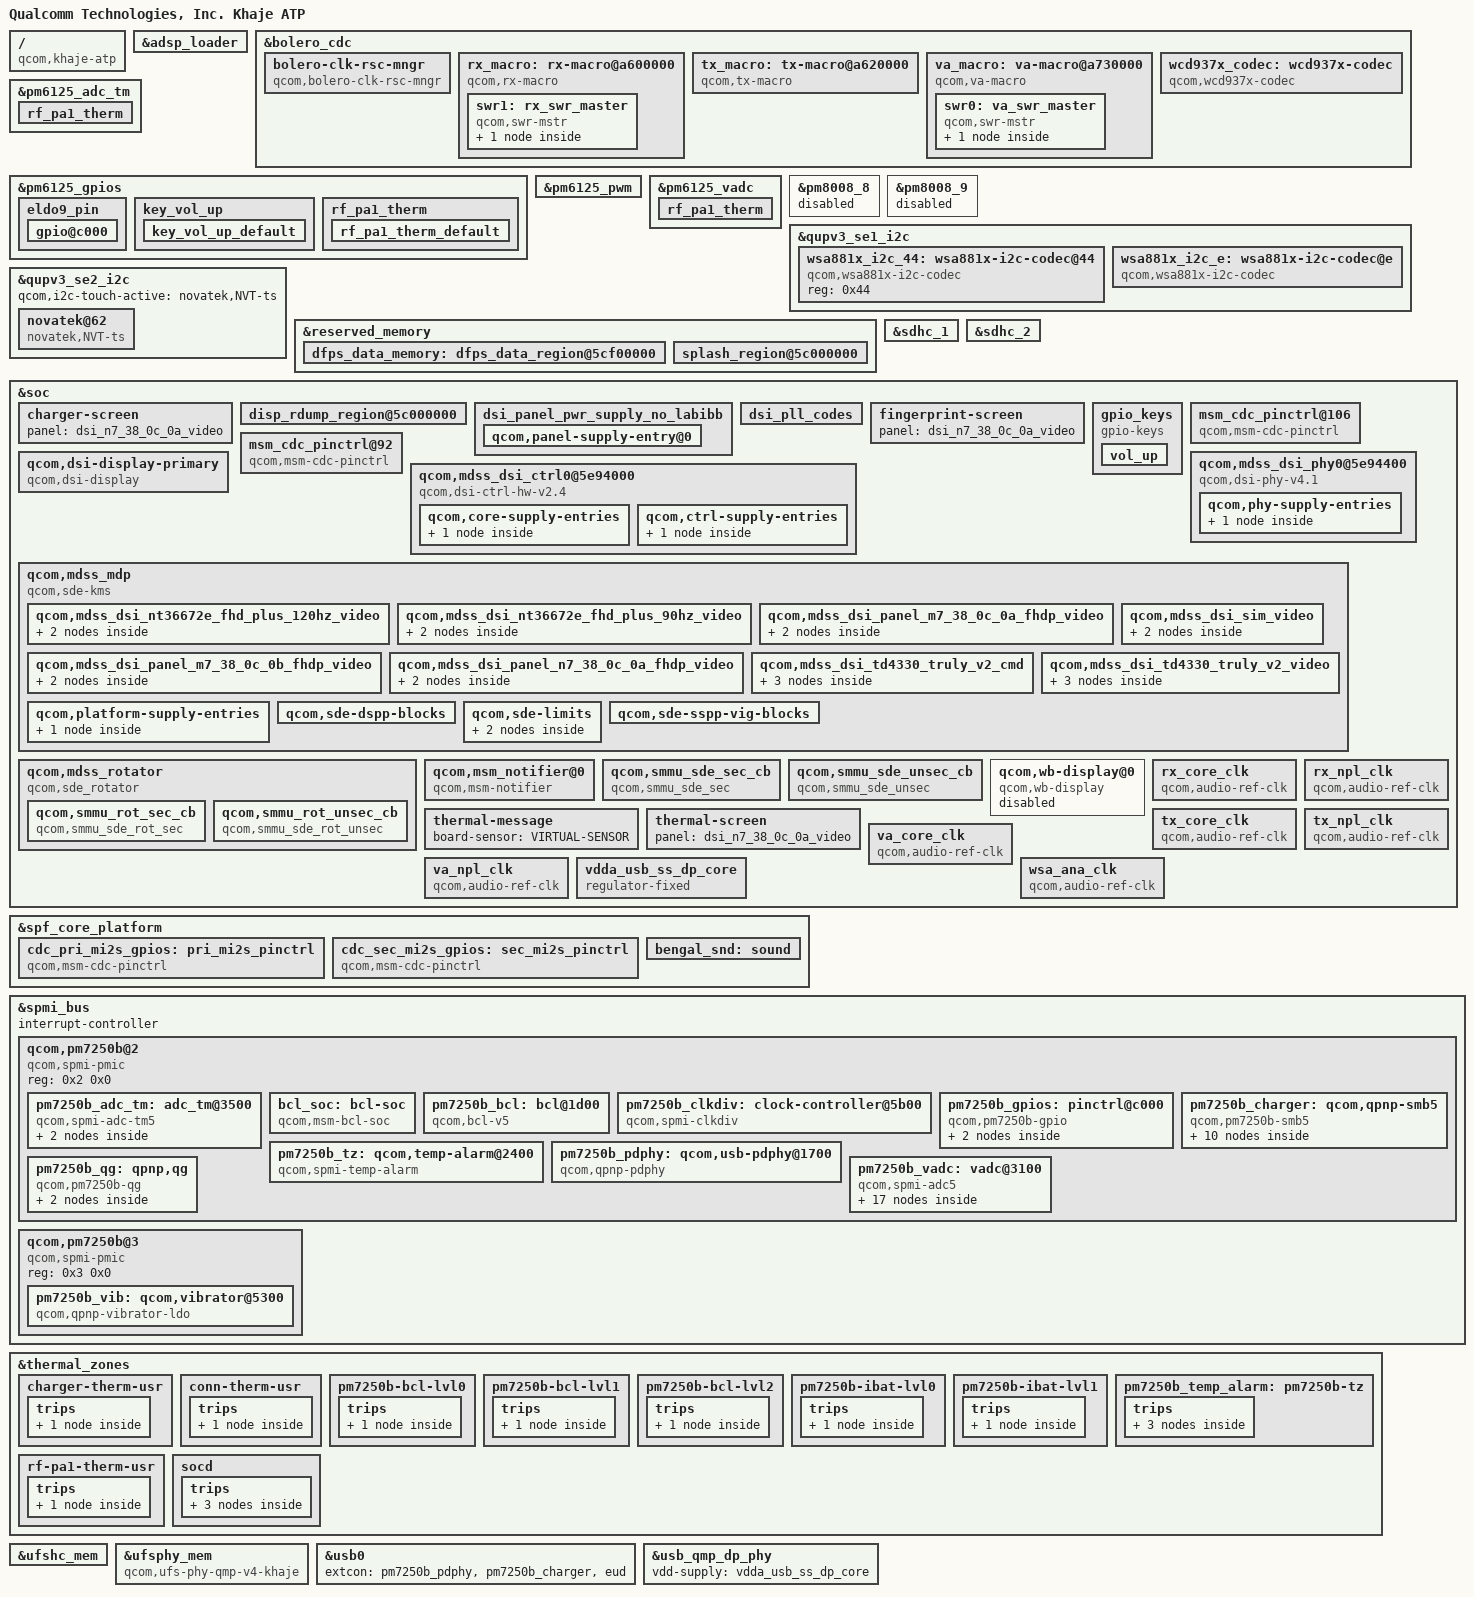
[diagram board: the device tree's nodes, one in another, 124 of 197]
/dts-v1/;

/ {
    compatible = "qcom,khaje-atp", "qcom,khaje", "qcom,atp";
    model = "Qualcomm Technologies, Inc. Khaje ATP";
    qcom,board-id = <0x21 0x0>;
    qcom,msm-id = <0x206 0x10000>;
    qcom,pmic-id = <0x2D 0x2E 0x0 0x0>;
};

&adsp_loader {
    adsp-fw-bit-values = <0x1>;
    adsp-fw-names = "adsp2";
    nvmem-cell-names = "adsp_variant";
    nvmem-cells = <&adsp_variant>;
};

&bolero_cdc {
    qcom,bolero-version = <0x5>;
    qcom,num-macros = <0x3>;
    bolero-clk-rsc-mngr {
        clock-names = "tx_core_clk", "tx_npl_clk", "rx_core_clk", "rx_npl_clk", "va_core_clk", "va_npl_clk";
        clocks = <&clock_audio_tx_1 0x0 &clock_audio_tx_2 0x0 &clock_audio_rx_1 0x0 &clock_audio_rx_2 0x0 &clock_audio_va_1 0x0 &clock_audio_va_2 0x0>;
        compatible = "qcom,bolero-clk-rsc-mngr";
        qcom,fs-gen-sequence = <0x3000 0x1 0x1 0x3004 0x3 0x3 0x3004 0x3 0x1 0x3080 0x2 0x2>;
        qcom,rx_mclk_mode_muxsel = <0xA5640D8>;
        qcom,va_mclk_mode_muxsel = "\nz";
    };
    rx_macro: rx-macro@a600000 {
        clock-names = "rx_core_clk", "rx_npl_clk";
        clocks = <&clock_audio_rx_1 0x0 &clock_audio_rx_2 0x0>;
        compatible = "qcom,rx-macro";
        qcom,default-clk-id = <0x0>;
        qcom,rx-bcl-pmic-params = [00 04 3E];
        qcom,rx-swr-gpios = <&rx_swr_gpios>;
        qcom,rx_mclk_mode_muxsel = <0xA5640D8>;
        reg = <0xA600000 0x0>;
        swr1: rx_swr_master {
            #address-cells = <0x2>;
            #size-cells = <0x0>;
            clock-names = "lpass_audio_hw_vote";
            clocks = <&lpass_audio_hw_vote 0x0>;
            compatible = "qcom,swr-mstr";
            interrupt-names = "swr_master_irq";
            interrupts = <0x0 0x129 0x4>;
            qcom,disable-div2-clk-switch = <0x1>;
            qcom,mipi-sdw-block-packing-mode = <0x1>;
            qcom,swr-clock-stop-mode0 = <0x1>;
            qcom,swr-master-version = <0x1060000>;
            qcom,swr-num-dev = <0x1>;
            qcom,swr-num-ports = <0x5>;
            qcom,swr-port-mapping = <0x1 0xE 0x1 0x1 0xF 0x2 0x2 0x12 0x1 0x3 0x10 0x1 0x3 0x11 0x2 0x4 0x13 0x1 0x5 0x14 0x1 0x5 0x15 0x2>;
            qcom,swr_master_id = <0x2>;
            qcom,swrm-hctl-reg = <0xA6A9098>;
            swrm-io-base = <0xA610000 0x0>;
            wcd937x_rx_slave: wcd937x-rx-slave {
                compatible = "qcom,wcd937x-slave";
                reg = <0xA 0x1170224>;
            };
        };
    };
    tx_macro: tx-macro@a620000 {
        clock-names = "tx_core_clk", "tx_npl_clk";
        clocks = <&clock_audio_tx_1 0x0 &clock_audio_tx_2 0x0>;
        compatible = "qcom,tx-macro";
        qcom,is-used-swr-gpio = <0x0>;
        qcom,tx-dmic-sample-rate = <0x249F00>;
        reg = <0xA620000 0x0>;
    };
    va_macro: va-macro@a730000 {
        clock-names = "lpass_audio_hw_vote";
        clocks = <&lpass_audio_hw_vote 0x0>;
        compatible = "qcom,va-macro";
        qcom,default-clk-id = <0x0>;
        qcom,is-used-swr-gpio = <0x1>;
        qcom,va-clk-mux-select = <0x1>;
        qcom,va-dmic-sample-rate = <0x927C0>;
        qcom,va-island-mode-muxsel = "\nz";
        qcom,va-swr-gpios = <&va_swr_gpios>;
        reg = <0xA730000 0x0>;
        swr0: va_swr_master {
            #address-cells = <0x2>;
            #size-cells = <0x0>;
            clock-names = "lpass_audio_hw_vote";
            clocks = <&lpass_audio_hw_vote 0x0>;
            compatible = "qcom,swr-mstr";
            interrupt-names = "swr_master_irq", "swr_wake_irq";
            interrupts = <0x0 0x128 0x4 0x0 0x4F 0x4>;
            qcom,is-always-on = <0x1>;
            qcom,mipi-sdw-block-packing-mode = <0x1>;
            qcom,swr-clock-stop-mode0 = <0x1>;
            qcom,swr-master-version = <0x1060000>;
            qcom,swr-mstr-irq-wakeup-capable = <0x1>;
            qcom,swr-num-dev = <0x1>;
            qcom,swr-num-ports = <0x3>;
            qcom,swr-port-mapping = <0x1 0x2E 0x1 0x1 0x2F 0x2 0x1 0x30 0x4 0x1 0x31 0x8 0x2 0x32 0x1 0x2 0x33 0x2 0x2 0x34 0x4 0x2 0x35 0x8 0x3 0x36 0x1 0x3 0x37 0x2 0x3 0x38 0x4 0x3 0x39 0x8>;
            qcom,swr-wakeup-required = <0x1>;
            qcom,swr_master_id = <0x3>;
            qcom,swrm-hctl-reg = <0xA7EC100>;
            swrm-io-base = <0xA740000 0x0>;
            wcd937x_tx_slave: wcd937x-tx-slave {
                compatible = "qcom,wcd937x-slave";
                reg = <0xA 0x1170223>;
            };
        };
    };
    wcd937x_codec: wcd937x-codec {
        cdc-vdd-buck-supply = <&L14A>;
        cdc-vdd-rxtx-supply = <&L9A>;
        cdc-vddpx-supply = <&L9A>;
        compatible = "qcom,wcd937x-codec";
        qcom,cdc-micbias1-mv = <0x708>;
        qcom,cdc-micbias2-mv = <0x708>;
        qcom,cdc-micbias3-mv = <0x708>;
        qcom,cdc-on-demand-supplies = "cdc-vdd-buck";
        qcom,cdc-static-supplies = "cdc-vdd-rxtx", "cdc-vddpx";
        qcom,cdc-vdd-buck-current = <0x9EB10>;
        qcom,cdc-vdd-buck-voltage = <0x1B7740 0x1B7740>;
        qcom,cdc-vdd-rxtx-current = <0x2710>;
        qcom,cdc-vdd-rxtx-voltage = <0x1B7740 0x1B7740>;
        qcom,cdc-vddpx-current = <0x4E20>;
        qcom,cdc-vddpx-voltage = <0x1B7740 0x1B7740>;
        qcom,rx-slave = <&wcd937x_rx_slave>;
        qcom,rx_swr_ch_map = <0x0 0xE 0x1 0x0 0xE 0x0 0xF 0x2 0x0 0xF 0x1 0x12 0x1 0x0 0x12 0x2 0x10 0x1 0x0 0x10 0x2 0x11 0x2 0x0 0x11 0x3 0x13 0x1 0x0 0x13 0x4 0x14 0x1 0x0 0x14 0x4 0x15 0x2 0x0 0x15>;
        qcom,split-codec = <0x1>;
        qcom,swr-tx-port-params = <0x1 0x0 0x0 0x1 0x1 0x0 0x1 0x0 0x0 0x1 0x1 0x0 0x1 0x0 0x1 0x0 0x0 0x1 0x2 0x0 0x1 0x0 0x2 0x0 0x1 0x0 0x1 0x0 0x1 0x0 0x1 0x0>;
        qcom,tx-slave = <&wcd937x_tx_slave>;
        qcom,tx_swr_ch_map = <0x0 0x1E 0x1 0x493E00 0x2E 0x1 0x1F 0x1 0x493E00 0x32 0x1 0x20 0x2 0x493E00 0x33 0x2 0x22 0x1 0x0 0x31 0x2 0x23 0x2 0x0 0x32 0x2 0x1D 0x4 0x493E00 0x33 0x3 0x24 0x1 0x0 0x34 0x3 0x25 0x2 0x0 0x35 0x3 0x26 0x4 0x0 0x36 0x3 0x27 0x8 0x0 0x37>;
        qcom,wcd-rst-gpio-node = <&wcd937x_rst_gpio>;
    };
};

&pm6125_adc_tm {
    status = "ok";
    rf_pa1_therm {
        io-channels = <&pm6125_vadc 0x55>;
        qcom,hw-settle-time-us = <0xC8>;
        qcom,ratiometric;
        reg = <0x3>;
    };
};

&pm6125_gpios {
    eldo9_pin {
        gpio@c000 {
            bias-disable;
            function = "normal";
            output-high;
            pins = "gpio1";
            power-source = <0x0>;
            qcom,drive-strength = <0x2>;
        };
    };
    key_vol_up {
        key_vol_up_default: key_vol_up_default {
            bias-pull-up;
            function = "normal";
            input-enable;
            pins = "gpio5";
            power-source = <0x0>;
        };
    };
    rf_pa1_therm {
        rf_pa1_therm_default: rf_pa1_therm_default {
            bias-high-impedance;
            pins = "gpio7";
        };
    };
};

&pm6125_pwm {
    status = "okay";
};

&pm6125_vadc {
    pinctrl-0 = <&camera_therm_default &emmc_therm_default &rf_pa1_therm_default>;
    rf_pa1_therm {
        label = "rf_pa1_therm";
        qcom,hw-settle-time = <0xC8>;
        qcom,pre-scaling = <0x1 0x1>;
        qcom,ratiometric;
        reg = <0x55>;
    };
};

&pm8008_8 {
    status = "disabled";
};

&pm8008_9 {
    status = "disabled";
};

&qupv3_se1_i2c {
    wsa881x_i2c_44: wsa881x-i2c-codec@44 {
        compatible = "qcom,wsa881x-i2c-codec";
        reg = <0x44>;
    };
    wsa881x_i2c_e: wsa881x-i2c-codec@e {
        clock-names = "wsa_mclk";
        clocks = <&wsa881x_analog_clk 0x0>;
        compatible = "qcom,wsa881x-i2c-codec";
        qcom,wsa-analog-clk-gpio = <&wsa881x_analog_clk_gpio>;
        qcom,wsa-analog-reset-gpio = <&wsa881x_analog_reset_gpio>;
        qcom,wsa-prefix = "SpkrMono";
        reg = <0xE>;
    };
};

&qupv3_se2_i2c {
    qcom,i2c-touch-active = "novatek,NVT-ts";
    status = "okay";
    novatek@62 {
        interrupt-parent = <&tlmm>;
        interrupts = <0x50 0x2008>;
        novatek,irq-gpio = <&tlmm 0x50 0x2008>;
        novatek,reset-gpio = <&tlmm 0x56 0x0>;
        pinctrl-0 = <&ts_int_active &ts_reset_active>;
        pinctrl-1 = <&ts_int_suspend &ts_reset_suspend>;
        pinctrl-2 = <&ts_release>;
        pinctrl-names = "pmx_ts_active", "pmx_ts_suspend", "pmx_ts_release";
        reg = <0x62>;
        status = "ok";
        compatible = "novatek,NVT-ts";
        panel = <&dsi_nt36672e_fhd_plus_90hz_video>;
    };
};

&reserved_memory {
    dfps_data_memory: dfps_data_region@5cf00000 {
        label = "dfps_data_region";
        reg = <0x0 0x5CF00000 0x0 0x100000>;
    };
    splash_region@5c000000 {
        label = "cont_splash_region";
        reg = <0x0 0x5C000000 0x0 0xF00000>;
    };
};

&sdhc_1 {
    pinctrl-0 = <&sdc1_on>;
    pinctrl-1 = <&sdc1_off>;
    pinctrl-names = "active", "sleep";
    qcom,vdd-current-level = <0x0 0x8B290>;
    qcom,vdd-io-always-on;
    qcom,vdd-io-current-level = <0x0 0x4F588>;
    qcom,vdd-io-lpm-sup;
    qcom,vdd-io-voltage-level = <0x1B7740 0x1B7740>;
    qcom,vdd-voltage-level = <0x2D2A80 0x2D2A80>;
    status = "ok";
    vdd-io-supply = <&L11A>;
    vdd-supply = <&L24A>;
};

&sdhc_2 {
    cd-gpios = <&tlmm 0x58 0x1>;
    pinctrl-0 = <&sdc2_on>;
    pinctrl-1 = <&sdc2_off>;
    pinctrl-names = "active", "sleep";
    qcom,vdd-current-level = <0x0 0xC3500>;
    qcom,vdd-io-bias-current-level = <0x0 0x1770>;
    qcom,vdd-io-bias-voltage-level = <0x132A40 0x132A40>;
    qcom,vdd-io-current-level = <0x0 0x55F0>;
    qcom,vdd-io-voltage-level = <0x1B7740 0x2D2A80>;
    qcom,vdd-voltage-level = <0x2D2A80 0x2D2A80>;
    status = "ok";
    vdd-io-bias-supply = <&L7A>;
    vdd-io-supply = <&L5A>;
    vdd-supply = <&L22A>;
};

&soc {
    charger-screen {
        panel = <&dsi_n7_38_0c_0a_video>;
    };
    disp_rdump_region@5c000000 {
        label = "disp_rdump_region";
        reg = <0x0 0x5C000000 0x0 0xF00000>;
    };
    dsi_panel_pwr_supply_no_labibb {
        #address-cells = <0x1>;
        #size-cells = <0x0>;
        qcom,panel-supply-entry@0 {
            qcom,supply-disable-load = <0x50>;
            qcom,supply-enable-load = <0xF230>;
            qcom,supply-max-voltage = <0x1B7740>;
            qcom,supply-min-voltage = <0x1B7740>;
            qcom,supply-name = "vddio";
            qcom,supply-post-on-sleep = <0x14>;
            reg = <0x0>;
        };
    };
    dsi_pll_codes {
        label = "dsi_pll_codes";
        reg = <0x0 0x0 0x0 0x0 0x0 0x0 0x0 0x0 0x0 0x0 0x0 0x0 0x0 0x0 0x0 0x0 0x0 0x0 0x0 0x0 0x0 0x0 0x0 0x0 0x0 0x0 0x0 0x0 0x0 0x0 0x0 0x0 0x0 0x0 0x0 0x0 0x0 0x0 0x0 0x0 0x0 0x0 0x0 0x0 0x0 0x0 0x0 0x0 0x0 0x0 0x0 0x0 0x0 0x0 0x0 0x0 0x0 0x0 0x0 0x0 0x0 0x0 0x0 0x0 0x0 0x0 0x0 0x0 0x0 0x0 0x0 0x0 0x0 0x0 0x0 0x0 0x0 0x0 0x0 0x0 0x0 0x0 0x0 0x0 0x0 0x0 0x0 0x0 0x0 0x0 0x0 0x0 0x0 0x0 0x0 0x0 0x0 0x0 0x0 0x0 0x0 0x0 0x0 0x0 0x0 0x0 0x0 0x0 0x0 0x0 0x0 0x0 0x0 0x0 0x0 0x0 0x0 0x0 0x0 0x0 0x0 0x0 0x0 0x0 0x0 0x0 0x0 0x0>;
    };
    fingerprint-screen {
        panel = <&dsi_n7_38_0c_0a_video>;
    };
    gpio_keys {
        compatible = "gpio-keys";
        label = "gpio-keys";
        pinctrl-0 = <&key_vol_up_default>;
        pinctrl-names = "default";
        vol_up {
            debounce-interval = <0xF>;
            gpio-key,wakeup;
            gpios = <&pm6125_gpios 0x5 0x1>;
            label = "volume_up";
            linux,can-disable;
            linux,code = <0x73>;
            linux,input-type = <0x1>;
        };
    };
    msm_cdc_pinctrl@106 {
        #gpio-cells = <0x0>;
        compatible = "qcom,msm-cdc-pinctrl";
        pinctrl-0 = <&spkr_1_sd_n_active>;
        pinctrl-1 = <&spkr_1_sd_n_sleep>;
        pinctrl-names = "aud_active", "aud_sleep";
    };
    msm_cdc_pinctrl@92 {
        #gpio-cells = <0x0>;
        compatible = "qcom,msm-cdc-pinctrl";
        pinctrl-0 = <&wcd937x_reset_active>;
        pinctrl-1 = <&wcd937x_reset_sleep>;
        pinctrl-names = "aud_active", "aud_sleep";
    };
    qcom,dsi-display-primary {
        clock-names = "pll_byte_clk0", "pll_dsi_clk0", "mdp_core_clk";
        clocks = <&mdss_dsi_phy0 0x0 &mdss_dsi_phy0 0x1 &dispcc 0x8>;
        compatible = "qcom,dsi-display";
        label = "primary";
        pinctrl-0 = <&sde_dsi_active &sde_te_active &disp_lcd_bias_en_default>;
        pinctrl-1 = <&sde_dsi_suspend &sde_te_suspend>;
        pinctrl-names = "panel_active", "panel_suspend";
        qcom,dsi-ctrl = <&mdss_dsi0>;
        qcom,dsi-default-panel = <&dsi_nt36672e_fhd_plus_90hz_video>;
        qcom,dsi-phy = <&mdss_dsi_phy0>;
        qcom,mdp = <&mdss_mdp>;
        qcom,panel-te-source = <0x0>;
        qcom,platform-te-gpio = <&tlmm 0x51 0x0>;
        vddio-supply = <&L9A>;
    };
    qcom,mdss_dsi_ctrl0@5e94000 {
        cell-index = <0x0>;
        clock-names = "byte_clk", "byte_clk_rcg", "byte_intf_clk", "pixel_clk", "pixel_clk_rcg", "esc_clk";
        clocks = <&dispcc 0x2 &dispcc 0x3 &dispcc 0x5 &dispcc 0xC &dispcc 0xD &dispcc 0x6>;
        compatible = "qcom,dsi-ctrl-hw-v2.4";
        frame-threshold-time-us = <0x3E8>;
        interrupt-parent = <&mdss_mdp>;
        interrupts = <0x4 0x0>;
        label = "dsi-ctrl-0";
        refgen-supply = <&refgen>;
        reg = <0x5E94000 0x400 0x5F08000 0x4 0x5E6B800 0x300>;
        reg-names = "dsi_ctrl", "disp_cc_base", "mdp_intf_base";
        vdda-1p2-supply = <&L18A>;
        qcom,core-supply-entries {
            #address-cells = <0x1>;
            #size-cells = <0x0>;
            qcom,core-supply-entry@0 {
                qcom,supply-disable-load = <0x0>;
                qcom,supply-enable-load = <0x0>;
                qcom,supply-max-voltage = <0x0>;
                qcom,supply-min-voltage = <0x0>;
                qcom,supply-name = "refgen";
                reg = <0x0>;
            };
        };
        qcom,ctrl-supply-entries {
            #address-cells = <0x1>;
            #size-cells = <0x0>;
            qcom,ctrl-supply-entry@0 {
                qcom,supply-disable-load = <0x0>;
                qcom,supply-enable-load = <0x5528>;
                qcom,supply-max-voltage = <0x124F80>;
                qcom,supply-min-voltage = <0x124F80>;
                qcom,supply-name = "vdda-1p2";
                reg = <0x0>;
            };
        };
    };
    qcom,mdss_dsi_phy0@5e94400 {
        #clock-cells = <0x1>;
        cell-index = <0x0>;
        compatible = "qcom,dsi-phy-v4.1";
        label = "dsi-phy-0";
        memory-region = <&dfps_data_memory>;
        pll-label = "dsi_pll_5nm";
        pll_codes_region = <&dsi_pll_codes_data>;
        qcom,dsi-pll-ssc-en;
        qcom,dsi-pll-ssc-mode = "down-spread";
        qcom,platform-lane-config = <0xA0A 0xA0A 0xA0A 0xA0A 0x8A8A>;
        qcom,platform-regulator-settings = [1D 1D 1D 1D 1D];
        qcom,platform-strength-ctrl = [55 03 55 03 55 03 55 03 55 00];
        reg = <0x5E94400 0x800 0x5E94900 0x264 0x5E94200 0x100>;
        reg-names = "dsi_phy", "pll_base", "dyn_refresh_base";
        vdda-0p9-supply = <&L4A>;
        qcom,phy-supply-entries {
            #address-cells = <0x1>;
            #size-cells = <0x0>;
            qcom,phy-supply-entry@0 {
                qcom,supply-disable-load = <0x0>;
                qcom,supply-enable-load = <0x8CA0>;
                qcom,supply-max-voltage = <0xD6D80>;
                qcom,supply-min-voltage = <0xD6D80>;
                qcom,supply-name = "vdda-0p9";
                reg = <0x0>;
            };
        };
    };
    qcom,mdss_mdp {
        #cooling-cells = <0x2>;
        #interrupt-cells = <0x1>;
        #list-cells = <0x1>;
        #power-domain-cells = <0x0>;
        clock-max-rate = <0x0 0x0 0x0 0x0 0x2160EC00 0x124F800 0x2160EC00>;
        clock-names = "gcc_bus", "throttle_clk", "div_clk", "iface_clk", "core_clk", "vsync_clk", "lut_clk";
        clock-rate = <0x0 0x0 0x0 0x0 0x16D41DC0 0x124F800 0x16D41DC0>;
        clocks = <&gcc 0x3E &gcc 0x40 &gcc 0x3D &dispcc 0x0 &dispcc 0x8 &dispcc 0x12 &dispcc 0xA>;
        compatible = "qcom,sde-kms";
        connectors = <&sde_dsi &smmu_sde_sec &smmu_sde_unsec>;
        interconnect-names = "qcom,sde-data-bus0", "qcom,sde-reg-bus";
        interconnects = <&mmrt_virt 0xE &bimc 0x200 &bimc 0x0 &config_noc 0x212>;
        interrupt-controller;
        interrupts = <0x0 0xBA 0x4>;
        qcom,sde-axi-bus-width = <0x10>;
        qcom,sde-cdp-setting = <0x1 0x1 0x1 0x0>;
        qcom,sde-csc-type = "csc-10bit";
        qcom,sde-ctl-display-pref = "primary";
        qcom,sde-ctl-off = <0x2000>;
        qcom,sde-ctl-size = <0x1DC>;
        qcom,sde-danger-lut = <0xFF 0xFFFF 0x0 0x0 0xFFFF>;
        qcom,sde-dither-off = <0x30E0>;
        qcom,sde-dither-size = <0x20>;
        qcom,sde-dither-version = <0x10000>;
        qcom,sde-dram-channels = <0x1>;
        qcom,sde-dsc-off = <0x81000>;
        qcom,sde-dsc-size = <0x140>;
        qcom,sde-dspp-off = <0x55000>;
        qcom,sde-dspp-rc-mem-size = <0xAA0>;
        qcom,sde-dspp-rc-off = <0x15800>;
        qcom,sde-dspp-rc-size = <0x100>;
        qcom,sde-dspp-rc-version = <0x10000>;
        qcom,sde-dspp-size = <0x1800>;
        qcom,sde-dspp-top-off = <0x1300>;
        qcom,sde-dspp-top-size = <0x80>;
        qcom,sde-has-cdp;
        qcom,sde-has-dim-layer;
        qcom,sde-has-idle-pc;
        qcom,sde-highest-bank-bit = <0x1>;
        qcom,sde-ib-bw-vote = <0x249F00 0x0 0x186A00>;
        qcom,sde-intf-off = <0x0 0x6B800>;
        qcom,sde-intf-size = <0x2C0>;
        qcom,sde-intf-tear-irq-off = <0x0 0x6E800>;
        qcom,sde-intf-type = "none", "dsi";
        qcom,sde-len = <0x494>;
        qcom,sde-max-bw-high-kbps = <0x419CE0>;
        qcom,sde-max-bw-low-kbps = <0x30D400>;
        qcom,sde-max-per-pipe-bw-high-kbps = <0x30D400 0x30D400>;
        qcom,sde-max-per-pipe-bw-kbps = <0x30D400 0x30D400>;
        qcom,sde-min-core-ib-kbps = <0x249F00>;
        qcom,sde-min-dram-ib-kbps = <0x186A00>;
        qcom,sde-min-llcc-ib-kbps = <0x0>;
        qcom,sde-mixer-blend-op-off = <0x20 0x38 0x50 0x68 0x80 0x98 0xB0 0xC8 0xE0 0xF8 0x110>;
        qcom,sde-mixer-blendstages = <0x4>;
        qcom,sde-mixer-display-pref = "primary";
        qcom,sde-mixer-linewidth = <0x800>;
        qcom,sde-mixer-off = <0x45000>;
        qcom,sde-mixer-pair-mask = <0x0>;
        qcom,sde-mixer-size = <0x320>;
        qcom,sde-mixer-stage-base-layer;
        qcom,sde-num-mnoc-ports = <0x1>;
        qcom,sde-num-nrt-paths = <0x0>;
        qcom,sde-off = <0x1000>;
        qcom,sde-panic-per-pipe;
        qcom,sde-pp-off = <0x71000>;
        qcom,sde-pp-size = <0xD4>;
        qcom,sde-qos-cpu-dma-latency = <0x12C>;
        qcom,sde-qos-cpu-irq-latency = <0x12C>;
        qcom,sde-qos-cpu-mask = <0x3>;
        qcom,sde-qos-lut-linear = <0x0 0x112222 0x22335777>;
        qcom,sde-qos-lut-macrotile = <0x0 0x112233 0x44556677>;
        qcom,sde-qos-lut-macrotile-qseed = <0x0 0x112233 0x66777777>;
        qcom,sde-qos-lut-nrt = <0x0 0x0 0x0>;
        qcom,sde-qseed-scalar-version = <0x3000>;
        qcom,sde-qseed-sw-lib-rev = "qseedv3lite";
        qcom,sde-reg-bus,vectors-KBps = <0x0 0x0 0x0 0x12C00 0x0 0x249F0 0x0 0x493E0>;
        qcom,sde-safe-lut-linear = <0x0 0xFFF0>;
        qcom,sde-safe-lut-macrotile = <0x0 0xFF00>;
        qcom,sde-safe-lut-macrotile-qseed = <0x0 0xFF00>;
        qcom,sde-safe-lut-nrt = <0x0 0xFFFF>;
        qcom,sde-secure-sid-mask = <0x421>;
        qcom,sde-smart-dma-rev = "smart_dma_v2p5";
        qcom,sde-sspp-clk-ctrl = <0x2AC 0x0 0x2AC 0x8>;
        qcom,sde-sspp-csc-off = <0x1A00>;
        qcom,sde-sspp-excl-rect = <0x1 0x1>;
        qcom,sde-sspp-linewidth = <0x870>;
        qcom,sde-sspp-off = <0x5000 0x25000>;
        qcom,sde-sspp-qseed-off = <0xA00>;
        qcom,sde-sspp-smart-dma-priority = <0x2 0x1>;
        qcom,sde-sspp-src-size = <0x1F8>;
        qcom,sde-sspp-type = "vig", "dma";
        qcom,sde-sspp-xin-id = <0x0 0x1>;
        qcom,sde-ubwc-static = <0x11F>;
        qcom,sde-ubwc-swizzle = <0x7>;
        qcom,sde-ubwc-version = <0x10000000>;
        qcom,sde-vbif-id = <0x0>;
        qcom,sde-vbif-memtype-0 = <0x3 0x3 0x3 0x3 0x3 0x3 0x3 0x3>;
        qcom,sde-vbif-memtype-1 = <0x3 0x3 0x3 0x3 0x3 0x3>;
        qcom,sde-vbif-off = <0x0>;
        qcom,sde-vbif-qos-nrt-remap = <0x3 0x3 0x3 0x3 0x3 0x3 0x3 0x3 0x3 0x3 0x3 0x3 0x3 0x3 0x3 0x3>;
        qcom,sde-vbif-qos-rt-remap = <0x3 0x3 0x4 0x4 0x5 0x5 0x6 0x6 0x3 0x3 0x4 0x4 0x5 0x5 0x6 0x6>;
        qcom,sde-vbif-size = <0x2008>;
        reg = <0x5E00000 0x8F030 0x5EB0000 0x2008 0x5E8F000 0x30>;
        reg-names = "mdp_phys", "vbif_phys", "sid_phys";
        sde-vdd-supply = <&mdss_core_gdsc>;
        qcom,mdss_dsi_nt36672e_fhd_plus_120hz_video {
            qcom,adjust-timer-wakeup-ms = <0x1>;
            qcom,dsi-ctrl-num = <0x0>;
            qcom,dsi-phy-num = <0x0>;
            qcom,dsi-select-clocks = "pll_byte_clk0", "pll_dsi_clk0";
            qcom,esd-check-enabled;
            qcom,mdss-dsi-bllp-eof-power-mode;
            qcom,mdss-dsi-bllp-power-mode;
            qcom,mdss-dsi-border-color = <0x0>;
            qcom,mdss-dsi-bpp = <0x18>;
            qcom,mdss-dsi-dma-trigger = "trigger_sw";
            qcom,mdss-dsi-lane-0-state;
            qcom,mdss-dsi-lane-1-state;
            qcom,mdss-dsi-lane-2-state;
            qcom,mdss-dsi-lane-3-state;
            qcom,mdss-dsi-mdp-trigger = "none";
            qcom,mdss-dsi-panel-blackness-level = <0x1361>;
            qcom,mdss-dsi-panel-hdr-color-primaries = <0x3A98 0x3E80 0x83D6 0x3DB8 0x33C2 0x8692 0x1D4C 0xBB8>;
            qcom,mdss-dsi-panel-hdr-enabled;
            qcom,mdss-dsi-panel-name = "nt36672e fhd plus 120Hz Video panel";
            qcom,mdss-dsi-panel-peak-brightness = <0x626B50>;
            qcom,mdss-dsi-panel-status-check-mode = "reg_read";
            qcom,mdss-dsi-panel-status-command = <0x6010001 0x10A>;
            qcom,mdss-dsi-panel-status-command-state = "dsi_lp_mode";
            qcom,mdss-dsi-panel-status-read-length = <0x1>;
            qcom,mdss-dsi-panel-status-value = <0x9C>;
            qcom,mdss-dsi-panel-type = "dsi_video_mode";
            qcom,mdss-dsi-reset-sequence = <0x1 0xA 0x0 0xA 0x1 0xA>;
            qcom,mdss-dsi-stream = <0x0>;
            qcom,mdss-dsi-traffic-mode = "burst_mode";
            qcom,mdss-dsi-tx-eot-append;
            qcom,mdss-dsi-virtual-channel-id = <0x0>;
            qcom,mdss-dsi-display-timings {
                timing@0 {
                    qcom,compression-mode = "dsc";
                    qcom,default-topology-index = <0x0>;
                    qcom,display-topology = <0x1 0x1 0x1>;
                    qcom,mdss-dsc-bit-per-component = <0x8>;
                    qcom,mdss-dsc-bit-per-pixel = <0x8>;
                    qcom,mdss-dsc-block-prediction-enable;
                    qcom,mdss-dsc-slice-height = <0x8>;
                    qcom,mdss-dsc-slice-per-pkt = <0x1>;
                    qcom,mdss-dsc-slice-width = <0x21C>;
                    qcom,mdss-dsi-h-back-porch = <0x3C>;
                    qcom,mdss-dsi-h-front-porch = <0x4C>;
                    qcom,mdss-dsi-h-pulse-width = <0xA>;
                    qcom,mdss-dsi-h-sync-skew = <0x0>;
                    qcom,mdss-dsi-off-command = <0x5010000 0x10000128 0x5010000 0x32000110>;
                    qcom,mdss-dsi-off-command-state = "dsi_lp_mode";
                    qcom,mdss-dsi-on-command = [15 01 00 00 00 00 02 FB 01 15 01 00 00 00 00 02 B0 00 15 01 00 00 00 00 02 C0 03 39 01 00 00 00 00 11 C1 89 28 00 08 00 AA 02 0E 00 2B 00 07 0D B7 0C B7 39 01 00 00 00 00 03 C2 1B A0 15 01 00 00 00 00 02 FF 20 15 01 00 00 00 00 02 FB 01 15 01 00 00 00 00 02 01 66 15 01 00 00 00 00 02 06 40 15 01 00 00 00 00 02 07 38 15 01 00 00 00 00 02 2F 83 15 01 00 00 00 00 02 69 91 15 01 00 00 00 00 02 95 D1 15 01 00 00 00 00 02 96 D1 15 01 00 00 00 00 02 F2 64 15 01 00 00 00 00 02 F4 64 15 01 00 00 00 00 02 F6 64 15 01 00 00 00 00 02 F8 64 15 01 00 00 00 00 02 89 1C 15 01 00 00 00 00 02 8A 1C 15 01 00 00 00 00 02 8B 1C 15 01 00 00 00 00 02 8C 1C 15 01 00 00 00 00 02 FF 24 15 01 00 00 00 00 02 FB 01 15 01 00 00 00 00 02 01 0F 15 01 00 00 00 00 02 03 0C 15 01 00 00 00 00 02 05 1D 15 01 00 00 00 00 02 08 2F 15 01 00 00 00 00 02 09 2E 15 01 00 00 00 00 02 0A 2D 15 01 00 00 00 00 02 0B 2C 15 01 00 00 00 00 02 11 17 15 01 00 00 00 00 02 12 13 15 01 00 00 00 00 02 13 15 15 01 00 00 00 00 02 15 14 15 01 00 00 00 00 02 16 16 15 01 00 00 00 00 02 17 18 15 01 00 00 00 00 02 1B 01 15 01 00 00 00 00 02 1D 1D 15 01 00 00 00 00 02 20 2F 15 01 00 00 00 00 02 21 2E 15 01 00 00 00 00 02 22 2D 15 01 00 00 00 00 02 23 2C 15 01 00 00 00 00 02 29 17 15 01 00 00 00 00 02 2A 13 15 01 00 00 00 00 02 2B 15 15 01 00 00 00 00 02 2F 14 15 01 00 00 00 00 02 30 16 15 01 00 00 00 00 02 31 18 15 01 00 00 00 00 02 32 04 15 01 00 00 00 00 02 34 10 15 01 00 00 00 00 02 35 1F 15 01 00 00 00 00 02 36 1F 15 01 00 00 00 00 02 4D 14 15 01 00 00 00 00 02 4E 36 15 01 00 00 00 00 02 4F 36 15 01 00 00 00 00 02 53 36 15 01 00 00 00 00 02 71 30 15 01 00 00 00 00 02 79 11 15 01 00 00 00 00 02 7A 82 15 01 00 00 00 00 02 7B 8F 15 01 00 00 00 00 02 7D 04 15 01 00 00 00 00 02 80 04 15 01 00 00 00 00 02 81 04 15 01 00 00 00 00 02 82 13 15 01 00 00 00 00 02 84 31 15 01 00 00 00 00 02 85 00 15 01 00 00 00 00 02 86 00 15 01 00 00 00 00 02 87 00 15 01 00 00 00 00 02 90 13 15 01 00 00 00 00 02 92 31 15 01 00 00 00 00 02 93 00 15 01 00 00 00 00 02 94 00 15 01 00 00 00 00 02 95 00 15 01 00 00 00 00 02 9C F4 15 01 00 00 00 00 02 9D 01 15 01 00 00 00 00 02 A0 0F 15 01 00 00 00 00 02 A2 0F 15 01 00 00 00 00 02 A3 02 15 01 00 00 00 00 02 A4 04 15 01 00 00 00 00 02 A5 04 15 01 00 00 00 00 02 C4 40 15 01 00 00 00 00 02 C6 C0 15 01 00 00 00 00 02 C9 00 15 01 00 00 00 00 02 D9 80 15 01 00 00 00 00 02 E9 02 15 01 00 00 00 00 02 FF 25 15 01 00 00 00 00 02 FB 01 15 01 00 00 00 00 02 19 E4 15 01 00 00 00 00 02 21 40 15 01 00 00 00 00 02 66 D8 15 01 00 00 00 00 02 68 50 15 01 00 00 00 00 02 69 10 15 01 00 00 00 00 02 6B 00 15 01 00 00 00 00 02 6D 0D 15 01 00 00 00 00 02 6E 48 15 01 00 00 00 00 02 72 41 15 01 00 00 00 00 02 73 4A 15 01 00 00 00 00 02 74 D0 15 01 00 00 00 00 02 77 62 15 01 00 00 00 00 02 79 81 15 01 00 00 00 00 02 7D 03 15 01 00 00 00 00 02 7E 15 15 01 00 00 00 00 02 7F 00 15 01 00 00 00 00 02 84 4D 15 01 00 00 00 00 02 CF 80 15 01 00 00 00 00 02 D6 80 15 01 00 00 00 00 02 D7 80 15 01 00 00 00 00 02 EF 20 15 01 00 00 00 00 02 F0 84 15 01 00 00 00 00 02 FF 26 15 01 00 00 00 00 02 FB 01 15 01 00 00 00 00 02 80 05 15 01 00 00 00 00 02 81 0F 15 01 00 00 00 00 02 83 01 15 01 00 00 00 00 02 84 03 15 01 00 00 00 00 02 85 01 15 01 00 00 00 00 02 86 03 15 01 00 00 00 00 02 87 01 15 01 00 00 00 00 02 88 05 15 01 00 00 00 00 02 8A 1A 15 01 00 00 00 00 02 8B 11 15 01 00 00 00 00 02 8C 24 15 01 00 00 00 00 02 8E 42 15 01 00 00 00 00 02 8F 11 15 01 00 00 00 00 02 90 11 15 01 00 00 00 00 02 91 11 15 01 00 00 00 00 02 9A 80 15 01 00 00 00 00 02 9B 04 15 01 00 00 00 00 02 9C 00 15 01 00 00 00 00 02 9D 00 15 01 00 00 00 00 02 9E 00 15 01 00 00 00 00 02 FF 27 15 01 00 00 00 00 02 FB 01 15 01 00 00 00 00 02 01 68 15 01 00 00 00 00 02 20 81 15 01 00 00 00 00 02 21 6A 15 01 00 00 00 00 02 25 81 15 01 00 00 00 00 02 26 94 15 01 00 00 00 00 02 6E 00 15 01 00 00 00 00 02 6F 00 15 01 00 00 00 00 02 70 00 15 01 00 00 00 00 02 71 00 15 01 00 00 00 00 02 72 00 15 01 00 00 00 00 02 75 00 15 01 00 00 00 00 02 76 00 15 01 00 00 00 00 02 77 00 15 01 00 00 00 00 02 7D 09 15 01 00 00 00 00 02 7E 67 15 01 00 00 00 00 02 80 23 15 01 00 00 00 00 02 82 09 15 01 00 00 00 00 02 83 67 15 01 00 00 00 00 02 88 01 15 01 00 00 00 00 02 89 10 15 01 00 00 00 00 02 A5 10 15 01 00 00 00 00 02 A6 23 15 01 00 00 00 00 02 A7 01 15 01 00 00 00 00 02 B6 40 15 01 00 00 00 00 02 FF 2A 15 01 00 00 00 00 02 FB 01 15 01 00 00 00 00 02 00 91 15 01 00 00 00 00 02 03 20 15 01 00 00 00 00 02 07 50 15 01 00 00 00 00 02 0A 70 15 01 00 00 00 00 02 0C 04 15 01 00 00 00 00 02 0D 40 15 01 00 00 00 00 02 0F 01 15 01 00 00 00 00 02 11 E0 15 01 00 00 00 00 02 15 0F 15 01 00 00 00 00 02 16 A4 15 01 00 00 00 00 02 19 0F 15 01 00 00 00 00 02 1A 78 15 01 00 00 00 00 02 1B 23 15 01 00 00 00 00 02 1D 36 15 01 00 00 00 00 02 1E 3E 15 01 00 00 00 00 02 1F 3E 15 01 00 00 00 00 02 20 3E 15 01 00 00 00 00 02 28 FD 15 01 00 00 00 00 02 29 12 15 01 00 00 00 00 02 2A E1 15 01 00 00 00 00 02 2D 0A 15 01 00 00 00 00 02 30 49 15 01 00 00 00 00 02 33 96 15 01 00 00 00 00 02 34 FF 15 01 00 00 00 00 02 35 40 15 01 00 00 00 00 02 36 DE 15 01 00 00 00 00 02 37 F9 15 01 00 00 00 00 02 38 45 15 01 00 00 00 00 02 39 D9 15 01 00 00 00 00 02 3A 49 15 01 00 00 00 00 02 4A F0 15 01 00 00 00 00 02 FF 20 15 01 00 00 00 00 02 FB 01 39 01 00 00 00 00 11 B0 00 00 00 17 00 46 00 63 00 81 00 96 00 AB 00 BD 39 01 00 00 00 00 11 B1 00 CF 01 03 01 2F 01 6E 01 9D 01 E7 02 22 02 24 39 01 00 00 00 00 11 B2 02 5D 02 9B 02 C4 02 F9 03 1B 03 48 03 56 03 65 39 01 00 00 00 00 0F B3 03 75 03 87 03 9B 03 B1 03 CA 03 D7 00 00 39 01 00 00 00 00 11 B4 00 00 00 19 00 4B 00 69 00 87 00 9C 00 B2 00 C3 39 01 00 00 00 00 11 B5 00 D5 01 0B 01 35 01 73 01 A3 01 EC 02 27 02 29 39 01 00 00 00 00 11 B6 02 60 02 9F 02 C7 02 FB 03 1D 03 4C 03 5A 03 69 39 01 00 00 00 00 0F B7 03 7A 03 8C 03 A0 03 B5 03 CB 03 D7 00 00 39 01 00 00 00 00 11 B8 00 00 00 19 00 4D 00 6A 00 87 00 9C 00 B1 00 C2 39 01 00 00 00 00 11 B9 00 D3 01 08 01 32 01 70 01 9F 01 E8 02 23 02 25 39 01 00 00 00 00 11 BA 02 5C 02 9B 02 C3 02 F8 03 1A 03 4C 03 5B 03 6B 39 01 00 00 00 00 0F BB 03 7D 03 92 03 A7 03 BB 03 CE 03 D7 00 00 15 01 00 00 00 00 02 FF 21 15 01 00 00 00 00 02 FB 01 39 01 00 00 00 00 11 B0 00 00 00 17 00 46 00 63 00 81 00 96 00 AB 00 BD 39 01 00 00 00 00 11 B1 00 CF 01 03 01 2F 01 6E 01 9D 01 E7 02 22 02 24 39 01 00 00 00 00 11 B2 02 5D 02 9B 02 C4 02 F9 03 1B 03 48 03 56 03 65 39 01 00 00 00 00 0F B3 03 75 03 87 03 9B 03 B1 03 CA 03 D7 00 00 39 01 00 00 00 00 11 B4 00 00 00 19 00 4B 00 69 00 87 00 9C 00 B2 00 C3 39 01 00 00 00 00 11 B5 00 D5 01 0B 01 35 01 73 01 A3 01 EC 02 27 02 29 39 01 00 00 00 00 11 B6 02 60 02 9F 02 C7 02 FB 03 1D 03 4C 03 5A 03 69 39 01 00 00 00 00 0F B7 03 7A 03 8C 03 A0 03 B5 03 CB 03 D7 00 00 39 01 00 00 00 00 11 B8 00 00 00 19 00 4D 00 6A 00 87 00 9C 00 B1 00 C2 39 01 00 00 00 00 11 B9 00 D3 01 08 01 32 01 70 01 9F 01 E8 02 23 02 25 39 01 00 00 00 00 11 BA 02 5C 02 9B 02 C3 02 F8 03 1A 03 4C 03 5B 03 6B 39 01 00 00 00 00 0F BB 03 7D 03 92 03 A7 03 BB 03 CE 03 D7 00 00 15 01 00 00 00 00 02 FF 10 15 01 00 00 00 00 02 FF F0 15 01 00 00 00 00 02 FB 01 15 01 00 00 00 00 02 5A 00 15 01 00 00 00 00 02 FF 10 15 01 00 00 00 00 02 FF 10 15 01 00 00 00 00 02 FB 01 15 01 00 00 00 00 02 51 FF 15 01 00 00 00 00 02 53 2C 15 01 00 00 00 00 02 55 01 05 01 00 00 C8 00 01 11 05 01 00 00 96 00 01 29];
                    qcom,mdss-dsi-on-command-state = "dsi_lp_mode";
                    qcom,mdss-dsi-panel-framerate = <0x78>;
                    qcom,mdss-dsi-panel-height = <0x968>;
                    qcom,mdss-dsi-panel-phy-timings = [00 1E 08 08 24 22 08 08 08 02 04 00 1B 18];
                    qcom,mdss-dsi-panel-width = <0x438>;
                    qcom,mdss-dsi-v-back-porch = <0xA>;
                    qcom,mdss-dsi-v-front-porch = <0x2E>;
                    qcom,mdss-dsi-v-pulse-width = <0xA>;
                };
            };
        };
        qcom,mdss_dsi_nt36672e_fhd_plus_90hz_video {
            pwms = <&pm6125_pwm 0x0 0x0>;
            qcom,adjust-timer-wakeup-ms = <0x1>;
            qcom,bl-pmic-pwm-period-usecs = <0x64>;
            qcom,dsi-ctrl-num = <0x0>;
            qcom,dsi-phy-num = <0x0>;
            qcom,dsi-select-clocks = "pll_byte_clk0", "pll_dsi_clk0";
            qcom,mdss-dsi-bl-max-level = <0xFFF>;
            qcom,mdss-dsi-bl-min-level = <0x1>;
            qcom,mdss-dsi-bl-pmic-control-type = "bl_ctrl_pwm";
            qcom,mdss-dsi-bllp-eof-power-mode;
            qcom,mdss-dsi-bllp-power-mode;
            qcom,mdss-dsi-border-color = <0x0>;
            qcom,mdss-dsi-bpp = <0x18>;
            qcom,mdss-dsi-dma-trigger = "trigger_sw";
            qcom,mdss-dsi-lane-0-state;
            qcom,mdss-dsi-lane-1-state;
            qcom,mdss-dsi-lane-2-state;
            qcom,mdss-dsi-lane-3-state;
            qcom,mdss-dsi-mdp-trigger = "none";
            qcom,mdss-dsi-panel-blackness-level = <0x1361>;
            qcom,mdss-dsi-panel-hdr-color-primaries = <0x9858 0x3E80 0x83D6 0x9B78 0x33C2 0x8692 0x1D4C 0xBB8>;
            qcom,mdss-dsi-panel-hdr-enabled;
            qcom,mdss-dsi-panel-name = "nt36672e 90Hz fhd plus video mode panel with DSC";
            qcom,mdss-dsi-panel-peak-brightness = <0x626B50>;
            qcom,mdss-dsi-panel-status-check-mode = "reg_read";
            qcom,mdss-dsi-panel-status-command = <0x6010001 0x10A>;
            qcom,mdss-dsi-panel-status-command-state = "dsi_lp_mode";
            qcom,mdss-dsi-panel-status-read-length = <0x1>;
            qcom,mdss-dsi-panel-status-value = <0x9C>;
            qcom,mdss-dsi-panel-type = "dsi_video_mode";
            qcom,mdss-dsi-reset-sequence = <0x1 0xA 0x0 0xA 0x1 0xA>;
            qcom,mdss-dsi-stream = <0x0>;
            qcom,mdss-dsi-traffic-mode = "burst_mode";
            qcom,mdss-dsi-tx-eot-append;
            qcom,mdss-dsi-virtual-channel-id = <0x0>;
            qcom,panel-supply-entries = <&dsi_panel_pwr_supply_no_labibb>;
            qcom,platform-bklight-en-gpio = <&pm7250b_gpios 0x1 0x0>;
            qcom,platform-en-gpio = <&pm7250b_gpios 0x5 0x0>;
            qcom,platform-reset-gpio = <&tlmm 0x52 0x0>;
            qcom,mdss-dsi-display-timings {
                timing@0 {
                    cell-index = <0x0>;
                    qcom,compression-mode = "dsc";
                    qcom,default-topology-index = <0x0>;
                    qcom,display-topology = <0x1 0x1 0x1>;
                    qcom,mdss-dsc-bit-per-component = <0x8>;
                    qcom,mdss-dsc-bit-per-pixel = <0x8>;
                    qcom,mdss-dsc-block-prediction-enable;
                    qcom,mdss-dsc-slice-height = <0x8>;
                    qcom,mdss-dsc-slice-per-pkt = <0x1>;
                    qcom,mdss-dsc-slice-width = <0x21C>;
                    qcom,mdss-dsi-h-back-porch = <0x44>;
                    qcom,mdss-dsi-h-front-porch = <0x4C>;
                    qcom,mdss-dsi-h-pulse-width = <0xA>;
                    qcom,mdss-dsi-h-sync-skew = <0x0>;
                    qcom,mdss-dsi-off-command = <0x5010000 0x10000128 0x5010000 0x32000110>;
                    qcom,mdss-dsi-off-command-state = "dsi_lp_mode";
                    qcom,mdss-dsi-on-command = [39 01 00 00 00 00 02 FF 10 39 01 00 00 00 00 02 FB 01 39 01 00 00 00 00 02 B0 00 39 01 00 00 00 00 02 C0 03 39 01 00 00 00 00 11 C1 89 28 00 08 00 AA 02 0E 00 2B 00 07 0D B7 0C B7 39 01 00 00 00 00 03 C2 1B A0 39 01 00 00 00 00 02 FF 20 39 01 00 00 00 00 02 FB 01 39 01 00 00 00 00 02 01 66 39 01 00 00 00 00 02 06 40 39 01 00 00 00 00 02 07 38 39 01 00 00 00 00 02 18 66 39 01 00 00 00 00 02 1B 01 39 01 00 00 00 00 02 5C 90 39 01 00 00 00 00 02 5E AA 39 01 00 00 00 00 02 69 91 39 01 00 00 00 00 02 89 0D 39 01 00 00 00 00 02 8A 0D 39 01 00 00 00 00 02 8D 0D 39 01 00 00 00 00 02 8E 0D 39 01 00 00 00 00 02 8F 0D 39 01 00 00 00 00 02 91 0D 39 01 00 00 00 00 02 95 D1 39 01 00 00 00 00 02 96 D1 39 01 00 00 00 00 02 F2 65 39 01 00 00 00 00 02 F3 64 39 01 00 00 00 00 02 F4 65 39 01 00 00 00 00 02 F5 64 39 01 00 00 00 00 02 F6 65 39 01 00 00 00 00 02 F7 64 39 01 00 00 00 00 02 F8 65 39 01 00 00 00 00 02 F9 64 39 01 00 00 00 00 02 FF 24 39 01 00 00 00 00 02 FB 01 39 01 00 00 00 00 02 01 0F 39 01 00 00 00 00 02 03 0C 39 01 00 00 00 00 02 05 1D 39 01 00 00 00 00 02 08 2F 39 01 00 00 00 00 02 09 2E 39 01 00 00 00 00 02 0A 2D 39 01 00 00 00 00 02 0B 2C 39 01 00 00 00 00 02 11 17 39 01 00 00 00 00 02 12 13 39 01 00 00 00 00 02 13 15 39 01 00 00 00 00 02 15 14 39 01 00 00 00 00 02 16 16 39 01 00 00 00 00 02 17 18 39 01 00 00 00 00 02 1B 01 39 01 00 00 00 00 02 1D 1D 39 01 00 00 00 00 02 20 2F 39 01 00 00 00 00 02 21 2E 39 01 00 00 00 00 02 22 2D 39 01 00 00 00 00 02 23 2C 39 01 00 00 00 00 02 29 17 39 01 00 00 00 00 02 2A 13 39 01 00 00 00 00 02 2B 15 39 01 00 00 00 00 02 2F 14 39 01 00 00 00 00 02 30 16 39 01 00 00 00 00 02 31 18 39 01 00 00 00 00 02 32 04 39 01 00 00 00 00 02 34 10 39 01 00 00 00 00 02 35 1F 39 01 00 00 00 00 02 36 1F 39 01 00 00 00 00 02 4D 19 39 01 00 00 00 00 02 4E 45 39 01 00 00 00 00 02 4F 45 39 01 00 00 00 00 02 53 45 39 01 00 00 00 00 02 71 30 39 01 00 00 00 00 02 79 11 39 01 00 00 00 00 02 7A 82 39 01 00 00 00 00 02 7B 94 39 01 00 00 00 00 02 7D 04 39 01 00 00 00 00 02 80 04 39 01 00 00 00 00 02 81 04 39 01 00 00 00 00 02 82 13 39 01 00 00 00 00 02 84 31 39 01 00 00 00 00 02 85 00 39 01 00 00 00 00 02 86 00 39 01 00 00 00 00 02 87 00 39 01 00 00 00 00 02 90 13 39 01 00 00 00 00 02 92 31 39 01 00 00 00 00 02 93 00 39 01 00 00 00 00 02 94 00 39 01 00 00 00 00 02 95 00 39 01 00 00 00 00 02 9C F4 39 01 00 00 00 00 02 9D 01 39 01 00 00 00 00 02 A0 14 39 01 00 00 00 00 02 A2 14 39 01 00 00 00 00 02 A3 02 39 01 00 00 00 00 02 A4 04 39 01 00 00 00 00 02 A5 04 39 01 00 00 00 00 02 C4 40 39 01 00 00 00 00 02 C6 C0 39 01 00 00 00 00 02 C9 00 39 01 00 00 00 00 02 D9 80 39 01 00 00 00 00 02 E9 02 39 01 00 00 00 00 02 FF 25 39 01 00 00 00 00 02 FB 01 39 01 00 00 00 00 02 0F 1B 39 01 00 00 00 00 02 19 E4 39 01 00 00 00 00 02 21 40 39 01 00 00 00 00 02 66 D8 39 01 00 00 00 00 02 68 50 39 01 00 00 00 00 02 69 10 39 01 00 00 00 00 02 6B 00 39 01 00 00 00 00 02 6D 0D 39 01 00 00 00 00 02 6E 48 39 01 00 00 00 00 02 72 41 39 01 00 00 00 00 02 73 4A 39 01 00 00 00 00 02 74 D0 39 01 00 00 00 00 02 77 62 39 01 00 00 00 00 02 79 7F 39 01 00 00 00 00 02 7D 40 39 01 00 00 00 00 02 7F 00 39 01 00 00 00 00 02 80 04 39 01 00 00 00 00 02 84 0D 39 01 00 00 00 00 02 CF 80 39 01 00 00 00 00 02 D6 80 39 01 00 00 00 00 02 D7 80 39 01 00 00 00 00 02 EF 20 39 01 00 00 00 00 02 F0 84 39 01 00 00 00 00 02 FF 26 39 01 00 00 00 00 02 FB 01 39 01 00 00 00 00 02 15 04 39 01 00 00 00 00 02 81 14 39 01 00 00 00 00 02 83 02 39 01 00 00 00 00 02 84 03 39 01 00 00 00 00 02 85 01 39 01 00 00 00 00 02 86 03 39 01 00 00 00 00 02 87 01 39 01 00 00 00 00 02 88 06 39 01 00 00 00 00 02 8A 1A 39 01 00 00 00 00 02 8B 11 39 01 00 00 00 00 02 8C 24 39 01 00 00 00 00 02 8E 42 39 01 00 00 00 00 02 8F 11 39 01 00 00 00 00 02 90 11 39 01 00 00 00 00 02 91 11 39 01 00 00 00 00 02 9A 81 39 01 00 00 00 00 02 9B 03 39 01 00 00 00 00 02 9C 00 39 01 00 00 00 00 02 9D 00 39 01 00 00 00 00 02 9E 00 39 01 00 00 00 00 02 FF 27 39 01 00 00 00 00 02 FB 01 39 01 00 00 00 00 02 01 68 39 01 00 00 00 00 02 20 81 39 01 00 00 00 00 02 21 EA 39 01 00 00 00 00 02 25 82 39 01 00 00 00 00 02 26 1F 39 01 00 00 00 00 02 6E 00 39 01 00 00 00 00 02 6F 00 39 01 00 00 00 00 02 70 00 39 01 00 00 00 00 02 71 00 39 01 00 00 00 00 02 72 00 39 01 00 00 00 00 02 75 00 39 01 00 00 00 00 02 76 00 39 01 00 00 00 00 02 77 00 39 01 00 00 00 00 02 7D 09 39 01 00 00 00 00 02 7E 67 39 01 00 00 00 00 02 80 23 39 01 00 00 00 00 02 82 09 39 01 00 00 00 00 02 83 67 39 01 00 00 00 00 02 88 01 39 01 00 00 00 00 02 89 10 39 01 00 00 00 00 02 A5 10 39 01 00 00 00 00 02 A6 23 39 01 00 00 00 00 02 A7 01 39 01 00 00 00 00 02 B6 40 39 01 00 00 00 00 02 E3 02 39 01 00 00 00 00 02 E4 E0 39 01 00 00 00 00 02 E5 01 39 01 00 00 00 00 02 E6 70 39 01 00 00 00 00 02 E9 03 39 01 00 00 00 00 02 EA 2F 39 01 00 00 00 00 02 EB 01 39 01 00 00 00 00 02 EC 98 39 01 00 00 00 00 02 FF 2A 39 01 00 00 00 00 02 FB 01 39 01 00 00 00 00 02 00 91 39 01 00 00 00 00 02 03 20 39 01 00 00 00 00 02 07 5A 39 01 00 00 00 00 02 0A 70 39 01 00 00 00 00 02 0D 40 39 01 00 00 00 00 02 0E 02 39 01 00 00 00 00 02 11 F0 39 01 00 00 00 00 02 15 0F 39 01 00 00 00 00 02 16 65 39 01 00 00 00 00 02 19 0F 39 01 00 00 00 00 02 1A 39 39 01 00 00 00 00 02 1B 14 39 01 00 00 00 00 02 1D 36 39 01 00 00 00 00 02 1E 4F 39 01 00 00 00 00 02 1F 4F 39 01 00 00 00 00 02 20 4F 39 01 00 00 00 00 02 28 E4 39 01 00 00 00 00 02 29 17 39 01 00 00 00 00 02 2A F5 39 01 00 00 00 00 02 2D 06 39 01 00 00 00 00 02 2F 04 39 01 00 00 00 00 02 30 54 39 01 00 00 00 00 02 33 04 39 01 00 00 00 00 02 34 E6 39 01 00 00 00 00 02 35 32 39 01 00 00 00 00 02 36 02 39 01 00 00 00 00 02 37 E1 39 01 00 00 00 00 02 38 36 39 01 00 00 00 00 02 39 FE 39 01 00 00 00 00 02 3A 14 39 01 00 00 00 00 02 46 40 39 01 00 00 00 00 02 47 02 39 01 00 00 00 00 02 4A F0 39 01 00 00 00 00 02 4E 0F 39 01 00 00 00 00 02 4F 65 39 01 00 00 00 00 02 52 0F 39 01 00 00 00 00 02 53 39 39 01 00 00 00 00 02 54 14 39 01 00 00 00 00 02 56 36 39 01 00 00 00 00 02 57 7E 39 01 00 00 00 00 02 58 7E 39 01 00 00 00 00 02 59 7E 39 01 00 00 00 00 02 60 80 39 01 00 00 00 00 02 61 C9 39 01 00 00 00 00 02 62 03 39 01 00 00 00 00 02 63 FB 39 01 00 00 00 00 02 64 03 39 01 00 00 00 00 02 65 05 39 01 00 00 00 00 02 66 01 39 01 00 00 00 00 02 67 04 39 01 00 00 00 00 02 68 91 39 01 00 00 00 00 02 6A 19 39 01 00 00 00 00 02 6B CB 39 01 00 00 00 00 02 6C 20 39 01 00 00 00 00 02 6D E5 39 01 00 00 00 00 02 6E C8 39 01 00 00 00 00 02 6F 22 39 01 00 00 00 00 02 70 E3 39 01 00 00 00 00 02 71 04 39 01 00 00 00 00 02 7A 07 39 01 00 00 00 00 02 7B 40 39 01 00 00 00 00 02 7D 01 39 01 00 00 00 00 02 7F 2C 39 01 00 00 00 00 02 83 0F 39 01 00 00 00 00 02 84 65 39 01 00 00 00 00 02 87 0F 39 01 00 00 00 00 02 88 39 39 01 00 00 00 00 02 89 14 39 01 00 00 00 00 02 8B 36 39 01 00 00 00 00 02 8C 39 39 01 00 00 00 00 02 8D 39 39 01 00 00 00 00 02 8E 39 39 01 00 00 00 00 02 95 80 39 01 00 00 00 00 02 96 FD 39 01 00 00 00 00 02 97 14 39 01 00 00 00 00 02 98 B3 39 01 00 00 00 00 02 99 01 39 01 00 00 00 00 02 9A 08 39 01 00 00 00 00 02 9B 02 39 01 00 00 00 00 02 9C 4C 39 01 00 00 00 00 02 9D BC 39 01 00 00 00 00 02 9F AC 39 01 00 00 00 00 02 A0 FF 39 01 00 00 00 00 02 A2 44 39 01 00 00 00 00 02 A3 78 39 01 00 00 00 00 02 A4 F8 39 01 00 00 00 00 02 A5 4A 39 01 00 00 00 00 02 A6 72 39 01 00 00 00 00 02 A7 4C 39 01 00 00 00 00 02 FF 2C 39 01 00 00 00 00 02 FB 01 39 01 00 00 00 00 02 00 02 39 01 00 00 00 00 02 01 02 39 01 00 00 00 00 02 02 02 39 01 00 00 00 00 02 03 16 39 01 00 00 00 00 02 04 16 39 01 00 00 00 00 02 05 16 39 01 00 00 00 00 02 0D 1F 39 01 00 00 00 00 02 0E 1F 39 01 00 00 00 00 02 16 1B 39 01 00 00 00 00 02 17 4B 39 01 00 00 00 00 02 18 4B 39 01 00 00 00 00 02 19 4B 39 01 00 00 00 00 02 2A 03 39 01 00 00 00 00 02 4D 16 39 01 00 00 00 00 02 4E 02 39 01 00 00 00 00 02 4F 2F 39 01 00 00 00 00 02 53 02 39 01 00 00 00 00 02 54 02 39 01 00 00 00 00 02 55 02 39 01 00 00 00 00 02 56 0E 39 01 00 00 00 00 02 58 0E 39 01 00 00 00 00 02 59 0E 39 01 00 00 00 00 02 61 1F 39 01 00 00 00 00 02 62 1F 39 01 00 00 00 00 02 6A 14 39 01 00 00 00 00 02 6B 34 39 01 00 00 00 00 02 6C 34 39 01 00 00 00 00 02 6D 34 39 01 00 00 00 00 02 7E 03 39 01 00 00 00 00 02 9D 0E 39 01 00 00 00 00 02 9E 02 39 01 00 00 00 00 02 9F 02 39 01 00 00 00 00 02 FF 20 39 01 00 00 00 00 02 FB 01 39 01 00 00 00 00 11 B0 00 00 00 15 00 3F 00 5F 00 7E 00 97 00 AF 00 C3 39 01 00 00 00 00 11 B1 00 D7 01 0A 01 32 01 6F 01 9E 01 E5 02 1D 02 1E 39 01 00 00 00 00 11 B2 02 56 02 94 02 BC 02 F1 03 13 03 41 03 4F 03 5F 39 01 00 00 00 00 0F B3 03 71 03 84 03 99 03 B0 03 CA 03 D7 00 00 39 01 00 00 00 00 11 B4 00 00 00 17 00 46 00 69 00 8C 00 A5 00 BE 00 D1 39 01 00 00 00 00 11 B5 00 E4 01 18 01 40 01 7C 01 AA 01 F0 02 27 02 28 39 01 00 00 00 00 11 B6 02 5E 02 9B 02 C3 02 F6 03 18 03 45 03 54 03 63 39 01 00 00 00 00 0F B7 03 75 03 87 03 9C 03 B2 03 CA 03 D7 00 00 39 01 00 00 00 00 11 B8 00 00 00 18 00 49 00 6B 00 8E 00 A8 00 C1 00 D3 39 01 00 00 00 00 11 B9 00 E5 01 18 01 3F 01 7B 01 A8 01 EC 02 24 02 26 39 01 00 00 00 00 11 BA 02 5A 02 97 02 C0 02 F4 03 15 03 43 03 51 03 61 39 01 00 00 00 00 0F BB 03 72 03 85 03 9A 03 B1 03 CA 03 D7 00 00 39 01 00 00 00 00 02 C6 00 39 01 00 00 00 00 02 C7 00 39 01 00 00 00 00 02 C8 00 39 01 00 00 00 00 02 C9 00 39 01 00 00 00 00 02 CA 00 39 01 00 00 00 00 02 CB 00 39 01 00 00 00 00 02 CC 00 39 01 00 00 00 00 02 CD 00 39 01 00 00 00 00 02 CE 00 39 01 00 00 00 00 02 CF 00 39 01 00 00 00 00 02 D0 00 39 01 00 00 00 00 02 D1 00 39 01 00 00 00 00 02 D2 00 39 01 00 00 00 00 02 D3 00 39 01 00 00 00 00 02 D4 00 39 01 00 00 00 00 02 D5 00 39 01 00 00 00 00 02 D6 00 39 01 00 00 00 00 02 D7 00 39 01 00 00 00 00 02 D8 00 39 01 00 00 00 00 02 D9 00 39 01 00 00 00 00 02 DA 00 39 01 00 00 00 00 02 DB 00 39 01 00 00 00 00 02 DC 00 39 01 00 00 00 00 02 DD 00 39 01 00 00 00 00 02 DE 00 39 01 00 00 00 00 02 DF 00 39 01 00 00 00 00 02 E0 00 39 01 00 00 00 00 02 E1 00 39 01 00 00 00 00 02 E2 00 39 01 00 00 00 00 02 E3 00 39 01 00 00 00 00 02 E4 00 39 01 00 00 00 00 02 E5 00 39 01 00 00 00 00 02 E6 00 39 01 00 00 00 00 02 E7 00 39 01 00 00 00 00 02 E8 00 39 01 00 00 00 00 02 E9 00 39 01 00 00 00 00 02 FF 21 39 01 00 00 00 00 02 FB 01 39 01 00 00 00 00 11 B0 00 00 00 15 00 3F 00 5F 00 7E 00 97 00 AF 00 C3 39 01 00 00 00 00 11 B1 00 D7 01 0A 01 32 01 6F 01 9E 01 E5 02 1D 02 1E 39 01 00 00 00 00 11 B2 02 56 02 94 02 BC 02 F1 03 13 03 41 03 4F 03 5F 39 01 00 00 00 00 0F B3 03 71 03 84 03 99 03 B0 03 CA 03 D7 00 00 39 01 00 00 00 00 11 B4 00 00 00 17 00 46 00 69 00 8C 00 A5 00 BE 00 D1 39 01 00 00 00 00 11 B5 00 E4 01 18 01 40 01 7C 01 AA 01 F0 02 27 02 28 39 01 00 00 00 00 11 B6 02 5E 02 9B 02 C3 02 F6 03 18 03 45 03 54 03 63 39 01 00 00 00 00 0F B7 03 75 03 87 03 9C 03 B2 03 CA 03 D7 00 00 39 01 00 00 00 00 11 B8 00 00 00 18 00 49 00 6B 00 8E 00 A8 00 C1 00 D3 39 01 00 00 00 00 11 B9 00 E5 01 18 01 3F 01 7B 01 A8 01 EC 02 24 02 26 39 01 00 00 00 00 11 BA 02 5A 02 97 02 C0 02 F4 03 15 03 43 03 51 03 61 39 01 00 00 00 00 0F BB 03 72 03 85 03 9A 03 B1 03 CA 03 D7 00 00 39 01 00 00 00 00 02 FF E0 39 01 00 00 00 00 02 FB 01 39 01 00 00 00 00 02 35 82 39 01 00 00 00 00 02 85 32 39 01 00 00 00 00 02 FF F0 39 01 00 00 00 00 02 FB 01 39 01 00 00 00 00 02 1C 01 39 01 00 00 00 00 02 33 01 39 01 00 00 00 00 02 5A 00 39 01 00 00 00 00 02 FF D0 39 01 00 00 00 00 02 FB 01 39 01 00 00 00 00 02 53 22 39 01 00 00 00 00 02 54 02 39 01 00 00 00 00 02 FF C0 39 01 00 00 00 00 02 FB 01 39 01 00 00 00 00 02 9C 11 39 01 00 00 00 00 02 9D 11 39 01 00 00 00 00 02 FF 2B 39 01 00 00 00 00 02 FB 01 39 01 00 00 00 00 02 B7 0A 39 01 00 00 00 00 02 B8 1C 39 01 00 00 00 00 02 C0 01 39 01 00 00 00 00 02 FF 10 39 01 00 00 00 00 02 35 01 39 01 00 00 00 00 02 51 FF 39 01 00 00 00 00 02 53 0C 39 01 00 00 00 00 02 55 00 05 01 00 00 78 00 01 11 05 01 00 00 28 00 01 29];
                    qcom,mdss-dsi-on-command-state = "dsi_lp_mode";
                    qcom,mdss-dsi-panel-framerate = <0x5A>;
                    qcom,mdss-dsi-panel-height = <0x968>;
                    qcom,mdss-dsi-panel-phy-timings = [00 18 06 06 21 20 06 06 07 02 04 00 16 16];
                    qcom,mdss-dsi-panel-width = <0x438>;
                    qcom,mdss-dsi-v-back-porch = <0xA>;
                    qcom,mdss-dsi-v-front-porch = <0x2E>;
                    qcom,mdss-dsi-v-pulse-width = <0xA>;
                };
            };
        };
        qcom,mdss_dsi_panel_m7_38_0c_0a_fhdp_video {
            qcom,bl-update-flag = "delay_until_first_frame";
            qcom,dsi-ctrl-num = <0x0>;
            qcom,dsi-phy-num = <0x0>;
            qcom,dsi-select-clocks = "pll_byte_clk0", "pll_dsi_clk0";
            qcom,dsi-supported-dfps-list = <0x78 0x5A 0x3C>;
            qcom,esd-err-irq-gpio = <&tlmm 0x21 0x2002>;
            qcom,mdss-brightness-init-level = <0x133>;
            qcom,mdss-dsi-bl-dcs-type-ss-ea;
            qcom,mdss-dsi-bl-inverted-dbv;
            qcom,mdss-dsi-bllp-eof-power-mode;
            qcom,mdss-dsi-bllp-power-mode;
            qcom,mdss-dsi-border-color = <0x0>;
            qcom,mdss-dsi-bpp = <0x18>;
            qcom,mdss-dsi-color-order = "rgb_swap_rgb";
            qcom,mdss-dsi-dma-trigger = "trigger_sw";
            qcom,mdss-dsi-lane-0-state;
            qcom,mdss-dsi-lane-1-state;
            qcom,mdss-dsi-lane-2-state;
            qcom,mdss-dsi-lane-3-state;
            qcom,mdss-dsi-lp11-init;
            qcom,mdss-dsi-mdp-trigger = "none";
            qcom,mdss-dsi-oled-panel-video-mode;
            qcom,mdss-dsi-pan-enable-dynamic-fps;
            qcom,mdss-dsi-pan-fps-update = "dfps_immediate_porch_mode_vfp";
            qcom,mdss-dsi-panel-id = <0x0>;
            qcom,mdss-dsi-panel-name = "m7 38 0c 0a video mode fhdp dsi panel";
            qcom,mdss-dsi-panel-type = "dsi_video_mode";
            qcom,mdss-dsi-reset-sequence = <0x0 0xA 0x1 0xA>;
            qcom,mdss-dsi-stream = <0x0>;
            qcom,mdss-dsi-traffic-mode = "burst_mode";
            qcom,mdss-dsi-tx-eot-append;
            qcom,mdss-dsi-underflow-color = <0xFF>;
            qcom,mdss-dsi-virtual-channel-id = <0x0>;
            qcom,mdss-pan-physical-height-dimension = <0x60A>;
            qcom,mdss-pan-physical-width-dimension = <0x2B7>;
            qcom,platform-en-gpio = <&pm6125_gpios 0x9 0x0>;
            qcom,mdss-dsi-display-timings {
                timing@0 {
                    mi,mdss-dsi-dispparam-dimming-hbmoff-command = [39 01 00 00 00 00 03 F0 5A 5A 39 01 00 00 00 00 04 B0 00 0D B2 39 01 00 00 00 00 02 B2 05 39 01 00 00 00 00 04 B0 00 0C B2 39 01 00 00 00 00 02 B2 30 39 01 00 00 00 00 02 F7 0B 39 01 00 00 00 00 03 F0 A5 A5];
                    mi,mdss-dsi-dispparam-dimming-hbmoff-command-state = "dsi_hs_mode";
                    mi,mdss-dsi-dispparam-dimming-hbmon-command = [39 01 00 00 00 00 03 F0 5A 5A 39 01 00 00 00 00 04 B0 00 0D B2 39 01 00 00 00 00 02 B2 30 39 01 00 00 00 00 04 B0 00 0C B2 39 01 00 00 00 00 02 B2 30 39 01 00 00 00 00 02 F7 0B 39 01 00 00 00 00 03 F0 A5 A5];
                    mi,mdss-dsi-dispparam-dimming-hbmon-command-state = "dsi_hs_mode";
                    mi,mdss-dsi-doze-hbm-command = [39 01 00 00 00 00 03 51 01 1B];
                    mi,mdss-dsi-doze-hbm-command-state = "dsi_hs_mode";
                    mi,mdss-dsi-doze-lbm-command = [39 01 00 00 00 00 03 51 00 18];
                    mi,mdss-dsi-doze-lbm-command-state = "dsi_hs_mode";
                    mi,mdss-dsi-flat-mode-off-command = <0x39010040 0x3F0 0x5A5A3901 0x400000 0x4B00089 0xB1390100 0x40000002 0xB10D3901 0x400000 0x4B00003 0xB8390100 0x40000005 0xB8FF8F01 0xFF390100 0x40000004 0xB000F8B5 0x39010040 0xFB5 0x82171717 0x86FB0A80 0x0 0xFF903901 0x0 0x3F0A5A5>;
                    mi,mdss-dsi-flat-mode-off-command-state = "dsi_hs_mode";
                    mi,mdss-dsi-flat-mode-on-command = <0x39010040 0x3F0 0x5A5A3901 0x400000 0x4B00089 0xB1390100 0x40000002 0xB12D3901 0x400000 0x4B00003 0xB8390100 0x40000005 0xB8FF8F01 0xFF390100 0x40000004 0xB000F8B5 0x39010040 0xFB5 0x82171717 0x86FB0A80 0x0 0xFF903901 0x0 0x3F0A5A5>;
                    mi,mdss-dsi-flat-mode-on-command-state = "dsi_hs_mode";
                    mi,mdss-dsi-hbm-off-command = [39 00 00 40 00 00 02 53 28 39 00 00 00 00 00 03 51 07 FF];
                    mi,mdss-dsi-hbm-off-command-state = "dsi_lp_mode";
                    mi,mdss-dsi-hbm-on-command = <0x39000040 0x253 0xE8390000 0x40000003 0x5107FF39 0x0 0x2F70B>;
                    mi,mdss-dsi-hbm-on-command-state = "dsi_lp_mode";
                    qcom,compression-mode = "dsc";
                    qcom,default-topology-index = <0x0>;
                    qcom,display-topology = <0x1 0x1 0x1>;
                    qcom,mdss-dsc-bit-per-component = <0x8>;
                    qcom,mdss-dsc-bit-per-pixel = <0x8>;
                    qcom,mdss-dsc-block-prediction-enable;
                    qcom,mdss-dsc-scr-version = <0x0>;
                    qcom,mdss-dsc-slice-height = <0x14>;
                    qcom,mdss-dsc-slice-per-pkt = <0x2>;
                    qcom,mdss-dsc-slice-width = <0x21C>;
                    qcom,mdss-dsc-version = <0x11>;
                    qcom,mdss-dsi-dispparam-fps-120hz-command = <0x39000040 0x3F0 0x5A5A3900 0x400000 0x2600139 0x0 0x2F70B>;
                    qcom,mdss-dsi-dispparam-fps-120hz-command-state = "dsi_hs_mode";
                    qcom,mdss-dsi-dispparam-fps-60hz-command = <0x39000040 0x3F0 0x5A5A3900 0x400000 0x2602139 0x0 0x2F70B>;
                    qcom,mdss-dsi-dispparam-fps-60hz-command-state = "dsi_hs_mode";
                    qcom,mdss-dsi-dispparam-fps-90hz-command = <0x39000040 0x3F0 0x5A5A3900 0x400000 0x2600139 0x0 0x2F70B>;
                    qcom,mdss-dsi-dispparam-fps-90hz-command-state = "dsi_hs_mode";
                    qcom,mdss-dsi-h-back-porch = <0x78>;
                    qcom,mdss-dsi-h-front-porch = <0x78>;
                    qcom,mdss-dsi-h-pulse-width = <0x1C>;
                    qcom,mdss-dsi-h-sync-skew = <0x0>;
                    qcom,mdss-dsi-on-command = [39 01 00 00 00 00 03 F0 5A 5A 39 01 00 00 00 00 03 F1 5A 5A 39 01 00 00 00 00 02 D0 08 39 01 00 00 00 00 04 B0 00 25 F2 39 01 00 00 00 00 02 F2 50 39 01 00 00 00 00 04 B0 00 2F F2 39 01 00 00 00 00 02 F2 27 39 01 00 00 00 00 03 F0 A5 A5 39 01 00 00 00 00 03 F1 A5 A5 05 01 00 00 20 00 02 11 00 39 01 00 00 00 00 03 F0 5A 5A 39 01 00 00 00 00 03 B2 01 31 39 01 00 00 00 00 08 DF 09 30 95 43 A9 43 A9 39 01 00 00 00 00 03 F0 A5 A5 39 01 00 00 00 00 02 9D 01 39 01 00 00 00 00 5A 9E 11 00 00 89 30 80 09 60 04 38 00 28 02 1C 02 1C 02 00 02 0E 00 20 03 DD 00 07 00 0C 02 77 02 8B 18 00 10 F0 03 0C 20 00 06 0B 0B 33 0E 1C 2A 38 46 54 62 69 70 77 79 7B 7D 7E 01 02 01 00 09 40 09 BE 19 FC 19 FA 19 F8 1A 38 1A 78 1A B6 2A F6 2B 34 2B 74 3B 74 6B F4 00 39 01 00 00 00 00 03 F0 5A 5A 39 01 00 00 00 00 02 60 01 39 01 00 00 00 00 02 F7 0B 39 01 00 00 00 00 03 F0 A5 A5 39 01 00 00 00 00 03 F0 5A 5A 39 01 00 00 00 00 04 B0 00 40 F2 39 01 00 00 00 00 02 F2 03 39 01 00 00 00 00 03 F0 A5 A5 39 01 00 00 00 00 03 FC 5A 5A 39 00 00 00 00 00 04 B0 00 11 FE 39 00 00 00 00 00 02 FE 00 39 01 00 00 00 00 03 FC A5 A5 39 01 00 00 00 00 04 B0 00 0D B2 39 01 00 00 00 00 02 B2 05 39 01 00 00 00 00 04 B0 00 0C B2 39 01 00 00 00 00 02 B2 30 39 01 00 00 00 00 02 F7 0B 39 01 00 00 00 00 03 F0 A5 A5 39 01 00 00 00 00 03 F0 5A 5A 39 01 00 00 00 00 03 FC 5A 5A 39 01 00 00 00 00 04 ED 01 CD 00 39 01 00 00 00 00 02 E1 93 39 01 00 00 00 00 04 B0 00 06 F4 39 01 00 00 00 00 02 F4 1F 39 01 00 00 00 00 03 F0 A5 A5 39 01 00 00 00 00 03 FC A5 A5 39 01 00 00 00 00 02 53 28 39 01 00 00 64 00 03 51 00 00 05 01 00 00 00 00 02 29 00];
                    qcom,mdss-dsi-on-command-state = "dsi_lp_mode";
                    qcom,mdss-dsi-panel-framerate = <0x78>;
                    qcom,mdss-dsi-panel-height = <0x960>;
                    qcom,mdss-dsi-panel-phy-timings = [00 24 0A 0A 1A 19 09 0A 09 02 04 00 1E 0F];
                    qcom,mdss-dsi-panel-width = <0x438>;
                    qcom,mdss-dsi-pre-off-command = [05 01 00 00 14 00 02 28 00 05 01 00 00 96 00 02 10 00];
                    qcom,mdss-dsi-pre-off-command-state = "dsi_hs_mode";
                    qcom,mdss-dsi-v-back-porch = <0xA>;
                    qcom,mdss-dsi-v-front-porch = <0x14>;
                    qcom,mdss-dsi-v-pulse-width = <0x2>;
                    qcom,mdss-dsi-video-mode;
                };
            };
        };
        qcom,mdss_dsi_panel_m7_38_0c_0b_fhdp_video {
            qcom,bl-update-flag = "delay_until_first_frame";
            qcom,dsi-ctrl-num = <0x0>;
            qcom,dsi-phy-num = <0x0>;
            qcom,dsi-select-clocks = "pll_byte_clk0", "pll_dsi_clk0";
            qcom,dsi-supported-dfps-list = <0x78 0x5A 0x3C>;
            qcom,esd-err-irq-gpio = <&tlmm 0x21 0x2002>;
            qcom,mdss-brightness-init-level = <0x133>;
            qcom,mdss-dsi-bl-dcs-type-ss-ea;
            qcom,mdss-dsi-bl-inverted-dbv;
            qcom,mdss-dsi-bllp-eof-power-mode;
            qcom,mdss-dsi-bllp-power-mode;
            qcom,mdss-dsi-border-color = <0x0>;
            qcom,mdss-dsi-bpp = <0x18>;
            qcom,mdss-dsi-color-order = "rgb_swap_rgb";
            qcom,mdss-dsi-dma-trigger = "trigger_sw";
            qcom,mdss-dsi-lane-0-state;
            qcom,mdss-dsi-lane-1-state;
            qcom,mdss-dsi-lane-2-state;
            qcom,mdss-dsi-lane-3-state;
            qcom,mdss-dsi-lp11-init;
            qcom,mdss-dsi-mdp-trigger = "none";
            qcom,mdss-dsi-oled-panel-video-mode;
            qcom,mdss-dsi-pan-enable-dynamic-fps;
            qcom,mdss-dsi-pan-fps-update = "dfps_immediate_porch_mode_vfp";
            qcom,mdss-dsi-panel-id = <0x0>;
            qcom,mdss-dsi-panel-name = "m7 38 0c 0b video mode fhdp dsi panel";
            qcom,mdss-dsi-panel-type = "dsi_video_mode";
            qcom,mdss-dsi-reset-sequence = <0x0 0xA 0x1 0xA>;
            qcom,mdss-dsi-stream = <0x0>;
            qcom,mdss-dsi-traffic-mode = "burst_mode";
            qcom,mdss-dsi-tx-eot-append;
            qcom,mdss-dsi-underflow-color = <0xFF>;
            qcom,mdss-dsi-virtual-channel-id = <0x0>;
            qcom,mdss-pan-physical-height-dimension = <0x60A>;
            qcom,mdss-pan-physical-width-dimension = <0x2B7>;
            qcom,platform-en-gpio = <&pm6125_gpios 0x9 0x0>;
            qcom,mdss-dsi-display-timings {
                timing@0 {
                    mi,mdss-dsi-doze-hbm-command = [39 01 00 00 00 00 03 51 01 1B];
                    mi,mdss-dsi-doze-hbm-command-state = "dsi_hs_mode";
                    mi,mdss-dsi-doze-lbm-command = [39 01 00 00 00 00 03 51 00 18];
                    mi,mdss-dsi-doze-lbm-command-state = "dsi_hs_mode";
                    mi,mdss-dsi-flat-mode-off-command = <0x39010040 0x3F1 0x5A5A3901 0x400000 0x5B00088 0xB1013901 0x400000 0x29B1270D 0xFE0F9980 0x1FF128F 0xFF12FF38 0x395B0B0B 0xB2E2E2E 0x3E3E3E4A 0x4A4A4E4E 0x4E1B2FDA 0x18748000 0x223901 0x0 0x3F1A5A5>;
                    mi,mdss-dsi-flat-mode-off-command-state = "dsi_hs_mode";
                    mi,mdss-dsi-flat-mode-on-command = [39 01 00 40 00 00 03 F1 5A 5A 39 01 00 40 00 00 05 B0 00 88 B1 01 39 01 00 40 00 00 29 B1 27 2D C5 0F 61 80 01 FF 12 26 FF 12 FF 42 44 6E 0B 0B 0B 2D 2D 2D 3C 3C 3C 47 47 47 4B 4B 4B 1B 2F DA 18 64 80 00 00 22 39 01 00 40 00 00 05 B0 00 03 B8 01 39 01 00 40 00 00 05 B8 FF 8F 01 FF 39 01 00 40 00 00 05 B0 00 F8 B5 01 39 01 00 40 00 00 0F B5 E2 0E 0E 0E 82 1E 95 80 00 00 00 00 FF 90 39 01 00 00 00 00 03 F1 A5 A5];
                    mi,mdss-dsi-flat-mode-on-command-state = "dsi_hs_mode";
                    mi,mdss-dsi-hbm-off-command = [39 00 00 40 00 00 02 53 30 39 00 00 00 00 00 02 F7 07];
                    mi,mdss-dsi-hbm-off-command-state = "dsi_lp_mode";
                    mi,mdss-dsi-hbm-on-command = <0x39000040 0x253 0xF0390000 0x40000003 0x5107FF39 0x0 0x2F707>;
                    mi,mdss-dsi-hbm-on-command-state = "dsi_lp_mode";
                    qcom,compression-mode = "dsc";
                    qcom,default-topology-index = <0x0>;
                    qcom,display-topology = <0x1 0x1 0x1>;
                    qcom,mdss-dsc-bit-per-component = <0x8>;
                    qcom,mdss-dsc-bit-per-pixel = <0x8>;
                    qcom,mdss-dsc-block-prediction-enable;
                    qcom,mdss-dsc-scr-version = <0x0>;
                    qcom,mdss-dsc-slice-height = <0x14>;
                    qcom,mdss-dsc-slice-per-pkt = <0x2>;
                    qcom,mdss-dsc-slice-width = <0x21C>;
                    qcom,mdss-dsc-version = <0x11>;
                    qcom,mdss-dsi-dispparam-fps-120hz-command = <0x39000040 0x3F1 0x5A5A3900 0x400000 0x2600139 0x0 0x2F707>;
                    qcom,mdss-dsi-dispparam-fps-120hz-command-state = "dsi_hs_mode";
                    qcom,mdss-dsi-dispparam-fps-60hz-command = <0x39000040 0x3F1 0x5A5A3900 0x400000 0x2602139 0x0 0x2F707>;
                    qcom,mdss-dsi-dispparam-fps-60hz-command-state = "dsi_hs_mode";
                    qcom,mdss-dsi-dispparam-fps-90hz-command = <0x39000040 0x3F1 0x5A5A3900 0x400000 0x2600139 0x0 0x2F707>;
                    qcom,mdss-dsi-dispparam-fps-90hz-command-state = "dsi_hs_mode";
                    qcom,mdss-dsi-h-back-porch = <0x78>;
                    qcom,mdss-dsi-h-front-porch = <0x78>;
                    qcom,mdss-dsi-h-pulse-width = <0x1C>;
                    qcom,mdss-dsi-h-sync-skew = <0x0>;
                    qcom,mdss-dsi-off-command = <0x5010000 0xB000128 0x5010000 0x97000110>;
                    qcom,mdss-dsi-off-command-state = "dsi_hs_mode";
                    qcom,mdss-dsi-on-command = <0x39010000 0xB00039F 0x5A5A0501 0x1400 0x2110039 0x1000000 0x3F15A 0x5A390100 0x3 0xB2013039 0x1000000 0x3F1A5 0xA5390100 0x2 0x9D013901 0x0 0x5A9E1100 0x893080 0x9600438 0x28021C 0x21C0200 0x20E0020 0x3DD0007 0xC0277 0x28B1800 0x10F0030C 0x2000060B 0xB330E1C 0x2A384654 0x62697077 0x797B7D7E 0x1020100 0x94009BE 0x19FC19FA 0x19F81A38 0x1A781AB6 0x2AF62B34 0x2B743B74 0x6BF40039 0x1000000 0x5F15A 0x5A5A5A39 0x1000000 0x5B000 0x9DE00139 0x1000000 0x2E000 0x39010000 0x5F1 0xA5A5A5A5 0x39010000 0x3F1 0x5A5A3901 0x0 0x2600139 0x1000000 0x2F707 0x39010000 0x3F1 0xA5A53901 0x0 0x5F15A5A 0x5A5A3901 0x0 0x5B00032 0xF6013901 0x0 0x6F62400 0x19000039 0x1000000 0x5F1A5 0xA5A5A539 0x1000000 0x3F15A 0x5A390100 0x5 0xB0000DB2 0x1390100 0x2 0xB2203901 0x0 0x5B0000C 0xB2013901 0x0 0x2B23039 0x1000000 0x3F1A5 0xA5390100 0x5 0xF15A5A5A 0x5A390100 0x5 0xB0000BCE 0x1390100 0x2 0xCE113901 0x0 0x5B00008 0xEA013901 0x0 0x3EAF689 0x39010000 0x5B0 0xAEA01 0x39010000 0x4EA 0x55010439 0x1000000 0x5B000 0xDEA0139 0x1000000 0x3EAFF 0xFF390100 0x5 0xB00074E1 0x1390100 0x2 0xE13F3901 0x0 0x5B00010 0xEA013901 0x0 0x2EA0139 0x1000000 0x5F1A5 0xA5A5A539 0x1000000 0x25330 0x39010000 0x351 0x3901 0x6500 0x2F70705 0x1000000 0x22900>;
                    qcom,mdss-dsi-on-command-state = "dsi_lp_mode";
                    qcom,mdss-dsi-panel-framerate = <0x78>;
                    qcom,mdss-dsi-panel-height = <0x960>;
                    qcom,mdss-dsi-panel-phy-timings = [00 24 0A 0A 1A 19 09 0A 09 02 04 00 1E 0F];
                    qcom,mdss-dsi-panel-width = <0x438>;
                    qcom,mdss-dsi-v-back-porch = <0xA>;
                    qcom,mdss-dsi-v-front-porch = <0x14>;
                    qcom,mdss-dsi-v-pulse-width = <0x2>;
                    qcom,mdss-dsi-video-mode;
                };
            };
        };
        qcom,mdss_dsi_panel_n7_38_0c_0a_fhdp_video {
            mi,doze-hbm-dbv-level = <0xFC>;
            mi,doze-lbm-dbv-level = <0x14>;
            mi,flatmode-default-on-enabled;
            mi,flatmode-status-check-enabled;
            mi,local-hbm-enabled;
            mi,local-hbm-ui-ready-delay-num-frame = <0x3>;
            mi,mdss-dsi-panel-flatmode-on-status-value = <0x0>;
            mi,mdss-dsi-panel-flatmode-status-read-length = <0x1>;
            mi,need-fod-animal-in-normal-enabled;
            qcom,bl-update-flag = "delay_until_first_frame";
            qcom,dsi-ctrl-num = <0x0>;
            qcom,dsi-phy-num = <0x0>;
            qcom,dsi-select-clocks = "pll_byte_clk0", "pll_dsi_clk0";
            qcom,dsi-supported-dfps-list = <0x78 0x5A 0x3C>;
            qcom,esd-err-irq-gpio = <&tlmm 0x21 0x2002>;
            qcom,mdss-brightness-init-level = <0x133>;
            qcom,mdss-dsi-bl-dcs-type-ss-ea;
            qcom,mdss-dsi-bl-inverted-dbv;
            qcom,mdss-dsi-bllp-eof-power-mode;
            qcom,mdss-dsi-bllp-power-mode;
            qcom,mdss-dsi-border-color = <0x0>;
            qcom,mdss-dsi-bpp = <0x18>;
            qcom,mdss-dsi-color-order = "rgb_swap_rgb";
            qcom,mdss-dsi-dma-trigger = "trigger_sw";
            qcom,mdss-dsi-lane-0-state;
            qcom,mdss-dsi-lane-1-state;
            qcom,mdss-dsi-lane-2-state;
            qcom,mdss-dsi-lane-3-state;
            qcom,mdss-dsi-lp11-init;
            qcom,mdss-dsi-mdp-trigger = "none";
            qcom,mdss-dsi-oled-panel-video-mode;
            qcom,mdss-dsi-pan-enable-dynamic-fps;
            qcom,mdss-dsi-pan-fps-update = "dfps_immediate_porch_mode_vfp";
            qcom,mdss-dsi-panel-id = <0x0>;
            qcom,mdss-dsi-panel-name = "n7 38 0c 0a video mode fhdp dsi panel";
            qcom,mdss-dsi-panel-type = "dsi_video_mode";
            qcom,mdss-dsi-reset-sequence = <0x0 0xA 0x1 0xA>;
            qcom,mdss-dsi-stream = <0x0>;
            qcom,mdss-dsi-traffic-mode = "burst_mode";
            qcom,mdss-dsi-tx-eot-append;
            qcom,mdss-dsi-underflow-color = <0xFF>;
            qcom,mdss-dsi-virtual-channel-id = <0x0>;
            qcom,mdss-pan-physical-height-dimension = <0x60A>;
            qcom,mdss-pan-physical-width-dimension = <0x2B7>;
            qcom,platform-en-gpio = <&pm6125_gpios 0x9 0x0>;
            qcom,mdss-dsi-display-timings {
                timing@0 {
                    mi,mdss-dsi-dispparam-dimming-hbmoff-command = [39 01 00 00 00 00 03 F0 5A 5A 39 01 00 00 00 00 04 B0 00 0D B2 39 01 00 00 00 00 02 B2 05 39 01 00 00 00 00 04 B0 00 0C B2 39 01 00 00 00 00 02 B2 30 39 01 00 00 00 00 02 F7 0B 39 01 00 00 00 00 03 F0 A5 A5];
                    mi,mdss-dsi-dispparam-dimming-hbmoff-command-state = "dsi_hs_mode";
                    mi,mdss-dsi-dispparam-dimming-hbmon-command = [39 01 00 00 00 00 03 F0 5A 5A 39 01 00 00 00 00 04 B0 00 0D B2 39 01 00 00 00 00 02 B2 30 39 01 00 00 00 00 04 B0 00 0C B2 39 01 00 00 00 00 02 B2 30 39 01 00 00 00 00 02 F7 0B 39 01 00 00 00 00 03 F0 A5 A5];
                    mi,mdss-dsi-dispparam-dimming-hbmon-command-state = "dsi_hs_mode";
                    mi,mdss-dsi-doze-hbm-command = [39 01 00 00 00 00 03 51 01 1B];
                    mi,mdss-dsi-doze-hbm-command-state = "dsi_hs_mode";
                    mi,mdss-dsi-doze-lbm-command = [39 01 00 00 00 00 03 51 00 18];
                    mi,mdss-dsi-doze-lbm-command-state = "dsi_hs_mode";
                    mi,mdss-dsi-flat-mode-off-command = <0x39010040 0x3F0 0x5A5A3901 0x400000 0x4B00089 0xB1390100 0x40000002 0xB10D3901 0x400000 0x4B0008E 0xB1390100 0x40000002 0xB10F3901 0x0 0x3F0A5A5>;
                    mi,mdss-dsi-flat-mode-off-command-state = "dsi_hs_mode";
                    mi,mdss-dsi-flat-mode-on-command = <0x39010040 0x3F0 0x5A5A3901 0x400000 0x4B00089 0xB1390100 0x40000002 0xB12D3901 0x400000 0x4B0008E 0xB1390100 0x40000002 0xB10F3901 0x0 0x3F0A5A5>;
                    mi,mdss-dsi-flat-mode-on-command-state = "dsi_hs_mode";
                    mi,mdss-dsi-hbm-off-command = [39 00 00 40 00 00 02 53 28 39 00 00 00 00 00 03 51 07 FF];
                    mi,mdss-dsi-hbm-off-command-state = "dsi_lp_mode";
                    mi,mdss-dsi-hbm-on-command = <0x39000040 0x253 0xE8390000 0x40000003 0x5107FF39 0x0 0x2F70B>;
                    mi,mdss-dsi-hbm-on-command-state = "dsi_lp_mode";
                    mi,mdss-dsi-local-hbm-110nit-off-to-normal-command = [39 00 00 40 00 00 03 F0 5A 5A 39 00 00 40 00 00 02 53 28 39 00 00 40 00 00 04 B0 01 17 B2 39 00 00 40 00 00 02 B2 00 39 00 00 40 00 00 04 B0 00 19 F4 39 00 00 40 00 00 02 F4 0A 39 00 00 40 00 00 04 B0 01 53 B2 39 00 00 40 00 00 0F B2 01 C2 00 40 14 02 80 52 0A 41 48 7F FF FF 39 00 00 40 00 00 04 B0 00 B5 B4 39 00 00 40 00 00 04 B4 00 00 14 39 00 00 40 00 00 04 B0 00 69 B2 39 00 00 40 00 00 08 B2 03 03 03 03 02 01 00 39 00 00 40 00 00 04 B0 00 19 B2 39 00 00 40 00 00 0C B2 0A 41 48 1C 24 28 56 F6 B7 7F F8 39 00 00 00 00 00 02 F7 0B];
                    mi,mdss-dsi-local-hbm-110nit-off-to-normal-command-state = "dsi_hs_mode";
                    mi,mdss-dsi-local-hbm-hlpm-white-1000nit-command = [39 00 00 40 00 00 03 F0 5A 5A 39 00 00 40 00 00 02 60 01 39 00 00 40 00 00 02 53 24 39 00 00 40 00 00 04 B0 01 53 B2 39 00 00 40 00 00 0F B2 00 04 7F F7 FF 7F F7 FF 7F F7 FF 7F FF FF 39 00 00 40 00 00 04 B0 00 B5 B4 39 00 00 40 00 00 04 B4 01 00 14 39 00 00 40 00 00 04 B0 01 08 B5 39 00 00 40 00 00 10 B5 02 00 00 00 00 1B 87 D9 28 08 A1 21 C8 3D 5D 39 00 00 40 00 00 04 B0 01 4E B2 39 00 00 40 00 00 06 B2 03 33 AF 3F FF 39 00 00 40 00 00 04 B0 00 19 F4 39 00 00 40 00 00 02 F4 1C 39 00 00 40 00 00 04 B0 01 17 B2 39 00 00 40 00 00 02 B2 01 39 00 00 40 00 00 04 B0 00 BD B4 39 00 00 40 00 00 03 B4 03 FF 39 00 00 40 00 00 04 B0 00 36 B4 39 00 00 40 00 00 0D B4 00 40 14 02 80 52 0A 41 48 7F FF FF 39 00 00 00 00 00 02 F7 0B];
                    mi,mdss-dsi-local-hbm-hlpm-white-1000nit-command-state = "dsi_hs_mode";
                    mi,mdss-dsi-local-hbm-hlpm-white-110nit-command = [39 00 00 40 00 00 03 F0 5A 5A 39 00 00 40 00 00 02 60 01 39 00 00 40 00 00 02 53 24 39 00 00 40 00 00 04 B0 01 53 B2 39 00 00 40 00 00 0F B2 00 04 7F F7 FF 7F F7 FF 7F F7 FF 7F FF FF 39 00 00 40 00 00 04 B0 00 B5 B4 39 00 00 40 00 00 04 B4 01 00 14 39 00 00 40 00 00 04 B0 01 08 B5 39 00 00 40 00 00 10 B5 02 00 00 00 00 1B 87 D9 28 08 A1 21 C8 3D 5D 39 00 00 40 00 00 04 B0 00 19 F4 39 00 00 40 00 00 02 F4 1F 39 00 00 40 00 00 04 B0 01 17 B2 39 00 00 40 00 00 33 B2 01 00 00 00 00 00 01 F0 F0 39 00 00 00 00 15 1D 12 61 15 38 24 7D 15 82 5E C8 16 B9 8C 00 16 F1 C0 3E 2A 52 16 A3 2B D1 87 2C 3B 27 D4 8D 3F 7A 1D E9 39 00 00 40 00 00 04 B0 00 69 B2 39 00 00 40 00 00 08 B2 03 03 03 03 03 02 01 39 00 00 40 00 00 04 B0 00 19 B2 39 00 00 40 00 00 0C B2 0E 41 D4 28 34 92 5F 17 C4 7F F8 39 00 00 40 00 00 04 B0 00 BD B4 39 00 00 40 00 00 03 B4 03 FF 39 00 00 40 00 00 04 B0 01 4E B2 39 00 00 40 00 00 06 B2 03 33 5F 00 BF 39 00 00 40 00 00 04 B0 00 36 B4 39 00 00 40 00 00 0D B4 00 40 14 02 80 52 0A 41 48 7F FF FF 39 00 00 00 00 00 02 F7 0B];
                    mi,mdss-dsi-local-hbm-hlpm-white-110nit-command-state = "dsi_hs_mode";
                    mi,mdss-dsi-local-hbm-normal-green-500nit-command = [39 00 00 40 00 00 03 F0 5A 5A 39 00 00 40 00 00 02 60 01 39 00 00 40 00 00 02 53 24 39 00 00 40 00 00 04 B0 01 53 B2 39 00 00 40 00 00 0F B2 00 04 7F F7 FF 7F F7 FF 7F F7 FF 7F FF FF 39 00 00 40 00 00 04 B0 00 B5 B4 39 00 00 40 00 00 04 B4 01 00 14 39 00 00 40 00 00 04 B0 01 08 B5 39 00 00 40 00 00 10 B5 02 33 FF 00 FF 1B 87 D9 28 08 A1 21 C8 3D 5D 39 00 00 40 00 00 04 B0 01 4E B2 39 00 00 40 00 00 06 B2 03 33 00 01 00 39 00 00 40 00 00 04 B0 00 19 F4 39 00 00 40 00 00 02 F4 1C 39 00 00 40 00 00 04 B0 01 17 B2 39 00 00 40 00 00 02 B2 01 39 00 00 40 00 00 04 B0 00 BD B4 39 00 00 40 00 00 03 B4 03 FF 39 00 00 40 00 00 04 B0 00 36 B4 39 00 00 40 00 00 0D B4 00 40 14 02 80 52 0A 41 48 7F FF FF 39 00 00 00 00 00 02 F7 0B];
                    mi,mdss-dsi-local-hbm-normal-green-500nit-command-state = "dsi_hs_mode";
                    mi,mdss-dsi-local-hbm-normal-white-1000nit-command = [39 00 00 40 00 00 03 F0 5A 5A 39 00 00 40 00 00 02 60 01 39 00 00 40 00 00 02 53 24 39 00 00 40 00 00 04 B0 01 53 B2 39 00 00 40 00 00 0F B2 00 04 7F F7 FF 7F F7 FF 7F F7 FF 7F FF FF 39 00 00 40 00 00 04 B0 00 B5 B4 39 00 00 40 00 00 04 B4 01 00 14 39 00 00 40 00 00 04 B0 01 08 B5 39 00 00 40 00 00 10 B5 02 00 00 00 00 1B 87 D9 28 08 A1 21 C8 3D 5D 39 00 00 40 00 00 04 B0 01 4E B2 39 00 00 40 00 00 06 B2 03 33 AF 3F FF 39 00 00 40 00 00 04 B0 00 19 F4 39 00 00 40 00 00 02 F4 1C 39 00 00 40 00 00 04 B0 01 17 B2 39 00 00 40 00 00 02 B2 01 39 00 00 40 00 00 04 B0 00 BD B4 39 00 00 40 00 00 03 B4 03 FF 39 00 00 40 00 00 04 B0 00 36 B4 39 00 00 40 00 00 0D B4 00 40 14 02 80 52 0A 41 48 7F FF FF 39 00 00 00 00 00 02 F7 0B];
                    mi,mdss-dsi-local-hbm-normal-white-1000nit-command-state = "dsi_hs_mode";
                    mi,mdss-dsi-local-hbm-normal-white-110nit-command = [39 00 00 40 00 00 03 F0 5A 5A 39 00 00 40 00 00 02 60 01 39 00 00 40 00 00 02 53 24 39 00 00 40 00 00 04 B0 01 53 B2 39 00 00 40 00 00 0F B2 00 04 7F F7 FF 7F F7 FF 7F F7 FF 7F FF FF 39 00 00 40 00 00 04 B0 00 B5 B4 39 00 00 40 00 00 04 B4 01 00 14 39 00 00 40 00 00 04 B0 01 08 B5 39 00 00 40 00 00 10 B5 02 00 00 00 00 1B 87 D9 28 08 A1 21 C8 3D 5D 39 00 00 40 00 00 04 B0 00 19 F4 39 00 00 40 00 00 02 F4 1F 39 00 00 40 00 00 04 B0 01 17 B2 39 00 00 40 00 00 33 B2 01 00 00 00 00 00 01 F0 F0 39 00 00 00 00 15 1D 12 61 15 38 24 7D 15 82 5E C8 16 B9 8C 00 16 F1 C0 3E 2A 52 16 A3 2B D1 87 2C 3B 27 D4 8D 3F 7A 1D E9 39 00 00 40 00 00 04 B0 00 69 B2 39 00 00 40 00 00 08 B2 03 03 03 03 03 02 01 39 00 00 40 00 00 04 B0 00 19 B2 39 00 00 40 00 00 0C B2 0E 41 D4 28 34 92 5F 17 C4 7F F8 39 00 00 40 00 00 04 B0 00 BD B4 39 00 00 40 00 00 03 B4 03 FF 39 00 00 40 00 00 04 B0 01 4E B2 39 00 00 40 00 00 06 B2 03 33 5F 00 BF 39 00 00 40 00 00 04 B0 00 36 B4 39 00 00 40 00 00 0D B4 00 40 14 02 80 52 0A 41 48 7F FF FF 39 00 00 00 00 00 02 F7 0B];
                    mi,mdss-dsi-local-hbm-normal-white-110nit-command-state = "dsi_hs_mode";
                    mi,mdss-dsi-local-hbm-off-to-hbm-command = [39 00 00 40 00 00 03 F0 5A 5A 39 00 00 40 00 00 02 53 28 39 00 00 40 00 00 04 B0 01 17 B2 39 00 00 40 00 00 02 B2 00 39 00 00 40 00 00 04 B0 00 19 F4 39 00 00 40 00 00 02 F4 0A 39 00 00 40 00 00 04 B0 01 53 B2 39 00 00 40 00 00 0F B2 01 C2 00 40 14 02 80 52 0A 41 48 7F FF FF 39 00 00 40 00 00 04 B0 00 B5 B4 39 00 00 40 00 00 04 B4 00 00 14 39 00 00 00 00 00 02 F7 0B];
                    mi,mdss-dsi-local-hbm-off-to-hbm-command-state = "dsi_hs_mode";
                    mi,mdss-dsi-local-hbm-off-to-hlpm-command = [39 00 00 40 00 00 03 F0 5A 5A 39 00 00 40 00 00 02 53 28 39 00 00 40 00 00 04 B0 01 17 B2 39 00 00 40 00 00 02 B2 00 39 00 00 40 00 00 04 B0 00 19 F4 39 00 00 40 00 00 02 F4 0A 39 00 00 40 00 00 04 B0 01 53 B2 39 00 00 40 00 00 0F B2 01 C2 00 40 14 02 80 52 0A 41 48 7F FF FF 39 00 00 40 00 00 04 B0 00 B5 B4 39 00 00 40 00 00 04 B4 00 00 14 39 00 00 40 00 00 04 B0 00 69 B2 39 00 00 40 00 00 08 B2 03 03 03 03 02 01 00 39 00 00 40 00 00 04 B0 00 19 B2 39 00 00 40 00 00 0C B2 0A 41 48 1C 24 28 56 F6 B7 7F F8 39 00 00 00 00 00 02 F7 0B];
                    mi,mdss-dsi-local-hbm-off-to-hlpm-command-state = "dsi_hs_mode";
                    mi,mdss-dsi-local-hbm-off-to-llpm-command = [39 00 00 40 00 00 03 F0 5A 5A 39 00 00 40 00 00 02 53 28 39 00 00 40 00 00 04 B0 01 17 B2 39 00 00 40 00 00 02 B2 00 39 00 00 40 00 00 04 B0 00 19 F4 39 00 00 40 00 00 02 F4 0A 39 00 00 40 00 00 04 B0 01 53 B2 39 00 00 40 00 00 0F B2 01 C2 00 40 14 02 80 52 0A 41 48 7F FF FF 39 00 00 40 00 00 04 B0 00 B5 B4 39 00 00 40 00 00 04 B4 00 00 14 39 00 00 40 00 00 04 B0 00 69 B2 39 00 00 40 00 00 08 B2 03 03 03 03 02 01 00 39 00 00 40 00 00 04 B0 00 19 B2 39 00 00 40 00 00 0C B2 0A 41 48 1C 24 28 56 F6 B7 7F F8 39 00 00 00 00 00 02 F7 0B];
                    mi,mdss-dsi-local-hbm-off-to-llpm-command-state = "dsi_hs_mode";
                    mi,mdss-dsi-local-hbm-off-to-normal-command = [39 00 00 40 00 00 03 F0 5A 5A 39 00 00 40 00 00 02 53 28 39 00 00 40 00 00 04 B0 01 17 B2 39 00 00 40 00 00 02 B2 00 39 00 00 40 00 00 04 B0 00 19 F4 39 00 00 40 00 00 02 F4 0A 39 00 00 40 00 00 04 B0 01 53 B2 39 00 00 40 00 00 0F B2 01 C2 00 40 14 02 80 52 0A 41 48 7F FF FF 39 00 00 40 00 00 04 B0 00 B5 B4 39 00 00 40 00 00 04 B4 00 00 14 39 00 00 00 00 00 02 F7 0B];
                    mi,mdss-dsi-local-hbm-off-to-normal-command-state = "dsi_hs_mode";
                    qcom,compression-mode = "dsc";
                    qcom,default-topology-index = <0x0>;
                    qcom,display-topology = <0x1 0x1 0x1>;
                    qcom,mdss-dsc-bit-per-component = <0x8>;
                    qcom,mdss-dsc-bit-per-pixel = <0x8>;
                    qcom,mdss-dsc-block-prediction-enable;
                    qcom,mdss-dsc-scr-version = <0x0>;
                    qcom,mdss-dsc-slice-height = <0x14>;
                    qcom,mdss-dsc-slice-per-pkt = <0x2>;
                    qcom,mdss-dsc-slice-width = <0x21C>;
                    qcom,mdss-dsc-version = <0x11>;
                    qcom,mdss-dsi-dispparam-fps-120hz-command = <0x39000040 0x3F0 0x5A5A3900 0x400000 0x2600139 0x0 0x2F70B>;
                    qcom,mdss-dsi-dispparam-fps-120hz-command-state = "dsi_hs_mode";
                    qcom,mdss-dsi-dispparam-fps-60hz-command = <0x39000040 0x3F0 0x5A5A3900 0x400000 0x2602139 0x0 0x2F70B>;
                    qcom,mdss-dsi-dispparam-fps-60hz-command-state = "dsi_hs_mode";
                    qcom,mdss-dsi-dispparam-fps-90hz-command = [39 00 00 40 00 00 03 F0 5A 5A 39 00 00 40 00 00 03 F1 5A 5A 39 00 00 40 00 00 02 60 01 39 00 00 40 00 00 04 B0 00 0B F2 39 00 00 40 00 00 03 F2 03 44 39 00 00 40 00 00 04 B0 01 9E B2 39 00 00 40 00 00 0F B2 0C B0 0C 60 0C 20 0B 91 0B 02 0A 65 09 47 39 00 00 40 00 00 13 B3 08 1A 06 FC 05 CF 04 B1 03 84 01 D7 00 1C 00 1C 00 1C 39 00 00 40 00 00 02 F7 0B 39 00 00 40 00 00 03 F1 A5 A5 39 00 00 00 00 00 03 F0 A5 A5];
                    qcom,mdss-dsi-dispparam-fps-90hz-command-state = "dsi_hs_mode";
                    qcom,mdss-dsi-dispparam-hbm-on-l1-command = <0x39000040 0x253 0xE8390000 0x40000003 0x51012539 0x0 0x2F70B>;
                    qcom,mdss-dsi-dispparam-hbm-on-l1-command-state = "dsi_lp_mode";
                    qcom,mdss-dsi-dispparam-hbm-on-l2-command = <0x39000040 0x253 0xE8390000 0x40000003 0x51022639 0x0 0x2F70B>;
                    qcom,mdss-dsi-dispparam-hbm-on-l2-command-state = "dsi_lp_mode";
                    qcom,mdss-dsi-dispparam-hbm-on-l3-command = <0x39000040 0x253 0xE8390000 0x40000003 0x51036E39 0x0 0x2F70B>;
                    qcom,mdss-dsi-dispparam-hbm-on-l3-command-state = "dsi_lp_mode";
                    qcom,mdss-dsi-dispparam-hbm-on-l4-command = <0x39000040 0x253 0xE8390000 0x40000003 0x5105B639 0x0 0x2F70B>;
                    qcom,mdss-dsi-dispparam-hbm-on-l4-command-state = "dsi_lp_mode";
                    qcom,mdss-dsi-dispparam-hbm-on-l5-command = <0x39000040 0x253 0xE8390000 0x40000003 0x5107FF39 0x0 0x2F70B>;
                    qcom,mdss-dsi-dispparam-hbm-on-l5-command-state = "dsi_lp_mode";
                    qcom,mdss-dsi-h-back-porch = <0x18>;
                    qcom,mdss-dsi-h-front-porch = <0xB4>;
                    qcom,mdss-dsi-h-pulse-width = <0x10>;
                    qcom,mdss-dsi-h-sync-skew = <0x0>;
                    qcom,mdss-dsi-on-command = [05 01 00 00 20 00 02 11 00 39 01 00 00 00 00 03 F0 5A 5A 39 01 00 00 00 00 03 B2 01 31 39 01 00 00 00 00 08 DF 09 30 95 43 A9 43 A9 39 01 00 00 00 00 03 F0 A5 A5 39 01 00 00 00 00 02 9D 01 39 01 00 00 00 00 5A 9E 11 00 00 89 30 80 09 60 04 38 00 28 02 1C 02 1C 02 00 02 0E 00 20 03 DD 00 07 00 0C 02 77 02 8B 18 00 10 F0 03 0C 20 00 06 0B 0B 33 0E 1C 2A 38 46 54 62 69 70 77 79 7B 7D 7E 01 02 01 00 09 40 09 BE 19 FC 19 FA 19 F8 1A 38 1A 78 1A B6 2A F6 2B 34 2B 74 3B 74 6B F4 00 39 01 00 00 00 00 03 F0 5A 5A 39 01 00 00 00 00 02 60 01 39 01 00 00 00 00 02 F7 0B 39 01 00 00 00 00 03 F0 A5 A5 39 01 00 00 00 00 03 F0 5A 5A 39 01 00 00 00 00 04 B0 00 40 F2 39 01 00 00 00 00 02 F2 03 39 01 00 00 00 00 03 F0 A5 A5 39 01 00 00 00 00 03 FC 5A 5A 39 00 00 00 00 00 04 B0 00 11 FE 39 00 00 00 00 00 02 FE 00 39 01 00 00 00 00 03 FC A5 A5 39 01 00 00 00 00 04 B0 00 0D B2 39 01 00 00 00 00 02 B2 08 39 01 00 00 00 00 04 B0 00 0C B2 39 01 00 00 00 00 02 B2 20 39 01 00 00 00 00 02 F7 0B 39 01 00 00 00 00 03 F0 A5 A5 39 01 00 00 00 00 03 F0 5A 5A 39 01 00 00 00 00 03 FC 5A 5A 39 01 00 00 00 00 04 ED 01 CD 00 39 01 00 00 00 00 02 E1 93 39 01 00 00 00 00 04 B0 00 06 F4 39 01 00 00 00 00 02 F4 1F 39 01 00 00 00 00 03 F0 A5 A5 39 01 00 00 00 00 03 FC A5 A5 39 01 00 00 00 00 02 53 28 39 01 00 00 64 00 03 51 00 00 05 01 00 00 00 00 02 29 00];
                    qcom,mdss-dsi-on-command-state = "dsi_lp_mode";
                    qcom,mdss-dsi-panel-framerate = <0x78>;
                    qcom,mdss-dsi-panel-height = <0x960>;
                    qcom,mdss-dsi-panel-phy-timings = [00 22 09 09 19 17 09 09 09 02 04 00 1D 0E];
                    qcom,mdss-dsi-panel-width = <0x438>;
                    qcom,mdss-dsi-pre-off-command = [05 01 00 00 14 00 02 28 00 05 01 00 00 96 00 02 10 00];
                    qcom,mdss-dsi-pre-off-command-state = "dsi_hs_mode";
                    qcom,mdss-dsi-v-back-porch = <0xA>;
                    qcom,mdss-dsi-v-front-porch = <0x14>;
                    qcom,mdss-dsi-v-pulse-width = <0x2>;
                    qcom,mdss-dsi-video-mode;
                };
            };
        };
        qcom,mdss_dsi_sim_video {
            qcom,dsi-ctrl-num = <0x0>;
            qcom,dsi-phy-num = <0x0>;
            qcom,dsi-select-clocks = "pll_byte_clk0", "pll_dsi_clk0";
            qcom,mdss-dsi-bl-pmic-control-type = "bl_ctrl_dcs";
            qcom,mdss-dsi-bllp-eof-power-mode;
            qcom,mdss-dsi-bllp-power-mode;
            qcom,mdss-dsi-border-color = <0x0>;
            qcom,mdss-dsi-bpp = <0x18>;
            qcom,mdss-dsi-dma-trigger = "trigger_sw";
            qcom,mdss-dsi-lane-0-state;
            qcom,mdss-dsi-lane-1-state;
            qcom,mdss-dsi-lane-2-state;
            qcom,mdss-dsi-lane-3-state;
            qcom,mdss-dsi-mdp-trigger = "none";
            qcom,mdss-dsi-panel-blackness-level = <0xC9E>;
            qcom,mdss-dsi-panel-hdr-color-primaries = <0x38A4 0x3C8C 0x7D00 0x4268 0x3C8C 0x7530 0x1F40 0xBB8>;
            qcom,mdss-dsi-panel-hdr-enabled;
            qcom,mdss-dsi-panel-name = "Simulator video mode dsi panel";
            qcom,mdss-dsi-panel-peak-brightness = <0x401640>;
            qcom,mdss-dsi-panel-type = "dsi_video_mode";
            qcom,mdss-dsi-reset-sequence = <0x1 0x0 0x0 0x0 0x1 0x0>;
            qcom,mdss-dsi-stream = <0x0>;
            qcom,mdss-dsi-t-clk-post = <0x4>;
            qcom,mdss-dsi-t-clk-pre = <0x1B>;
            qcom,mdss-dsi-traffic-mode = "non_burst_sync_event";
            qcom,mdss-dsi-underflow-color = <0xFF>;
            qcom,mdss-dsi-virtual-channel-id = <0x0>;
            qcom,panel-ack-disabled;
            qcom,panel-supply-entries = <&dsi_panel_pwr_supply_no_labibb>;
            qcom,platform-reset-gpio = <&tlmm 0x52 0x0>;
            qcom,mdss-dsi-display-timings {
                timing@0 {
                    qcom,default-topology-index = <0x0>;
                    qcom,display-topology = <0x1 0x0 0x1>;
                    qcom,mdss-dsi-h-back-porch = <0x8>;
                    qcom,mdss-dsi-h-front-porch = <0x8>;
                    qcom,mdss-dsi-h-left-border = <0x0>;
                    qcom,mdss-dsi-h-pulse-width = <0x8>;
                    qcom,mdss-dsi-h-right-border = <0x0>;
                    qcom,mdss-dsi-h-sync-pulse = <0x0>;
                    qcom,mdss-dsi-h-sync-skew = <0x0>;
                    qcom,mdss-dsi-off-command = [22 01 00 00 00 00 02 00 00];
                    qcom,mdss-dsi-off-command-state = "dsi_lp_mode";
                    qcom,mdss-dsi-on-command = [32 01 00 00 00 00 02 00 00];
                    qcom,mdss-dsi-on-command-state = "dsi_lp_mode";
                    qcom,mdss-dsi-panel-framerate = <0x3C>;
                    qcom,mdss-dsi-panel-height = <0x1E0>;
                    qcom,mdss-dsi-panel-phy-timings = [01 09 01 01 1B 1B 01 01 02 02 04 00 0A 11];
                    qcom,mdss-dsi-panel-timings = <0x0 0x0 0x0>;
                    qcom,mdss-dsi-panel-width = <0x280>;
                    qcom,mdss-dsi-v-back-porch = <0x6>;
                    qcom,mdss-dsi-v-bottom-border = <0x0>;
                    qcom,mdss-dsi-v-front-porch = <0x6>;
                    qcom,mdss-dsi-v-pulse-width = <0x2>;
                    qcom,mdss-dsi-v-top-border = <0x0>;
                };
            };
        };
        qcom,mdss_dsi_td4330_truly_v2_cmd {
            qcom,dsi-ctrl-num = <0x0>;
            qcom,dsi-dyn-clk-enable;
            qcom,dsi-dyn-clk-list = <0x38491AB0 0x3758F3D0 0x3794FD88 0x37D10740 0x380D10F0>;
            qcom,dsi-phy-num = <0x0>;
            qcom,dsi-select-clocks = "pll_byte_clk0", "pll_dsi_clk0";
            qcom,esd-check-enabled;
            qcom,mdss-dsi-bl-max-level = <0xFFF>;
            qcom,mdss-dsi-bl-min-level = <0x1>;
            qcom,mdss-dsi-bl-pmic-control-type = "bl_ctrl_wled";
            qcom,mdss-dsi-bllp-eof-power-mode;
            qcom,mdss-dsi-bllp-power-mode;
            qcom,mdss-dsi-border-color = <0x0>;
            qcom,mdss-dsi-bpp = <0x18>;
            qcom,mdss-dsi-color-order = "rgb_swap_rgb";
            qcom,mdss-dsi-dma-trigger = "trigger_sw";
            qcom,mdss-dsi-h-sync-pulse = <0x0>;
            qcom,mdss-dsi-lane-0-state;
            qcom,mdss-dsi-lane-1-state;
            qcom,mdss-dsi-lane-2-state;
            qcom,mdss-dsi-lane-3-state;
            qcom,mdss-dsi-lane-map = "lane_map_0123";
            qcom,mdss-dsi-lp11-init;
            qcom,mdss-dsi-mdp-trigger = "none";
            qcom,mdss-dsi-panel-mode-switch;
            qcom,mdss-dsi-panel-name = "td4330 v2 cmd mode dsi truly panel";
            qcom,mdss-dsi-panel-on-check-value = <0x1C>;
            qcom,mdss-dsi-panel-status-check-mode = "reg_read";
            qcom,mdss-dsi-panel-status-command = <0x6010001 0x10A>;
            qcom,mdss-dsi-panel-status-command-state = "dsi_hs_mode";
            qcom,mdss-dsi-panel-status-read-length = <0x1>;
            qcom,mdss-dsi-panel-status-value = <0x1C>;
            qcom,mdss-dsi-panel-type = "dsi_cmd_mode";
            qcom,mdss-dsi-reset-sequence = <0x1 0xA 0x0 0xA 0x1 0xA>;
            qcom,mdss-dsi-stream = <0x0>;
            qcom,mdss-dsi-te-check-enable;
            qcom,mdss-dsi-te-dcs-command = <0x1>;
            qcom,mdss-dsi-te-pin-select = <0x1>;
            qcom,mdss-dsi-te-using-te-pin;
            qcom,mdss-dsi-traffic-mode = "non_burst_sync_event";
            qcom,mdss-dsi-tx-eot-append;
            qcom,mdss-dsi-underflow-color = <0xFF>;
            qcom,mdss-dsi-virtual-channel-id = <0x0>;
            qcom,mdss-dsi-wr-mem-continue = <0x3C>;
            qcom,mdss-dsi-wr-mem-start = <0x2C>;
            qcom,ulps-enabled;
            qcom,mdss-dsi-display-timings {
                timing@0 {
                    qcom,default-topology-index = <0x0>;
                    qcom,display-topology = <0x1 0x0 0x1>;
                    qcom,dsi-dyn-clk-list = <0x38491AB0 0x3758F3D0 0x3794FD88 0x37D10740 0x380D10F0>;
                    qcom,mdss-dsi-cmd-mode;
                    qcom,mdss-dsi-h-back-porch = <0x50>;
                    qcom,mdss-dsi-h-front-porch = <0x50>;
                    qcom,mdss-dsi-h-pulse-width = <0x14>;
                    qcom,mdss-dsi-h-sync-skew = <0x0>;
                    qcom,mdss-dsi-off-command = [05 01 00 00 32 00 02 28 00 05 01 00 00 96 00 02 10 00];
                    qcom,mdss-dsi-off-command-state = "dsi_hs_mode";
                    qcom,mdss-dsi-on-command = [29 01 00 00 00 00 02 B0 00 29 01 00 00 00 00 0D B6 30 6B 00 06 03 0A 13 1A 6C 18 19 02 29 01 00 00 00 00 05 B7 40 00 00 00 29 01 00 00 00 00 08 B8 57 3D 19 BE 1E 0A 0A 29 01 00 00 00 00 08 B9 6F 3D 28 BE 3C 14 0A 29 01 00 00 00 00 08 BA B5 33 41 BE 64 23 0A 29 01 00 00 00 00 0C BB 44 26 C3 1F 19 06 03 C0 00 00 10 29 01 00 00 00 00 0C BC 32 4C C3 52 32 1F 03 F2 00 00 13 29 01 00 00 00 00 0C BD 24 68 C3 AA 3F 32 03 FF 00 00 25 29 01 00 00 00 00 0D BE 00 00 00 00 00 00 00 00 00 00 00 00 29 01 00 00 00 00 0D C0 00 DC 00 DC 04 08 E8 00 04 00 03 78 29 01 00 00 00 00 24 C1 30 00 00 11 11 00 00 00 22 00 05 20 FA 00 08 00 00 00 00 00 00 00 00 00 00 00 00 00 00 00 00 00 00 00 00 29 01 00 00 00 00 79 C2 06 E0 6E 01 03 00 02 00 00 00 00 00 00 00 00 00 00 00 00 00 00 00 00 00 00 00 00 00 00 00 00 00 00 00 00 00 00 00 00 00 00 11 00 00 00 00 04 A0 C9 00 00 00 00 00 00 48 EB 00 00 01 00 00 00 11 00 00 00 00 00 00 00 00 00 00 00 00 00 00 00 00 00 00 00 00 11 00 00 00 00 00 00 DC 00 00 00 00 04 00 08 EF 00 00 00 00 00 11 00 00 00 00 00 00 00 00 00 00 00 00 00 00 29 01 00 00 00 00 6D C3 00 00 00 00 00 00 00 00 00 00 00 00 00 00 00 00 00 00 00 00 00 00 00 00 00 00 00 00 00 00 00 00 00 00 00 00 00 00 00 00 00 00 00 00 00 00 00 00 00 00 00 00 00 00 00 00 00 00 00 00 00 00 AA AA AA 00 00 00 00 00 00 00 00 00 00 00 00 00 00 00 00 00 00 00 00 00 00 00 00 00 00 00 00 00 00 00 00 00 00 00 00 00 00 00 00 00 00 00 29 01 00 00 00 00 62 C4 00 4C 00 3F 00 83 00 00 87 86 85 84 00 00 00 00 00 61 5D 5F 00 5E 60 62 00 00 00 02 00 83 00 00 87 86 85 84 00 00 00 00 00 61 5D 5F 00 5E 60 62 FF FF FF FF FF FF 00 0F 0E 00 0F 0E 00 00 00 00 00 00 00 0F EE 00 0F EE 00 00 E0 00 00 E0 0E 00 00 00 0E 00 00 00 00 00 FF 57 00 00 00 00 00 00 00 29 01 00 00 00 00 06 C5 08 00 00 00 00 29 01 00 00 00 00 3A C6 02 0A 08 FC FF FF FF 00 00 13 01 F0 0C 06 01 43 43 43 00 00 00 01 77 09 28 28 06 01 43 43 43 00 00 00 01 61 00 00 00 1C 01 00 00 00 00 00 00 00 00 00 00 00 00 20 20 00 00 29 01 00 00 00 00 4D C7 00 00 00 E0 01 E9 02 7E 02 05 02 90 02 F6 02 40 02 5C 02 77 02 C8 02 1B 02 5B 02 BD 02 27 02 C3 03 54 03 D8 03 FF 00 00 00 E0 01 E9 02 7E 02 05 02 90 02 F6 02 40 02 5C 02 77 02 C8 02 1B 02 5B 02 BD 02 27 02 C3 03 54 03 D8 03 FF 29 01 00 00 00 00 42 C8 41 00 FF FA 00 FF 00 00 FE F6 FE E9 00 00 FF F7 FB E1 00 00 00 00 00 FF 00 00 FF FA 00 FF 00 FE F6 FE E9 00 FF F7 FB E1 00 00 00 00 FF 00 FF FA 00 FF 00 FE F6 FE E9 00 FF F7 FB E1 00 00 00 00 FF 29 01 00 00 00 00 19 C9 00 FF FA 00 FF 00 00 FE F6 FE E9 00 00 FF F7 FB E1 00 00 00 00 00 FF 00 29 01 00 00 00 00 42 CA 1C FC FC FC 00 00 00 00 00 00 00 00 00 00 00 00 00 00 00 00 00 00 00 00 00 00 00 00 00 00 00 00 00 00 00 00 00 00 00 00 00 00 00 00 00 00 00 00 00 00 00 00 00 00 00 00 00 00 00 00 00 00 00 00 00 29 01 00 00 00 00 0B CC 00 00 4D 8B 55 4D 8B AA 4D 8B 29 01 00 00 00 00 02 CD 00 29 01 00 00 00 00 24 CE 5D 40 49 53 59 5E 63 68 6E 74 7E 8A 98 A8 BB D0 E7 FF 04 00 04 04 42 04 69 5A 40 11 F4 00 00 84 FA 00 00 29 01 00 00 00 00 07 CF 00 00 80 46 61 00 29 01 00 00 00 00 12 D0 F6 95 11 B1 55 CF 00 F6 D3 11 F0 01 12 CF 02 20 11 29 01 00 00 00 00 23 D1 D3 D3 33 33 07 03 3B 33 77 37 77 37 35 77 07 77 F7 33 73 07 33 33 03 33 1B 03 32 3D 0A 30 13 13 20 00 29 01 00 00 00 00 05 D2 00 00 07 00 29 01 00 00 00 00 9A D3 03 00 00 00 00 00 00 0F 00 57 00 00 32 00 00 1A 70 01 19 80 01 01 F0 02 00 E0 06 FF F7 FF FF F7 FF FF F7 FF FF F7 FF FF F7 FF FF F7 FF FF F7 FF FF F7 FF FF F7 FF FF F7 FF FF F7 FF FF F7 FF FF F7 FF FF F7 FF FF F7 FF FF F7 FF FF F7 FF FF F7 FF FF F7 FF FF F7 FF FF F7 FF FF F7 FF FF F7 FF FF F7 FF FF F7 FF FF F7 FF FF F7 FF FF F7 FF FF F7 FF FF F7 FF FF F7 FF FF F7 FF FF F7 FF FF F7 FF FF F7 FF FF F7 FF FF F7 FF FF F7 FF FF F7 FF FF F7 FF FF F7 FF FF F7 FF 29 01 00 00 00 00 05 E5 03 00 00 00 29 01 00 00 00 00 09 D5 02 42 02 42 02 DC 02 DC 29 01 00 00 00 00 02 D6 C0 29 01 00 00 00 00 32 D7 21 10 52 52 00 B6 04 FD 00 B6 04 FD 00 82 80 83 84 85 83 80 84 45 85 85 85 87 04 06 02 04 04 07 10 0C 0B 0A 0A 07 06 00 08 00 00 00 00 00 00 00 00 29 01 00 00 00 00 05 DD 30 06 23 65 29 01 00 00 00 00 0D DE 00 00 00 0F FF 00 00 00 00 00 00 10 29 01 00 00 00 00 02 E3 FF 29 01 00 00 00 00 07 E6 00 00 00 00 00 00 29 01 00 00 00 00 0B E7 50 04 00 00 00 00 00 00 00 00 29 01 00 00 00 00 05 E8 00 01 23 00 29 01 00 00 00 00 1E EA 01 02 47 80 47 00 00 00 05 00 13 60 02 47 80 47 00 00 00 00 13 60 00 11 00 30 10 21 02 29 01 00 00 00 00 08 EB 00 00 00 00 01 00 11 29 01 00 00 00 00 04 EC 00 00 00 29 01 00 00 00 00 21 ED 01 01 02 02 02 02 00 00 00 00 00 00 0A 00 00 00 00 10 00 18 00 18 00 B0 00 00 00 00 00 DA 10 00 29 01 00 00 00 00 61 EE 03 0F 00 00 00 00 40 1F 00 00 0F F2 3F 00 00 00 00 00 00 00 00 00 00 00 00 00 00 00 10 01 00 09 01 8C D8 EF 00 00 00 00 00 00 00 00 00 00 00 00 00 00 00 00 00 00 50 1F 00 00 00 00 00 00 00 00 00 00 00 00 00 00 00 00 00 00 00 00 00 00 00 00 00 00 00 00 00 00 00 00 00 00 00 00 00 00 00 00 29 01 00 00 00 00 8C EF 00 70 4A 08 D0 00 00 00 00 3C 3C 3C 00 00 00 00 00 00 00 00 00 00 00 00 00 00 00 00 70 4A 08 D0 00 00 00 00 3C 3C 3C 00 00 00 00 00 00 00 00 00 00 00 00 00 00 00 00 00 00 00 00 00 00 00 00 00 00 00 00 00 00 00 00 00 00 00 00 00 00 00 00 00 00 00 00 00 00 00 00 00 00 00 00 00 03 08 EC 50 10 00 10 00 0A 0A 00 00 00 00 10 0F 00 03 51 00 50 00 00 00 00 00 00 00 00 00 00 00 00 00 00 00 00 00 00 00 00 00 00 00 03 08 EC 29 01 00 00 00 00 02 B0 03 29 01 00 00 00 00 02 B0 04 29 01 00 00 00 00 02 D6 00 39 01 00 00 00 00 03 51 FF F0 39 01 00 00 00 00 02 53 0C 39 01 00 00 00 00 02 55 00 39 01 00 00 00 00 02 35 00 39 01 00 00 00 00 05 2A 00 00 04 37 39 01 00 00 00 00 05 2B 00 00 08 E7 05 01 00 00 FF 00 02 29 00 05 01 00 00 FF 00 02 11 00];
                    qcom,mdss-dsi-on-command-state = "dsi_lp_mode";
                    qcom,mdss-dsi-panel-framerate = <0x3C>;
                    qcom,mdss-dsi-panel-height = <0x8E8>;
                    qcom,mdss-dsi-panel-jitter = <0x4 0x1>;
                    qcom,mdss-dsi-panel-phy-timings = [00 23 09 09 26 24 09 09 09 02 04 00 1E 19];
                    qcom,mdss-dsi-panel-width = <0x438>;
                    qcom,mdss-dsi-v-back-porch = <0xD>;
                    qcom,mdss-dsi-v-front-porch = <0x10>;
                    qcom,mdss-dsi-v-pulse-width = <0x2>;
                    qcom,panel-roi-alignment = <0x28 0x28 0x28 0x28 0x28 0x28>;
                    qcom,partial-update-enabled = "single_roi";
                    qcom,video-to-cmd-mode-post-switch-commands = [15 01 00 00 00 00 02 B0 00 29 01 00 00 00 00 05 B7 40 00 00 00];
                    qcom,video-to-cmd-mode-post-switch-commands-state = "dsi_lp_mode";
                };
                timing@1 {
                    qcom,cmd-to-video-mode-post-switch-commands = [15 01 00 00 00 00 02 B0 00 29 01 00 00 00 00 05 B7 51 00 00 00];
                    qcom,cmd-to-video-mode-post-switch-commands-state = "dsi_lp_mode";
                    qcom,default-topology-index = <0x0>;
                    qcom,display-topology = <0x1 0x0 0x1>;
                    qcom,dsi-dyn-clk-list = <0x38491AB0 0x3758F3D0 0x3794FD88 0x37D10740 0x380D10F0>;
                    qcom,mdss-dsi-h-back-porch = <0x28>;
                    qcom,mdss-dsi-h-front-porch = <0x28>;
                    qcom,mdss-dsi-h-pulse-width = <0x14>;
                    qcom,mdss-dsi-h-sync-skew = <0x0>;
                    qcom,mdss-dsi-off-command = [05 01 00 00 32 00 02 28 00 05 01 00 00 96 00 02 10 00];
                    qcom,mdss-dsi-off-command-state = "dsi_hs_mode";
                    qcom,mdss-dsi-on-command = [29 01 00 00 00 00 02 B0 00 29 01 00 00 00 00 0D B6 30 6B 00 06 03 0A 13 1A 6C 18 19 02 29 01 00 00 00 00 05 B7 51 00 00 00 29 01 00 00 00 00 08 B8 57 3D 19 BE 1E 0A 0A 29 01 00 00 00 00 08 B9 6F 3D 28 BE 3C 14 0A 29 01 00 00 00 00 08 BA B5 33 41 BE 64 23 0A 29 01 00 00 00 00 0C BB 44 26 C3 1F 19 06 03 C0 00 00 10 29 01 00 00 00 00 0C BC 32 4C C3 52 32 1F 03 F2 00 00 13 29 01 00 00 00 00 0C BD 24 68 C3 AA 3F 32 03 FF 00 00 25 29 01 00 00 00 00 0D BE 00 00 00 00 00 00 00 00 00 00 00 00 29 01 00 00 00 00 0D C0 00 DC 00 DC 04 08 E8 00 04 00 03 78 29 01 00 00 00 00 24 C1 30 00 00 11 11 00 00 00 22 00 05 20 FA 00 08 00 00 00 00 00 00 00 00 00 00 00 00 00 00 00 00 00 00 00 00 29 01 00 00 00 00 79 C2 06 E0 6E 01 03 00 02 00 00 00 00 00 00 00 00 00 00 00 00 00 00 00 00 00 00 00 00 00 00 00 00 00 00 00 00 00 00 00 00 00 00 11 00 00 00 00 04 A0 C9 00 00 00 00 00 00 48 EB 00 00 01 00 00 00 11 00 00 00 00 00 00 00 00 00 00 00 00 00 00 00 00 00 00 00 00 11 00 00 00 00 00 00 DC 00 00 00 00 04 00 08 EF 00 00 00 00 00 11 00 00 00 00 00 00 00 00 00 00 00 00 00 00 29 01 00 00 00 00 6D C3 00 00 00 00 00 00 00 00 00 00 00 00 00 00 00 00 00 00 00 00 00 00 00 00 00 00 00 00 00 00 00 00 00 00 00 00 00 00 00 00 00 00 00 00 00 00 00 00 00 00 00 00 00 00 00 00 00 00 00 00 00 00 AA AA AA 00 00 00 00 00 00 00 00 00 00 00 00 00 00 00 00 00 00 00 00 00 00 00 00 00 00 00 00 00 00 00 00 00 00 00 00 00 00 00 00 00 00 00 29 01 00 00 00 00 62 C4 00 4C 00 3F 00 83 00 00 87 86 85 84 00 00 00 00 00 61 5D 5F 00 5E 60 62 00 00 00 02 00 83 00 00 87 86 85 84 00 00 00 00 00 61 5D 5F 00 5E 60 62 FF FF FF FF FF FF 00 0F 0E 00 0F 0E 00 00 00 00 00 00 00 0F EE 00 0F EE 00 00 E0 00 00 E0 0E 00 00 00 0E 00 00 00 00 00 FF 57 00 00 00 00 00 00 00 29 01 00 00 00 00 06 C5 08 00 00 00 00 29 01 00 00 00 00 3A C6 02 0A 08 FC FF FF FF 00 00 13 01 F0 0C 06 01 43 43 43 00 00 00 01 77 09 28 28 06 01 43 43 43 00 00 00 01 61 00 00 00 1C 01 00 00 00 00 00 00 00 00 00 00 00 00 20 20 00 00 29 01 00 00 00 00 4D C7 00 00 00 E0 01 E9 02 7E 02 05 02 90 02 F6 02 40 02 5C 02 77 02 C8 02 1B 02 5B 02 BD 02 27 02 C3 03 54 03 D8 03 FF 00 00 00 E0 01 E9 02 7E 02 05 02 90 02 F6 02 40 02 5C 02 77 02 C8 02 1B 02 5B 02 BD 02 27 02 C3 03 54 03 D8 03 FF 29 01 00 00 00 00 42 C8 41 00 FF FA 00 FF 00 00 FE F6 FE E9 00 00 FF F7 FB E1 00 00 00 00 00 FF 00 00 FF FA 00 FF 00 FE F6 FE E9 00 FF F7 FB E1 00 00 00 00 FF 00 FF FA 00 FF 00 FE F6 FE E9 00 FF F7 FB E1 00 00 00 00 FF 29 01 00 00 00 00 19 C9 00 FF FA 00 FF 00 00 FE F6 FE E9 00 00 FF F7 FB E1 00 00 00 00 00 FF 00 29 01 00 00 00 00 42 CA 1C FC FC FC 00 00 00 00 00 00 00 00 00 00 00 00 00 00 00 00 00 00 00 00 00 00 00 00 00 00 00 00 00 00 00 00 00 00 00 00 00 00 00 00 00 00 00 00 00 00 00 00 00 00 00 00 00 00 00 00 00 00 00 00 00 29 01 00 00 00 00 0B CC 00 00 4D 8B 55 4D 8B AA 4D 8B 29 01 00 00 00 00 02 CD 00 29 01 00 00 00 00 24 CE 5D 40 49 53 59 5E 63 68 6E 74 7E 8A 98 A8 BB D0 E7 FF 04 00 04 04 42 04 69 5A 40 11 F4 00 00 84 FA 00 00 29 01 00 00 00 00 07 CF 00 00 80 46 61 00 29 01 00 00 00 00 12 D0 F6 95 11 B1 55 CF 00 F6 D3 11 F0 01 12 CF 02 20 11 29 01 00 00 00 00 23 D1 D3 D3 33 33 07 03 3B 33 77 37 77 37 35 77 07 77 F7 33 73 07 33 33 03 33 1B 03 32 3D 0A 30 13 13 20 00 29 01 00 00 00 00 05 D2 00 00 07 00 29 01 00 00 00 00 9A D3 03 00 00 00 00 00 00 0F 00 57 00 00 32 00 00 1A 70 01 19 80 01 01 F0 02 00 E0 06 FF F7 FF FF F7 FF FF F7 FF FF F7 FF FF F7 FF FF F7 FF FF F7 FF FF F7 FF FF F7 FF FF F7 FF FF F7 FF FF F7 FF FF F7 FF FF F7 FF FF F7 FF FF F7 FF FF F7 FF FF F7 FF FF F7 FF FF F7 FF FF F7 FF FF F7 FF FF F7 FF FF F7 FF FF F7 FF FF F7 FF FF F7 FF FF F7 FF FF F7 FF FF F7 FF FF F7 FF FF F7 FF FF F7 FF FF F7 FF FF F7 FF FF F7 FF FF F7 FF FF F7 FF FF F7 FF FF F7 FF FF F7 FF FF F7 FF 29 01 00 00 00 00 05 E5 03 00 00 00 29 01 00 00 00 00 09 D5 02 42 02 42 02 DC 02 DC 29 01 00 00 00 00 02 D6 C0 29 01 00 00 00 00 32 D7 21 10 52 52 00 B6 04 FD 00 B6 04 FD 00 82 80 83 84 85 83 80 84 45 85 85 85 87 04 06 02 04 04 07 10 0C 0B 0A 0A 07 06 00 08 00 00 00 00 00 00 00 00 29 01 00 00 00 00 05 DD 30 06 23 65 29 01 00 00 00 00 0D DE 00 00 00 0F FF 00 00 00 00 00 00 10 29 01 00 00 00 00 02 E3 FF 29 01 00 00 00 00 07 E6 00 00 00 00 00 00 29 01 00 00 00 00 0B E7 50 04 00 00 00 00 00 00 00 00 29 01 00 00 00 00 05 E8 00 01 23 00 29 01 00 00 00 00 1E EA 01 02 47 80 47 00 00 00 05 00 12 60 02 47 80 47 00 00 00 00 13 60 00 11 00 30 10 21 02 29 01 00 00 00 00 08 EB 00 00 00 00 01 00 11 29 01 00 00 00 00 04 EC 00 00 00 29 01 00 00 00 00 21 ED 01 01 02 02 02 02 00 00 00 00 00 00 0A 00 00 00 00 10 00 18 00 18 00 B0 00 00 00 00 00 DA 10 00 29 01 00 00 00 00 61 EE 03 0F 00 00 00 00 40 1F 00 00 0F F2 3F 00 00 00 00 00 00 00 00 00 00 00 00 00 00 00 10 01 00 09 01 8C D8 EF 00 00 00 00 00 00 00 00 00 00 00 00 00 00 00 00 00 00 50 1F 00 00 00 00 00 00 00 00 00 00 00 00 00 00 00 00 00 00 00 00 00 00 00 00 00 00 00 00 00 00 00 00 00 00 00 00 00 00 00 00 29 01 00 00 00 00 8C EF 00 70 4A 08 D0 00 00 00 00 3C 3C 3C 00 00 00 00 00 00 00 00 00 00 00 00 00 00 00 00 70 4A 08 D0 00 00 00 00 3C 3C 3C 00 00 00 00 00 00 00 00 00 00 00 00 00 00 00 00 00 00 00 00 00 00 00 00 00 00 00 00 00 00 00 00 00 00 00 00 00 00 00 00 00 00 00 00 00 00 00 00 00 00 00 00 00 03 08 EC 50 10 00 10 00 0A 0A 00 00 00 00 10 0F 00 03 51 00 50 00 00 00 00 00 00 00 00 00 00 00 00 00 00 00 00 00 00 00 00 00 00 00 03 08 EC 29 01 00 00 00 00 02 B0 03 29 01 00 00 00 00 02 B0 04 29 01 00 00 00 00 02 D6 00 39 01 00 00 00 00 03 51 FF F0 39 01 00 00 00 00 02 53 0C 39 01 00 00 00 00 02 55 00 39 01 00 00 00 00 02 35 00 39 01 00 00 00 00 05 2A 00 00 04 37 39 01 00 00 00 00 05 2B 00 00 08 E7 05 01 00 00 FF 00 02 29 00 05 01 00 00 FF 00 02 11 00];
                    qcom,mdss-dsi-on-command-state = "dsi_lp_mode";
                    qcom,mdss-dsi-panel-framerate = <0x3C>;
                    qcom,mdss-dsi-panel-height = <0x8E8>;
                    qcom,mdss-dsi-panel-phy-timings = [00 21 08 08 25 22 09 08 09 02 04 00 1D 18];
                    qcom,mdss-dsi-panel-width = <0x438>;
                    qcom,mdss-dsi-v-back-porch = <0x6>;
                    qcom,mdss-dsi-v-front-porch = <0xA>;
                    qcom,mdss-dsi-v-pulse-width = <0x2>;
                    qcom,mdss-dsi-video-mode;
                };
            };
        };
        qcom,mdss_dsi_td4330_truly_v2_video {
            qcom,dsi-ctrl-num = <0x0>;
            qcom,dsi-dyn-clk-enable;
            qcom,dsi-dyn-clk-list = <0x3A2F7BC0 0x3AE9AD50 0x3AAB9CC8 0x3A6D8C48>;
            qcom,dsi-dyn-clk-type = "constant-fps-adjust-vfp";
            qcom,dsi-phy-num = <0x0>;
            qcom,dsi-select-clocks = "pll_byte_clk0", "pll_dsi_clk0";
            qcom,dsi-supported-dfps-list = <0x3C 0x37 0x30>;
            qcom,esd-check-enabled;
            qcom,mdss-dsi-bl-max-level = <0xFFF>;
            qcom,mdss-dsi-bl-min-level = <0x1>;
            qcom,mdss-dsi-bl-pmic-control-type = "bl_ctrl_wled";
            qcom,mdss-dsi-bllp-eof-power-mode;
            qcom,mdss-dsi-bllp-power-mode;
            qcom,mdss-dsi-border-color = <0x0>;
            qcom,mdss-dsi-bpp = <0x18>;
            qcom,mdss-dsi-color-order = "rgb_swap_rgb";
            qcom,mdss-dsi-dma-trigger = "trigger_sw";
            qcom,mdss-dsi-h-left-border = <0x0>;
            qcom,mdss-dsi-h-right-border = <0x0>;
            qcom,mdss-dsi-h-sync-pulse = <0x0>;
            qcom,mdss-dsi-lane-0-state;
            qcom,mdss-dsi-lane-1-state;
            qcom,mdss-dsi-lane-2-state;
            qcom,mdss-dsi-lane-3-state;
            qcom,mdss-dsi-lane-map = "lane_map_0123";
            qcom,mdss-dsi-lp11-init;
            qcom,mdss-dsi-mdp-trigger = "none";
            qcom,mdss-dsi-pan-enable-dynamic-fps;
            qcom,mdss-dsi-pan-fps-update = "dfps_immediate_porch_mode_vfp";
            qcom,mdss-dsi-panel-mode-switch;
            qcom,mdss-dsi-panel-name = "td4330 v2 video mode dsi truly panel";
            qcom,mdss-dsi-panel-on-check-value = <0x1C>;
            qcom,mdss-dsi-panel-status-check-mode = "reg_read";
            qcom,mdss-dsi-panel-status-command = <0x6010001 0x10A>;
            qcom,mdss-dsi-panel-status-command-state = "dsi_hs_mode";
            qcom,mdss-dsi-panel-status-read-length = <0x1>;
            qcom,mdss-dsi-panel-status-value = <0x1C>;
            qcom,mdss-dsi-panel-type = "dsi_video_mode";
            qcom,mdss-dsi-reset-sequence = <0x1 0xA 0x0 0xA 0x1 0xA>;
            qcom,mdss-dsi-stream = <0x0>;
            qcom,mdss-dsi-te-check-enable;
            qcom,mdss-dsi-te-dcs-command = <0x1>;
            qcom,mdss-dsi-te-pin-select = <0x1>;
            qcom,mdss-dsi-te-using-te-pin;
            qcom,mdss-dsi-traffic-mode = "non_burst_sync_event";
            qcom,mdss-dsi-tx-eot-append;
            qcom,mdss-dsi-underflow-color = <0xFF>;
            qcom,mdss-dsi-v-bottom-border = <0x0>;
            qcom,mdss-dsi-v-top-border = <0x0>;
            qcom,mdss-dsi-virtual-channel-id = <0x0>;
            qcom,mdss-dsi-wr-mem-continue = <0x3C>;
            qcom,mdss-dsi-wr-mem-start = <0x2C>;
            qcom,mdss-pan-physical-height-dimension = <0x81>;
            qcom,mdss-pan-physical-width-dimension = <0x41>;
            qcom,mdss-dsi-display-timings {
                timing@0 {
                    qcom,cmd-to-video-mode-post-switch-commands = [15 01 00 00 00 00 02 B0 00 29 01 00 00 00 00 05 B7 51 00 00 00];
                    qcom,cmd-to-video-mode-post-switch-commands-state = "dsi_lp_mode";
                    qcom,default-topology-index = <0x0>;
                    qcom,display-topology = <0x1 0x0 0x1>;
                    qcom,dsi-dyn-clk-list = <0x3A2F7BC0 0x3AE9AD50 0x3AAB9CC8 0x3A6D8C48>;
                    qcom,mdss-dsi-h-back-porch = <0x28>;
                    qcom,mdss-dsi-h-front-porch = <0x28>;
                    qcom,mdss-dsi-h-pulse-width = <0x14>;
                    qcom,mdss-dsi-h-sync-skew = <0x0>;
                    qcom,mdss-dsi-off-command = [05 01 00 00 32 00 02 28 00 05 01 00 00 96 00 02 10 00];
                    qcom,mdss-dsi-off-command-state = "dsi_hs_mode";
                    qcom,mdss-dsi-on-command = [29 01 00 00 00 00 02 B0 00 29 01 00 00 00 00 0D B6 30 6B 00 06 03 0A 13 1A 6C 18 19 02 29 01 00 00 00 00 05 B7 51 00 00 00 29 01 00 00 00 00 08 B8 57 3D 19 BE 1E 0A 0A 29 01 00 00 00 00 08 B9 6F 3D 28 BE 3C 14 0A 29 01 00 00 00 00 08 BA B5 33 41 BE 64 23 0A 29 01 00 00 00 00 0C BB 44 26 C3 1F 19 06 03 C0 00 00 10 29 01 00 00 00 00 0C BC 32 4C C3 52 32 1F 03 F2 00 00 13 29 01 00 00 00 00 0C BD 24 68 C3 AA 3F 32 03 FF 00 00 25 29 01 00 00 00 00 0D BE 00 00 00 00 00 00 00 00 00 00 00 00 29 01 00 00 00 00 0D C0 00 DC 00 DC 04 08 E8 00 04 00 03 78 29 01 00 00 00 00 24 C1 30 00 00 11 11 00 00 00 22 00 05 20 FA 00 08 00 00 00 00 00 00 00 00 00 00 00 00 00 00 00 00 00 00 00 00 29 01 00 00 00 00 79 C2 06 E0 6E 01 03 00 02 00 00 00 00 00 00 00 00 00 00 00 00 00 00 00 00 00 00 00 00 00 00 00 00 00 00 00 00 00 00 00 00 00 00 11 00 00 00 00 04 A0 C9 00 00 00 00 00 00 48 EB 00 00 01 00 00 00 11 00 00 00 00 00 00 00 00 00 00 00 00 00 00 00 00 00 00 00 00 11 00 00 00 00 00 00 DC 00 00 00 00 04 00 08 EF 00 00 00 00 00 11 00 00 00 00 00 00 00 00 00 00 00 00 00 00 29 01 00 00 00 00 6D C3 00 00 00 00 00 00 00 00 00 00 00 00 00 00 00 00 00 00 00 00 00 00 00 00 00 00 00 00 00 00 00 00 00 00 00 00 00 00 00 00 00 00 00 00 00 00 00 00 00 00 00 00 00 00 00 00 00 00 00 00 00 00 AA AA AA 00 00 00 00 00 00 00 00 00 00 00 00 00 00 00 00 00 00 00 00 00 00 00 00 00 00 00 00 00 00 00 00 00 00 00 00 00 00 00 00 00 00 00 29 01 00 00 00 00 62 C4 00 4C 00 3F 00 83 00 00 87 86 85 84 00 00 00 00 00 61 5D 5F 00 5E 60 62 00 00 00 02 00 83 00 00 87 86 85 84 00 00 00 00 00 61 5D 5F 00 5E 60 62 FF FF FF FF FF FF 00 0F 0E 00 0F 0E 00 00 00 00 00 00 00 0F EE 00 0F EE 00 00 E0 00 00 E0 0E 00 00 00 0E 00 00 00 00 00 FF 57 00 00 00 00 00 00 00 29 01 00 00 00 00 06 C5 08 00 00 00 00 29 01 00 00 00 00 3A C6 02 0A 08 FC FF FF FF 00 00 13 01 F0 0C 06 01 43 43 43 00 00 00 01 77 09 28 28 06 01 43 43 43 00 00 00 01 61 00 00 00 1C 01 00 00 00 00 00 00 00 00 00 00 00 00 20 20 00 00 29 01 00 00 00 00 4D C7 00 00 00 E0 01 E9 02 7E 02 05 02 90 02 F6 02 40 02 5C 02 77 02 C8 02 1B 02 5B 02 BD 02 27 02 C3 03 54 03 D8 03 FF 00 00 00 E0 01 E9 02 7E 02 05 02 90 02 F6 02 40 02 5C 02 77 02 C8 02 1B 02 5B 02 BD 02 27 02 C3 03 54 03 D8 03 FF 29 01 00 00 00 00 42 C8 41 00 FF FA 00 FF 00 00 FE F6 FE E9 00 00 FF F7 FB E1 00 00 00 00 00 FF 00 00 FF FA 00 FF 00 FE F6 FE E9 00 FF F7 FB E1 00 00 00 00 FF 00 FF FA 00 FF 00 FE F6 FE E9 00 FF F7 FB E1 00 00 00 00 FF 29 01 00 00 00 00 19 C9 00 FF FA 00 FF 00 00 FE F6 FE E9 00 00 FF F7 FB E1 00 00 00 00 00 FF 00 29 01 00 00 00 00 42 CA 1C FC FC FC 00 00 00 00 00 00 00 00 00 00 00 00 00 00 00 00 00 00 00 00 00 00 00 00 00 00 00 00 00 00 00 00 00 00 00 00 00 00 00 00 00 00 00 00 00 00 00 00 00 00 00 00 00 00 00 00 00 00 00 00 00 29 01 00 00 00 00 0B CC 00 00 4D 8B 55 4D 8B AA 4D 8B 29 01 00 00 00 00 02 CD 00 29 01 00 00 00 00 24 CE 5D 40 49 53 59 5E 63 68 6E 74 7E 8A 98 A8 BB D0 E7 FF 04 00 04 04 42 04 69 5A 40 11 F4 00 00 84 FA 00 00 29 01 00 00 00 00 07 CF 00 00 80 46 61 00 29 01 00 00 00 00 12 D0 F6 95 11 B1 55 CF 00 F6 D3 11 F0 01 12 CF 02 20 11 29 01 00 00 00 00 23 D1 D3 D3 33 33 07 03 3B 33 77 37 77 37 35 77 07 77 F7 33 73 07 33 33 03 33 1B 03 32 3D 0A 30 13 13 20 00 29 01 00 00 00 00 05 D2 00 00 07 00 29 01 00 00 00 00 9A D3 03 00 00 00 00 00 00 0F 00 57 00 00 32 00 00 1A 70 01 19 80 01 01 F0 02 00 E0 06 FF F7 FF FF F7 FF FF F7 FF FF F7 FF FF F7 FF FF F7 FF FF F7 FF FF F7 FF FF F7 FF FF F7 FF FF F7 FF FF F7 FF FF F7 FF FF F7 FF FF F7 FF FF F7 FF FF F7 FF FF F7 FF FF F7 FF FF F7 FF FF F7 FF FF F7 FF FF F7 FF FF F7 FF FF F7 FF FF F7 FF FF F7 FF FF F7 FF FF F7 FF FF F7 FF FF F7 FF FF F7 FF FF F7 FF FF F7 FF FF F7 FF FF F7 FF FF F7 FF FF F7 FF FF F7 FF FF F7 FF FF F7 FF FF F7 FF 29 01 00 00 00 00 05 E5 03 00 00 00 29 01 00 00 00 00 09 D5 02 42 02 42 02 DC 02 DC 29 01 00 00 00 00 02 D6 C0 29 01 00 00 00 00 32 D7 21 10 52 52 00 B6 04 FD 00 B6 04 FD 00 82 80 83 84 85 83 80 84 45 85 85 85 87 04 06 02 04 04 07 10 0C 0B 0A 0A 07 06 00 08 00 00 00 00 00 00 00 00 29 01 00 00 00 00 05 DD 30 06 23 65 29 01 00 00 00 00 0D DE 00 00 00 0F FF 00 00 00 00 00 00 10 29 01 00 00 00 00 02 E3 FF 29 01 00 00 00 00 07 E6 00 00 00 00 00 00 29 01 00 00 00 00 0B E7 50 04 00 00 00 00 00 00 00 00 29 01 00 00 00 00 05 E8 00 01 23 00 29 01 00 00 00 00 1E EA 01 02 47 80 47 00 00 00 05 00 12 60 02 47 80 47 00 00 00 00 13 60 00 11 00 30 10 21 02 29 01 00 00 00 00 08 EB 00 00 00 00 01 00 11 29 01 00 00 00 00 04 EC 00 00 00 29 01 00 00 00 00 21 ED 01 01 02 02 02 02 00 00 00 00 00 00 0A 00 00 00 00 10 00 18 00 18 00 B0 00 00 00 00 00 DA 10 00 29 01 00 00 00 00 61 EE 03 0F 00 00 00 00 40 1F 00 00 0F F2 3F 00 00 00 00 00 00 00 00 00 00 00 00 00 00 00 10 01 00 09 01 8C D8 EF 00 00 00 00 00 00 00 00 00 00 00 00 00 00 00 00 00 00 50 1F 00 00 00 00 00 00 00 00 00 00 00 00 00 00 00 00 00 00 00 00 00 00 00 00 00 00 00 00 00 00 00 00 00 00 00 00 00 00 00 00 29 01 00 00 00 00 8C EF 00 70 4A 08 D0 00 00 00 00 3C 3C 3C 00 00 00 00 00 00 00 00 00 00 00 00 00 00 00 00 70 4A 08 D0 00 00 00 00 3C 3C 3C 00 00 00 00 00 00 00 00 00 00 00 00 00 00 00 00 00 00 00 00 00 00 00 00 00 00 00 00 00 00 00 00 00 00 00 00 00 00 00 00 00 00 00 00 00 00 00 00 00 00 00 00 00 03 08 EC 50 10 00 10 00 0A 0A 00 00 00 00 10 0F 00 03 51 00 50 00 00 00 00 00 00 00 00 00 00 00 00 00 00 00 00 00 00 00 00 00 00 00 03 08 EC 29 01 00 00 00 00 02 B0 03 29 01 00 00 00 00 02 B0 04 29 01 00 00 00 00 02 D6 00 39 01 00 00 00 00 03 51 FF F0 39 01 00 00 00 00 02 53 0C 39 01 00 00 00 00 02 55 00 39 01 00 00 00 00 02 35 00 39 01 00 00 00 00 05 2A 00 00 04 37 39 01 00 00 00 00 05 2B 00 00 08 E7 05 01 00 00 FF 00 02 29 00 05 01 00 00 FF 00 02 11 00];
                    qcom,mdss-dsi-on-command-state = "dsi_lp_mode";
                    qcom,mdss-dsi-panel-framerate = <0x3C>;
                    qcom,mdss-dsi-panel-height = <0x8E8>;
                    qcom,mdss-dsi-panel-phy-timings = [00 21 08 08 25 22 09 08 09 02 04 00 1D 18];
                    qcom,mdss-dsi-panel-width = <0x438>;
                    qcom,mdss-dsi-v-back-porch = <0x6>;
                    qcom,mdss-dsi-v-front-porch = <0xA>;
                    qcom,mdss-dsi-v-pulse-width = <0x2>;
                    qcom,mdss-dsi-video-mode;
                };
                timing@1 {
                    qcom,default-topology-index = <0x0>;
                    qcom,display-topology = <0x1 0x0 0x1>;
                    qcom,dsi-dyn-clk-list = <0x3A2F7BC0 0x3AE9AD50 0x3AAB9CC8 0x3A6D8C48>;
                    qcom,mdss-dsi-cmd-mode;
                    qcom,mdss-dsi-h-back-porch = <0x50>;
                    qcom,mdss-dsi-h-front-porch = <0x50>;
                    qcom,mdss-dsi-h-pulse-width = <0x14>;
                    qcom,mdss-dsi-h-sync-skew = <0x0>;
                    qcom,mdss-dsi-off-command = [05 01 00 00 32 00 02 28 00 05 01 00 00 96 00 02 10 00];
                    qcom,mdss-dsi-off-command-state = "dsi_hs_mode";
                    qcom,mdss-dsi-on-command = [29 01 00 00 00 00 02 B0 00 29 01 00 00 00 00 0D B6 30 6B 00 06 03 0A 13 1A 6C 18 19 02 29 01 00 00 00 00 05 B7 40 00 00 00 29 01 00 00 00 00 08 B8 57 3D 19 BE 1E 0A 0A 29 01 00 00 00 00 08 B9 6F 3D 28 BE 3C 14 0A 29 01 00 00 00 00 08 BA B5 33 41 BE 64 23 0A 29 01 00 00 00 00 0C BB 44 26 C3 1F 19 06 03 C0 00 00 10 29 01 00 00 00 00 0C BC 32 4C C3 52 32 1F 03 F2 00 00 13 29 01 00 00 00 00 0C BD 24 68 C3 AA 3F 32 03 FF 00 00 25 29 01 00 00 00 00 0D BE 00 00 00 00 00 00 00 00 00 00 00 00 29 01 00 00 00 00 0D C0 00 DC 00 DC 04 08 E8 00 04 00 03 78 29 01 00 00 00 00 24 C1 30 00 00 11 11 00 00 00 22 00 05 20 FA 00 08 00 00 00 00 00 00 00 00 00 00 00 00 00 00 00 00 00 00 00 00 29 01 00 00 00 00 79 C2 06 E0 6E 01 03 00 02 00 00 00 00 00 00 00 00 00 00 00 00 00 00 00 00 00 00 00 00 00 00 00 00 00 00 00 00 00 00 00 00 00 00 11 00 00 00 00 04 A0 C9 00 00 00 00 00 00 48 EB 00 00 01 00 00 00 11 00 00 00 00 00 00 00 00 00 00 00 00 00 00 00 00 00 00 00 00 11 00 00 00 00 00 00 DC 00 00 00 00 04 00 08 EF 00 00 00 00 00 11 00 00 00 00 00 00 00 00 00 00 00 00 00 00 29 01 00 00 00 00 6D C3 00 00 00 00 00 00 00 00 00 00 00 00 00 00 00 00 00 00 00 00 00 00 00 00 00 00 00 00 00 00 00 00 00 00 00 00 00 00 00 00 00 00 00 00 00 00 00 00 00 00 00 00 00 00 00 00 00 00 00 00 00 00 AA AA AA 00 00 00 00 00 00 00 00 00 00 00 00 00 00 00 00 00 00 00 00 00 00 00 00 00 00 00 00 00 00 00 00 00 00 00 00 00 00 00 00 00 00 00 29 01 00 00 00 00 62 C4 00 4C 00 3F 00 83 00 00 87 86 85 84 00 00 00 00 00 61 5D 5F 00 5E 60 62 00 00 00 02 00 83 00 00 87 86 85 84 00 00 00 00 00 61 5D 5F 00 5E 60 62 FF FF FF FF FF FF 00 0F 0E 00 0F 0E 00 00 00 00 00 00 00 0F EE 00 0F EE 00 00 E0 00 00 E0 0E 00 00 00 0E 00 00 00 00 00 FF 57 00 00 00 00 00 00 00 29 01 00 00 00 00 06 C5 08 00 00 00 00 29 01 00 00 00 00 3A C6 02 0A 08 FC FF FF FF 00 00 13 01 F0 0C 06 01 43 43 43 00 00 00 01 77 09 28 28 06 01 43 43 43 00 00 00 01 61 00 00 00 1C 01 00 00 00 00 00 00 00 00 00 00 00 00 20 20 00 00 29 01 00 00 00 00 4D C7 00 00 00 E0 01 E9 02 7E 02 05 02 90 02 F6 02 40 02 5C 02 77 02 C8 02 1B 02 5B 02 BD 02 27 02 C3 03 54 03 D8 03 FF 00 00 00 E0 01 E9 02 7E 02 05 02 90 02 F6 02 40 02 5C 02 77 02 C8 02 1B 02 5B 02 BD 02 27 02 C3 03 54 03 D8 03 FF 29 01 00 00 00 00 42 C8 41 00 FF FA 00 FF 00 00 FE F6 FE E9 00 00 FF F7 FB E1 00 00 00 00 00 FF 00 00 FF FA 00 FF 00 FE F6 FE E9 00 FF F7 FB E1 00 00 00 00 FF 00 FF FA 00 FF 00 FE F6 FE E9 00 FF F7 FB E1 00 00 00 00 FF 29 01 00 00 00 00 19 C9 00 FF FA 00 FF 00 00 FE F6 FE E9 00 00 FF F7 FB E1 00 00 00 00 00 FF 00 29 01 00 00 00 00 42 CA 1C FC FC FC 00 00 00 00 00 00 00 00 00 00 00 00 00 00 00 00 00 00 00 00 00 00 00 00 00 00 00 00 00 00 00 00 00 00 00 00 00 00 00 00 00 00 00 00 00 00 00 00 00 00 00 00 00 00 00 00 00 00 00 00 00 29 01 00 00 00 00 0B CC 00 00 4D 8B 55 4D 8B AA 4D 8B 29 01 00 00 00 00 02 CD 00 29 01 00 00 00 00 24 CE 5D 40 49 53 59 5E 63 68 6E 74 7E 8A 98 A8 BB D0 E7 FF 04 00 04 04 42 04 69 5A 40 11 F4 00 00 84 FA 00 00 29 01 00 00 00 00 07 CF 00 00 80 46 61 00 29 01 00 00 00 00 12 D0 F6 95 11 B1 55 CF 00 F6 D3 11 F0 01 12 CF 02 20 11 29 01 00 00 00 00 23 D1 D3 D3 33 33 07 03 3B 33 77 37 77 37 35 77 07 77 F7 33 73 07 33 33 03 33 1B 03 32 3D 0A 30 13 13 20 00 29 01 00 00 00 00 05 D2 00 00 07 00 29 01 00 00 00 00 9A D3 03 00 00 00 00 00 00 0F 00 57 00 00 32 00 00 1A 70 01 19 80 01 01 F0 02 00 E0 06 FF F7 FF FF F7 FF FF F7 FF FF F7 FF FF F7 FF FF F7 FF FF F7 FF FF F7 FF FF F7 FF FF F7 FF FF F7 FF FF F7 FF FF F7 FF FF F7 FF FF F7 FF FF F7 FF FF F7 FF FF F7 FF FF F7 FF FF F7 FF FF F7 FF FF F7 FF FF F7 FF FF F7 FF FF F7 FF FF F7 FF FF F7 FF FF F7 FF FF F7 FF FF F7 FF FF F7 FF FF F7 FF FF F7 FF FF F7 FF FF F7 FF FF F7 FF FF F7 FF FF F7 FF FF F7 FF FF F7 FF FF F7 FF FF F7 FF 29 01 00 00 00 00 05 E5 03 00 00 00 29 01 00 00 00 00 09 D5 02 42 02 42 02 DC 02 DC 29 01 00 00 00 00 02 D6 C0 29 01 00 00 00 00 32 D7 21 10 52 52 00 B6 04 FD 00 B6 04 FD 00 82 80 83 84 85 83 80 84 45 85 85 85 87 04 06 02 04 04 07 10 0C 0B 0A 0A 07 06 00 08 00 00 00 00 00 00 00 00 29 01 00 00 00 00 05 DD 30 06 23 65 29 01 00 00 00 00 0D DE 00 00 00 0F FF 00 00 00 00 00 00 10 29 01 00 00 00 00 02 E3 FF 29 01 00 00 00 00 07 E6 00 00 00 00 00 00 29 01 00 00 00 00 0B E7 50 04 00 00 00 00 00 00 00 00 29 01 00 00 00 00 05 E8 00 01 23 00 29 01 00 00 00 00 1E EA 01 02 47 80 47 00 00 00 05 00 13 60 02 47 80 47 00 00 00 00 13 60 00 11 00 30 10 21 02 29 01 00 00 00 00 08 EB 00 00 00 00 01 00 11 29 01 00 00 00 00 04 EC 00 00 00 29 01 00 00 00 00 21 ED 01 01 02 02 02 02 00 00 00 00 00 00 0A 00 00 00 00 10 00 18 00 18 00 B0 00 00 00 00 00 DA 10 00 29 01 00 00 00 00 61 EE 03 0F 00 00 00 00 40 1F 00 00 0F F2 3F 00 00 00 00 00 00 00 00 00 00 00 00 00 00 00 10 01 00 09 01 8C D8 EF 00 00 00 00 00 00 00 00 00 00 00 00 00 00 00 00 00 00 50 1F 00 00 00 00 00 00 00 00 00 00 00 00 00 00 00 00 00 00 00 00 00 00 00 00 00 00 00 00 00 00 00 00 00 00 00 00 00 00 00 00 29 01 00 00 00 00 8C EF 00 70 4A 08 D0 00 00 00 00 3C 3C 3C 00 00 00 00 00 00 00 00 00 00 00 00 00 00 00 00 70 4A 08 D0 00 00 00 00 3C 3C 3C 00 00 00 00 00 00 00 00 00 00 00 00 00 00 00 00 00 00 00 00 00 00 00 00 00 00 00 00 00 00 00 00 00 00 00 00 00 00 00 00 00 00 00 00 00 00 00 00 00 00 00 00 00 03 08 EC 50 10 00 10 00 0A 0A 00 00 00 00 10 0F 00 03 51 00 50 00 00 00 00 00 00 00 00 00 00 00 00 00 00 00 00 00 00 00 00 00 00 00 03 08 EC 29 01 00 00 00 00 02 B0 03 29 01 00 00 00 00 02 B0 04 29 01 00 00 00 00 02 D6 00 39 01 00 00 00 00 03 51 FF F0 39 01 00 00 00 00 02 53 0C 39 01 00 00 00 00 02 55 00 39 01 00 00 00 00 02 35 00 39 01 00 00 00 00 05 2A 00 00 04 37 39 01 00 00 00 00 05 2B 00 00 08 E7 05 01 00 00 FF 00 02 29 00 05 01 00 00 FF 00 02 11 00];
                    qcom,mdss-dsi-on-command-state = "dsi_lp_mode";
                    qcom,mdss-dsi-panel-framerate = <0x3C>;
                    qcom,mdss-dsi-panel-height = <0x8E8>;
                    qcom,mdss-dsi-panel-jitter = <0x4 0x1>;
                    qcom,mdss-dsi-panel-phy-timings = [00 23 09 09 26 24 09 09 09 02 04 00 1E 19];
                    qcom,mdss-dsi-panel-width = <0x438>;
                    qcom,mdss-dsi-v-back-porch = <0xD>;
                    qcom,mdss-dsi-v-front-porch = <0x10>;
                    qcom,mdss-dsi-v-pulse-width = <0x2>;
                    qcom,video-to-cmd-mode-post-switch-commands = [15 01 00 00 00 00 02 B0 00 29 01 00 00 00 00 05 B7 40 00 00 00];
                    qcom,video-to-cmd-mode-post-switch-commands-state = "dsi_lp_mode";
                };
            };
        };
        qcom,platform-supply-entries {
            #address-cells = <0x1>;
            #size-cells = <0x0>;
            qcom,platform-supply-entry@0 {
                qcom,supply-disable-load = <0x0>;
                qcom,supply-enable-load = <0x0>;
                qcom,supply-max-voltage = <0x0>;
                qcom,supply-min-voltage = <0x0>;
                qcom,supply-name = "sde-vdd";
                reg = <0x0>;
            };
        };
        qcom,sde-dspp-blocks {
            qcom,sde-dspp-dither = <0x82C 0x10007>;
            qcom,sde-dspp-gc = <0x17C0 0x10008>;
            qcom,sde-dspp-hist = <0x800 0x10007>;
            qcom,sde-dspp-hsic = <0x800 0x10007>;
            qcom,sde-dspp-igc = <0x0 0x30001>;
            qcom,sde-dspp-memcolor = <0x880 0x10007>;
            qcom,sde-dspp-pcc = <0x1700 0x40000>;
            qcom,sde-dspp-sixzone = <0x900 0x10007>;
            qcom,sde-dspp-vlut = <0xA00 0x10008>;
        };
        qcom,sde-limits {
            qcom,sde-bw-limits {
                qcom,sde-limit-cases = "per_vig_pipe", "per_dma_pipe", "total_max_bw", "camera_concurrency";
                qcom,sde-limit-ids = <0x1 0x2 0x4 0x8>;
                qcom,sde-limit-name = "sde_bwlimit_usecases";
                qcom,sde-limit-values = <0x1 0x30D400 0x9 0x30D400 0x2 0x30D400 0xA 0x30D400 0x4 0x419CE0 0xC 0x30D400>;
            };
            qcom,sde-linewidth-limits {
                qcom,sde-limit-cases = "vig", "dma", "scale";
                qcom,sde-limit-ids = <0x1 0x2 0x4>;
                qcom,sde-limit-name = "sspp_linewidth_usecases";
                qcom,sde-limit-values = <0x1 0x1000 0x5 0xA00 0x2 0x870>;
            };
        };
        qcom,sde-sspp-vig-blocks {
            qcom,sde-vig-csc-off = <0x1A00>;
            qcom,sde-vig-inverse-pma;
            qcom,sde-vig-qseed-off = <0xA00>;
            qcom,sde-vig-qseed-size = <0xA0>;
        };
    };
    qcom,mdss_rotator {
        #list-cells = <0x1>;
        clock-names = "gcc_iface", "iface_clk", "rot_clk";
        clocks = <&gcc 0x3C &dispcc 0x0 &dispcc 0xE>;
        compatible = "qcom,sde_rotator";
        interconnect-names = "qcom,rot-data-bus0", "qcom,sde-reg-bus";
        interconnects = <&mmrt_virt 0xE &bimc 0x200 &bimc 0x0 &config_noc 0x212>;
        interrupt-parent = <&mdss_mdp>;
        interrupts = <0x2 0x0>;
        power-domains = <&mdss_mdp>;
        qcom,mdss-default-ot-rd-limit = <0x20>;
        qcom,mdss-default-ot-wr-limit = <0x20>;
        qcom,mdss-rot-cdp-setting = <0x1 0x1>;
        qcom,mdss-rot-danger-lut = <0x0 0x0>;
        qcom,mdss-rot-mode = <0x1>;
        qcom,mdss-rot-parent = <&mdss_mdp 0x0>;
        qcom,mdss-rot-qos-lut = <0x0 0x0 0x0 0x0>;
        qcom,mdss-rot-safe-lut = <0xFFFF 0xFFFF>;
        qcom,mdss-rot-vbif-qos-setting = <0x3 0x3 0x3 0x3 0x3 0x3 0x3 0x3>;
        qcom,mdss-rot-xin-id = <0xA 0xB>;
        qcom,mdss-sbuf-headroom = <0x14>;
        qcom,msm-bus,name = "mdss_rotator";
        qcom,msm-bus,num-cases = <0x3>;
        qcom,msm-bus,num-paths = <0x1>;
        qcom,msm-bus,vectors-KBps = <0x16 0x200 0x0 0x0 0x16 0x200 0x0 0x61A800 0x16 0x200 0x0 0x61A800>;
        qcom,sde-reg-bus,vectors-KBps = <0x0 0x0 0x0 0x12C00>;
        qcom,supply-names = "rot-vdd";
        reg = <0x5E00000 0xAC000 0x5EB0000 0x2008>;
        reg-names = "mdp_phys", "rot_vbif_phys";
        rot-vdd-supply = <&mdss_core_gdsc>;
        qcom,smmu_rot_sec_cb {
            compatible = "qcom,smmu_sde_rot_sec";
            iommus = <&apps_smmu 0x43D 0x0>;
            qcom,iommu-dma-addr-pool = <0x20000 0xFFFE0000>;
            qcom,iommu-faults = "non-fatal";
            qcom,iommu-vmid = <0xA>;
        };
        qcom,smmu_rot_unsec_cb {
            compatible = "qcom,smmu_sde_rot_unsec";
            iommus = <&apps_smmu 0x43C 0x0>;
            qcom,iommu-dma-addr-pool = <0x20000 0xFFFE0000>;
            qcom,iommu-faults = "non-fatal";
        };
    };
    qcom,msm_notifier@0 {
        compatible = "qcom,msm-notifier";
    };
    qcom,smmu_sde_sec_cb {
        compatible = "qcom,smmu_sde_sec";
        iommus = <&apps_smmu 0x421 0x0>;
        qcom,iommu-dma-addr-pool = <0x20000 0xFFFE0000>;
        qcom,iommu-faults = "non-fatal";
        qcom,iommu-vmid = <0xA>;
    };
    qcom,smmu_sde_unsec_cb {
        compatible = "qcom,smmu_sde_unsec";
        iommus = <&apps_smmu 0x420 0x2>;
        qcom,iommu-dma-addr-pool = <0x20000 0xFFFE0000>;
        qcom,iommu-earlymap;
        qcom,iommu-faults = "non-fatal";
    };
    qcom,wb-display@0 {
        cell-index = <0x0>;
        compatible = "qcom,wb-display";
        label = "wb_display";
        status = "disabled";
    };
    rx_core_clk {
        #clock-cells = <0x1>;
        compatible = "qcom,audio-ref-clk";
        qcom,codec-ext-clk-src = <0x5>;
        qcom,codec-lpass-clk-id = <0x30E>;
        qcom,codec-lpass-ext-clk-freq = <0x1588800>;
    };
    rx_npl_clk {
        #clock-cells = <0x1>;
        compatible = "qcom,audio-ref-clk";
        qcom,codec-ext-clk-src = <0x6>;
        qcom,codec-lpass-clk-id = <0x30F>;
        qcom,codec-lpass-ext-clk-freq = <0x1588800>;
    };
    thermal-message {
        board-sensor = "VIRTUAL-SENSOR";
    };
    thermal-screen {
        panel = <&dsi_n7_38_0c_0a_video>;
    };
    tx_core_clk {
        #clock-cells = <0x1>;
        compatible = "qcom,audio-ref-clk";
        qcom,codec-ext-clk-src = <0x7>;
        qcom,codec-lpass-clk-id = <0x30C>;
        qcom,codec-lpass-ext-clk-freq = <0x124F800>;
    };
    tx_npl_clk {
        #clock-cells = <0x1>;
        compatible = "qcom,audio-ref-clk";
        qcom,codec-ext-clk-src = <0x8>;
        qcom,codec-lpass-clk-id = <0x30D>;
        qcom,codec-lpass-ext-clk-freq = <0x124F800>;
    };
    va_core_clk {
        #clock-cells = <0x1>;
        compatible = "qcom,audio-ref-clk";
        qcom,codec-ext-clk-src = <0x2>;
        qcom,codec-lpass-clk-id = <0x307>;
        qcom,codec-lpass-ext-clk-freq = <0x124F800>;
    };
    va_npl_clk {
        #clock-cells = <0x1>;
        compatible = "qcom,audio-ref-clk";
        qcom,codec-ext-clk-src = <0xA>;
        qcom,codec-lpass-clk-id = <0x308>;
        qcom,codec-lpass-ext-clk-freq = <0x124F800>;
    };
    vdda_usb_ss_dp_core {
        compatible = "regulator-fixed";
        enable-active-high;
        gpio = <&pm6125_gpios 0x1 0x0>;
        pinctrl-0 = <&usb_eldo9>;
        pinctrl-names = "default";
        regulator-max-microvolt = <0xD6D80>;
        regulator-min-microvolt = <0xD6D80>;
        regulator-name = "vdd_supply";
    };
    wsa_ana_clk {
        #clock-cells = <0x1>;
        compatible = "qcom,audio-ref-clk";
        qcom,codec-ext-clk-src = <0x3>;
        qcom,codec-lpass-clk-id = <0x301>;
        qcom,codec-lpass-ext-clk-freq = <0x927C00>;
    };
};

&spf_core_platform {
    cdc_pri_mi2s_gpios: pri_mi2s_pinctrl {
        #gpio-cells = <0x0>;
        compatible = "qcom,msm-cdc-pinctrl";
        pinctrl-0 = <&lpi_i2s1_sck_active &lpi_i2s1_ws_active &lpi_i2s1_sd0_active &lpi_i2s1_sd1_active>;
        pinctrl-1 = <&lpi_i2s1_sck_sleep &lpi_i2s1_ws_sleep &lpi_i2s1_sd0_sleep &lpi_i2s1_sd1_sleep>;
        pinctrl-names = "aud_active", "aud_sleep";
        qcom,lpi-gpios;
    };
    cdc_sec_mi2s_gpios: sec_mi2s_pinctrl {
        #gpio-cells = <0x0>;
        compatible = "qcom,msm-cdc-pinctrl";
        pinctrl-0 = <&lpi_i2s2_sck_active &lpi_i2s2_ws_active &lpi_i2s2_sd0_active &lpi_i2s2_sd1_active>;
        pinctrl-1 = <&lpi_i2s2_sck_sleep &lpi_i2s2_ws_sleep &lpi_i2s2_sd0_sleep &lpi_i2s2_sd1_sleep>;
        pinctrl-names = "aud_active", "aud_sleep";
        qcom,lpi-gpios;
    };
    bengal_snd: sound {
        asoc-codec = <&stub_codec &bolero_cdc &wcd937x_codec &wsa881x_i2c_e>;
        asoc-codec-names = "msm-stub-codec.1", "bolero-codec", "wcd937x_codec", "wsa-codec0";
        nvmem-cell-names = "adsp_variant";
        nvmem-cells = <&adsp_variant>;
        qcom,audio-routing = "AMIC1", "Analog Mic1", "AMIC1", "MIC BIAS1", "AMIC2", "Analog Mic2", "AMIC2", "MIC BIAS2", "AMIC3", "Analog Mic3", "AMIC3", "MIC BIAS3", "TX DMIC0", "Digital Mic0", "TX DMIC0", "MIC BIAS1", "TX DMIC1", "Digital Mic1", "TX DMIC1", "MIC BIAS1", "TX DMIC2", "Digital Mic2", "TX DMIC2", "MIC BIAS3", "TX DMIC3", "Digital Mic3", "TX DMIC3", "MIC BIAS3", "IN1_HPHL", "HPHL_OUT", "IN2_HPHR", "HPHR_OUT", "IN3_AUX", "AUX_OUT", "RX_TX DEC0_INP", "TX DEC0 MUX", "RX_TX DEC1_INP", "TX DEC1 MUX", "RX_TX DEC2_INP", "TX DEC2 MUX", "RX_TX DEC3_INP", "TX DEC3 MUX", "SpkrMono WSA_IN", "AUX", "TX SWR_INPUT", "WCD_TX_OUTPUT", "VA SWR_INPUT", "VA_SWR_CLK", "VA SWR_INPUT", "WCD_TX_OUTPUT", "TX_AIF1 CAP", "VA_SWR_CLK", "TX_AIF2 CAP", "VA_SWR_CLK", "TX_AIF3 CAP", "VA_SWR_CLK", "VA DMIC0", "Digital Mic0", "VA DMIC1", "Digital Mic1", "VA DMIC2", "Digital Mic2", "VA DMIC3", "Digital Mic3", "VA DMIC0", "VA MIC BIAS1", "VA DMIC1", "VA MIC BIAS1", "VA DMIC2", "VA MIC BIAS3", "VA DMIC3", "VA MIC BIAS3";
        qcom,cdc-dmic01-gpios = <&cdc_dmic01_gpios>;
        qcom,cdc-dmic23-gpios = <&cdc_dmic23_gpios>;
        qcom,model = "bengal-idp-snd-card";
        qcom,msm-mbhc-gnd-swh = <0x1>;
        qcom,msm-mbhc-hphl-swh = <0x1>;
        qcom,msm-mbhc-usbc-audio-supported = <0x0>;
        qcom,msm-mi2s-master = <0x1 0x1 0x1 0x1>;
        qcom,msm_audio_ssr_devs = <&audio_gpr &lpi_tlmm &bolero_cdc>;
        qcom,rxtx-bolero-codec = <0x1>;
        qcom,va-bolero-codec = <0x1>;
        qcom,wcn-btfm = <0x1>;
        qcom,wsa-aux-dev-prefix = "SpkrMono";
        qcom,wsa-max-devs = <0x1>;
    };
};

&spmi_bus {
    #address-cells = <0x2>;
    #interrupt-cells = <0x4>;
    #size-cells = <0x0>;
    interrupt-controller;
    qcom,pm7250b@2 {
        #address-cells = <0x1>;
        #size-cells = <0x0>;
        compatible = "qcom,spmi-pmic";
        reg = <0x2 0x0>;
        pm7250b_adc_tm: adc_tm@3500 {
            #address-cells = <0x1>;
            #size-cells = <0x0>;
            #thermal-sensor-cells = <0x1>;
            compatible = "qcom,spmi-adc-tm5";
            interrupt-names = "pm-adc-tm5";
            interrupts = <0x2 0x35 0x0 0x1>;
            reg = <0x3500>;
            status = "ok";
            charger_skin_therm@4d {
                io-channels = <&pm7250b_vadc 0x4D>;
                qcom,hw-settle-time-us = <0xC8>;
                qcom,ratiometric;
                reg = <0x0>;
            };
            conn_therm@4f {
                io-channels = <&pm7250b_vadc 0x4F>;
                qcom,hw-settle-time-us = <0xC8>;
                qcom,ratiometric;
                reg = <0x1>;
            };
        };
        bcl_soc: bcl-soc {
            #thermal-sensor-cells = <0x0>;
            compatible = "qcom,msm-bcl-soc";
        };
        pm7250b_bcl: bcl@1d00 {
            #thermal-sensor-cells = <0x1>;
            compatible = "qcom,bcl-v5";
            interrupt-names = "bcl-lvl0", "bcl-lvl1", "bcl-lvl2";
            interrupts = <0x2 0x1D 0x0 0x0 0x2 0x1D 0x1 0x0 0x2 0x1D 0x2 0x0>;
            reg = <0x1D00>;
        };
        pm7250b_clkdiv: clock-controller@5b00 {
            #clock-cells = <0x1>;
            assigned-clock-rates = <0x124F800>;
            assigned-clocks = <&pm7250b_clkdiv 0x1>;
            clock-names = "xo";
            clock-output-names = "pm7250b_div_clk1";
            clocks = <&rpmcc 0x0>;
            compatible = "qcom,spmi-clkdiv";
            qcom,num-clkdivs = <0x1>;
            reg = <0x5B00>;
        };
        pm7250b_gpios: pinctrl@c000 {
            #gpio-cells = <0x2>;
            #interrupt-cells = <0x2>;
            compatible = "qcom,pm7250b-gpio";
            gpio-controller;
            interrupt-controller;
            reg = <0xC000>;
            disp_lcd_bias_en {
                disp_lcd_bias_en_default: disp_lcd_bias_en_default {
                    bias-disable;
                    function = "func1";
                    input-disable;
                    output-enable;
                    pins = "gpio5";
                    power-source = <0x0>;
                    qcom,drive-strength = <0x2>;
                };
            };
        };
        pm7250b_charger: qcom,qpnp-smb5 {
            #address-cells = <0x1>;
            #cooling-cells = <0x2>;
            #size-cells = <0x1>;
            compatible = "qcom,pm7250b-smb5";
            depends-on-supply = <&pm7250b_vadc>;
            dpdm-supply = <&usb2_phy0>;
            io-channel-names = "usb_in_voltage", "usb_in_current", "chg_temp", "die_temp", "conn_temp", "sbux_res", "vph_voltage";
            io-channels = <&pm7250b_vadc 0x8 &pm7250b_vadc 0x7 &pm7250b_vadc 0x9 &pm7250b_vadc 0x6 &pm7250b_vadc 0x4F &pm7250b_vadc 0x99 &pm7250b_vadc 0x83>;
            qcom,auto-recharge-soc = <0x62>;
            qcom,batteryless-platform;
            qcom,charger-temp-max = <0x320>;
            qcom,hvdcp2-12v-max-icl-ua = <0x16E360>;
            qcom,hvdcp2-max-icl-ua = <0x1E8480>;
            qcom,sec-charger-config = <0x0>;
            qcom,step-charging-enable;
            qcom,suspend-input-on-debug-batt;
            qcom,sw-jeita-enable;
            qcom,thermal-mitigation = <0x5ACA30 0x5265C0 0x4C4B40 0x44AA20 0x3D0900 0x387520 0x3567E0 0x2DC6C0 0x2AB980 0x2625A0 0x1E8480 0x16E360 0xF4240 0xC3500 0x7A120 0x55730 0xC3500 0xC3500>;
            status = "ok";
            qcom,batif@1200 {
                interrupt-names = "bat-temp", "bat-ov", "bat-low", "bat-therm-or-id-missing", "bat-terminal-missing", "buck-oc", "vph-ov";
                interrupts = <0x2 0x12 0x0 0x1 0x2 0x12 0x2 0x3 0x2 0x12 0x3 0x3 0x2 0x12 0x4 0x3 0x2 0x12 0x5 0x3 0x2 0x12 0x6 0x3 0x2 0x12 0x7 0x3>;
                reg = <0x1200>;
            };
            qcom,chg-sdam@b000 {
                reg = <0xB000>;
            };
            qcom,chgr@1000 {
                interrupt-names = "chgr-error", "chg-state-change", "step-chg-state-change", "step-chg-soc-update-fail", "step-chg-soc-update-req", "fg-fvcal-qualified", "vph-alarm", "vph-drop-prechg";
                interrupts = <0x2 0x10 0x0 0x1 0x2 0x10 0x1 0x1 0x2 0x10 0x2 0x1 0x2 0x10 0x3 0x1 0x2 0x10 0x4 0x1 0x2 0x10 0x5 0x1 0x2 0x10 0x6 0x1 0x2 0x10 0x7 0x1>;
                reg = <0x1000>;
            };
            qcom,dc@1400 {
                interrupt-names = "dcin-vashdn", "dcin-uv", "dcin-ov", "dcin-plugin", "dcin-revi", "dcin-pon", "dcin-en";
                interrupts = <0x2 0x14 0x1 0x3 0x2 0x14 0x2 0x3 0x2 0x14 0x3 0x3 0x2 0x14 0x4 0x3 0x2 0x14 0x5 0x3 0x2 0x14 0x6 0x1 0x2 0x14 0x7 0x1>;
                reg = <0x1400>;
            };
            qcom,dcdc@1100 {
                interrupt-names = "otg-fail", "otg-oc-disable-sw", "otg-oc-hiccup", "bsm-active", "high-duty-cycle", "input-current-limiting", "concurrent-mode-disable", "switcher-power-ok";
                interrupts = <0x2 0x11 0x0 0x1 0x2 0x11 0x1 0x1 0x2 0x11 0x2 0x1 0x2 0x11 0x3 0x3 0x2 0x11 0x4 0x3 0x2 0x11 0x5 0x3 0x2 0x11 0x6 0x1 0x2 0x11 0x7 0x3>;
                reg = <0x1100>;
            };
            qcom,misc@1600 {
                interrupt-names = "wdog-snarl", "wdog-bark", "aicl-fail", "aicl-done", "smb-en", "imp-trigger", "temp-change", "temp-change-smb";
                interrupts = <0x2 0x16 0x0 0x1 0x2 0x16 0x1 0x1 0x2 0x16 0x2 0x1 0x2 0x16 0x3 0x1 0x2 0x16 0x4 0x3 0x2 0x16 0x5 0x1 0x2 0x16 0x6 0x1 0x2 0x16 0x7 0x1>;
                reg = <0x1600>;
            };
            smb5_vbus: qcom,smb5-vbus {
                regulator-name = "smb5-vbus";
            };
            smb5_vconn: qcom,smb5-vconn {
                regulator-name = "smb5-vconn";
            };
            qcom,typec@1500 {
                interrupt-names = "typec-or-rid-detect-change", "typec-vpd-detect", "typec-cc-state-change", "typec-vconn-oc", "typec-vbus-change", "typec-attach-detach", "typec-legacy-cable-detect", "typec-try-snk-src-detect";
                interrupts = <0x2 0x15 0x0 0x1 0x2 0x15 0x1 0x1 0x2 0x15 0x2 0x1 0x2 0x15 0x3 0x1 0x2 0x15 0x4 0x1 0x2 0x15 0x5 0x1 0x2 0x15 0x6 0x1 0x2 0x15 0x7 0x1>;
                reg = <0x1500>;
            };
            qcom,usb@1300 {
                interrupt-names = "usbin-collapse", "usbin-vashdn", "usbin-uv", "usbin-ov", "usbin-plugin", "usbin-revi-change", "usbin-src-change", "usbin-icl-change";
                interrupts = <0x2 0x13 0x0 0x3 0x2 0x13 0x1 0x3 0x2 0x13 0x2 0x3 0x2 0x13 0x3 0x3 0x2 0x13 0x4 0x3 0x2 0x13 0x5 0x3 0x2 0x13 0x6 0x1 0x2 0x13 0x7 0x1>;
                reg = <0x1300>;
            };
        };
        pm7250b_tz: qcom,temp-alarm@2400 {
            #thermal-sensor-cells = <0x0>;
            compatible = "qcom,spmi-temp-alarm";
            interrupts = <0x2 0x24 0x0 0x3>;
            io-channel-names = "thermal";
            io-channels = <&pm7250b_vadc 0x6>;
            qcom,temperature-threshold-set = <0x1>;
            reg = <0x2400>;
        };
        pm7250b_pdphy: qcom,usb-pdphy@1700 {
            #io-channel-cells = <0x1>;
            compatible = "qcom,qpnp-pdphy";
            interrupt-names = "sig-tx", "sig-rx", "msg-tx", "msg-rx", "msg-tx-failed", "msg-tx-discarded", "msg-rx-discarded", "fr-swap";
            interrupts = <0x2 0x17 0x0 0x1 0x2 0x17 0x1 0x1 0x2 0x17 0x2 0x1 0x2 0x17 0x3 0x1 0x2 0x17 0x4 0x1 0x2 0x17 0x5 0x1 0x2 0x17 0x6 0x1 0x2 0x17 0x7 0x1>;
            qcom,default-sink-caps = <0x1388 0xBB8 0x2328 0xBB8 0x2EE0 0x8CA>;
            reg = <0x1700>;
            vbus-supply = <&smb5_vbus>;
            vconn-supply = <&smb5_vconn>;
            vdd-pdphy-supply = <&L15A>;
        };
        pm7250b_qg: qpnp,qg {
            #address-cells = <0x1>;
            #size-cells = <0x1>;
            compatible = "qcom,pm7250b-qg";
            depends-on-supply = <&pm6125_rtc>;
            io-channel-names = "batt-therm", "batt-id";
            io-channels = <&pm7250b_vadc 0x2A &pm7250b_vadc 0x4B>;
            qcom,cl-feedback-on;
            qcom,hold-soc-while-full;
            qcom,linearize-soc;
            qcom,qg-iterm-ma = <0x96>;
            qcom,s3-entry-fifo-length = <0x2>;
            qcom,soc_decimal_rate = <0x0 0x20 0xA 0x1E 0x14 0x1C 0x1E 0x1C 0x28 0x1C 0x32 0x1C 0x3C 0x1C 0x46 0x1C 0x50 0x1C 0x5A 0x1A 0x5F 0xA 0x63 0x5>;
            qcom,vbatt-cutoff-mv = <0xC80>;
            qcom,vbatt-empty-cold-mv = <0xBB8>;
            qcom,vbatt-empty-mv = <0xBB8>;
            qcom,vbatt-low-cold-mv = <0xE74>;
            qcom,vbatt-low-mv = <0xCE4>;
            status = "ok";
            qcom,qg-sdam@b100 {
                reg = <0xB100>;
                status = "okay";
            };
            qcom,qgauge@4800 {
                interrupt-names = "qg-batt-missing", "qg-vbat-low", "qg-vbat-empty", "qg-fifo-done", "qg-good-ocv";
                interrupts = <0x2 0x48 0x0 0x3 0x2 0x48 0x1 0x3 0x2 0x48 0x2 0x1 0x2 0x48 0x3 0x1 0x2 0x48 0x4 0x1>;
                reg = <0x4800>;
                status = "okay";
            };
        };
        pm7250b_vadc: vadc@3100 {
            #address-cells = <0x1>;
            #io-channel-cells = <0x1>;
            #size-cells = <0x0>;
            compatible = "qcom,spmi-adc5";
            interrupt-names = "eoc-int-en-set";
            interrupts = <0x2 0x31 0x0 0x1>;
            io-channel-ranges;
            qcom,adc-vdd-reference = <0x753>;
            reg = <0x3100>;
            reg-names = "adc5-usr-base";
            bat_id@4b {
                label = "bat_id";
                qcom,hw-settle-time = <0xC8>;
                qcom,pre-scaling = <0x1 0x1>;
                qcom,ratiometric;
                reg = <0x4B>;
            };
            bat_therm@4a {
                label = "bat_therm";
                qcom,hw-settle-time = <0xC8>;
                qcom,pre-scaling = <0x1 0x1>;
                qcom,ratiometric;
                reg = <0x4A>;
            };
            bat_therm_30k@2a {
                label = "bat_therm_30k";
                qcom,hw-settle-time = <0xC8>;
                qcom,pre-scaling = <0x1 0x1>;
                qcom,ratiometric;
                reg = <0x2A>;
            };
            bat_therm_400k@6a {
                label = "bat_therm_400k";
                qcom,hw-settle-time = <0xC8>;
                qcom,pre-scaling = <0x1 0x1>;
                qcom,ratiometric;
                reg = <0x6A>;
            };
            charger_skin_therm@4d {
                label = "charger_skin_therm";
                qcom,hw-settle-time = <0xC8>;
                qcom,pre-scaling = <0x1 0x1>;
                qcom,ratiometric;
                reg = <0x4D>;
            };
            chg_sbux@99 {
                label = "chg_sbux";
                qcom,pre-scaling = <0x1 0x3>;
                reg = <0x99>;
            };
            chg_temp@9 {
                label = "chg_temp";
                qcom,pre-scaling = <0x1 0x1>;
                reg = <0x9>;
            };
            conn_therm@4f {
                label = "conn_therm";
                qcom,hw-settle-time = <0xC8>;
                qcom,pre-scaling = <0x1 0x1>;
                qcom,ratiometric;
                reg = <0x4F>;
            };
            die_temp@2 {
                label = "die_temp";
                qcom,pre-scaling = <0x1 0x1>;
                reg = <0x6>;
            };
            mid_chg_div6@1e {
                label = "chg_mid";
                qcom,pre-scaling = <0x1 0x6>;
                reg = <0x1E>;
            };
            ref_gnd@0 {
                label = "ref_gnd";
                qcom,pre-scaling = <0x1 0x1>;
                reg = <0x0>;
            };
            smb1390_therm@e {
                label = "smb1390_therm";
                qcom,hw-settle-time = <0xC8>;
                qcom,pre-scaling = <0x1 0x1>;
                reg = <0xE>;
            };
            usb_in_i_uv@7 {
                label = "usb_in_i_uv";
                qcom,pre-scaling = <0x1 0x1>;
                reg = <0x7>;
            };
            usb_in_v_div_16@8 {
                label = "usb_in_v_div_16";
                qcom,pre-scaling = <0x1 0x10>;
                reg = <0x8>;
            };
            vbat_sns@84 {
                label = "vbat_sns";
                qcom,pre-scaling = <0x1 0x3>;
                reg = <0x84>;
            };
            vph_pwr@83 {
                label = "vph_pwr";
                qcom,pre-scaling = <0x1 0x3>;
                reg = <0x83>;
            };
            vref_1p25@1 {
                label = "vref_1p25";
                qcom,pre-scaling = <0x1 0x1>;
                reg = <0x1>;
            };
        };
    };
    qcom,pm7250b@3 {
        #address-cells = <0x1>;
        #size-cells = <0x0>;
        compatible = "qcom,spmi-pmic";
        reg = <0x3 0x0>;
        pm7250b_vib: qcom,vibrator@5300 {
            compatible = "qcom,qpnp-vibrator-ldo";
            qcom,disable-overdrive;
            qcom,vib-ldo-volt-uv = <0x2DC6C0>;
            reg = <0x5300>;
        };
    };
};

&thermal_zones {
    charger-therm-usr {
        polling-delay = <0x0>;
        polling-delay-passive = <0x0>;
        thermal-governor = "user_space";
        thermal-sensors = <&pm7250b_adc_tm 0x0>;
        wake-capable-sensor;
        trips {
            active-config0 {
                hysteresis = <0x3E8>;
                temperature = <0x1E848>;
                type = "passive";
            };
        };
    };
    conn-therm-usr {
        polling-delay = <0x0>;
        polling-delay-passive = <0x0>;
        thermal-governor = "user_space";
        thermal-sensors = <&pm7250b_adc_tm 0x1>;
        wake-capable-sensor;
        trips {
            active-config0 {
                hysteresis = <0x3E8>;
                temperature = <0x1E848>;
                type = "passive";
            };
        };
    };
    pm7250b-bcl-lvl0 {
        polling-delay = <0x0>;
        polling-delay-passive = <0x64>;
        thermal-sensors = <&pm7250b_bcl 0x5>;
        trips {
            b_bcl_lvl0: b-bcl-lvl0 {
                hysteresis = <0x1>;
                temperature = <0x1>;
                type = "passive";
            };
        };
    };
    pm7250b-bcl-lvl1 {
        polling-delay = <0x0>;
        polling-delay-passive = <0x64>;
        thermal-sensors = <&pm7250b_bcl 0x6>;
        trips {
            b_bcl_lvl1: b-bcl-lvl1 {
                hysteresis = <0x1>;
                temperature = <0x1>;
                type = "passive";
            };
        };
    };
    pm7250b-bcl-lvl2 {
        polling-delay = <0x0>;
        polling-delay-passive = <0x64>;
        thermal-sensors = <&pm7250b_bcl 0x7>;
        trips {
            b_bcl_lvl2: b-bcl-lvl2 {
                hysteresis = <0x1>;
                temperature = <0x1>;
                type = "passive";
            };
        };
    };
    pm7250b-ibat-lvl0 {
        polling-delay = <0x0>;
        polling-delay-passive = <0x0>;
        thermal-sensors = <&pm7250b_bcl 0x0>;
        trips {
            ibat_lvl0: ibat-lvl0 {
                hysteresis = <0xC8>;
                temperature = <0x157C>;
                type = "passive";
            };
        };
    };
    pm7250b-ibat-lvl1 {
        polling-delay = <0x0>;
        polling-delay-passive = <0x0>;
        thermal-sensors = <&pm7250b_bcl 0x1>;
        trips {
            ibat_lvl1: ibat-lvl1 {
                hysteresis = <0xC8>;
                temperature = <0x1770>;
                type = "passive";
            };
        };
    };
    pm7250b_temp_alarm: pm7250b-tz {
        polling-delay = <0x0>;
        polling-delay-passive = <0x64>;
        thermal-sensors = <&pm7250b_tz>;
        trips {
            pm7250b_trip0: trip0 {
                hysteresis = <0x0>;
                temperature = <0x17318>;
                type = "passive";
            };
            pm7250b_trip1: trip1 {
                hysteresis = <0x0>;
                temperature = <0x1C138>;
                type = "passive";
            };
            trip2 {
                hysteresis = <0x0>;
                temperature = <0x23668>;
                type = "passive";
            };
        };
    };
    rf-pa1-therm-usr {
        polling-delay = <0x0>;
        polling-delay-passive = <0x0>;
        thermal-governor = "user_space";
        thermal-sensors = <&pm6125_adc_tm 0x3>;
        wake-capable-sensor;
        trips {
            active-config0 {
                hysteresis = <0x3E8>;
                temperature = <0x1E848>;
                type = "passive";
            };
        };
    };
    socd {
        polling-delay = <0x0>;
        polling-delay-passive = <0x64>;
        trips {
            soc_trip: soc-trip {
                hysteresis = <0x0>;
                temperature = <0x5A>;
                type = "passive";
            };
            thermal-engine-trip {
                hysteresis = <0x0>;
                temperature = <0x64>;
                type = "passive";
            };
            thermal-hal-trip {
                hysteresis = <0x0>;
                temperature = <0x64>;
                type = "passive";
            };
        };
    };
};

&ufshc_mem {
    qcom,vddp-ref-clk-max-microamp = <0x64>;
    qcom,vddp-ref-clk-supply = <&L18A>;
    reset-gpios = <&tlmm 0x71 0x1>;
    reset-names = "rst";
    resets = <&gcc 0x4>;
    status = "ok";
    vcc-max-microamp = "\f5";
    vcc-supply = <&L24A>;
    vccq2-max-microamp = "\f5";
    vccq2-supply = <&L11A>;
    vdd-hba-fixed-regulator;
    vdd-hba-supply = <&gcc_ufs_phy_gdsc>;
};

&ufsphy_mem {
    compatible = "qcom,ufs-phy-qmp-v4-khaje";
    status = "ok";
    vdda-phy-max-microamp = <0x14EC4>;
    vdda-phy-supply = <&L4A>;
    vdda-pll-max-microamp = <0x477C>;
    vdda-pll-supply = <&L18A>;
};

&usb0 {
    extcon = <&pm7250b_pdphy &pm7250b_charger &eud>;
};

&usb_qmp_dp_phy {
    vdd-supply = <&vdda_usb_ss_dp_core>;
};

